VERSION "6.2.2"

NS_ :

BS_:

BU_:

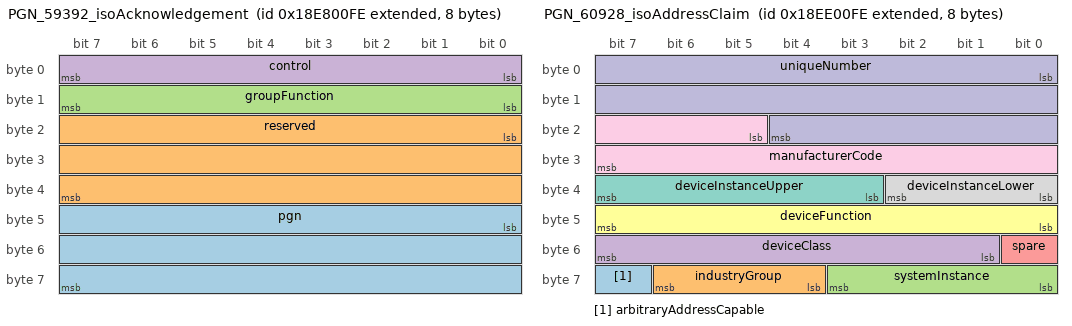
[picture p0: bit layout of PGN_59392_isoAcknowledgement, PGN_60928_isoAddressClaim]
BO_ 2565341438 PGN_59392_isoAcknowledgement: 8 Vector__XXX
 SG_ pgn : 40|24@1+ (1,0) [0|0] "" Vector__XXX
 SG_ reserved : 16|24@1+ (1,0) [0|0] "" Vector__XXX
 SG_ groupFunction : 8|8@1+ (1,0) [0|0] "" Vector__XXX
 SG_ control : 0|8@1+ (1,0) [0|0] "" Vector__XXX

BO_ 2565472510 PGN_59904_isoRequest: 8 Vector__XXX
 SG_ pgn : 0|24@1+ (1,0) [0|0] "" Vector__XXX

BO_ 2565538046 PGN_60160_isoTransportProtocolDa: 8 Vector__XXX
 SG_ data : 8|56@1+ (1,0) [0|0] "" Vector__XXX
 SG_ sid : 0|8@1+ (1,0) [0|0] "" Vector__XXX

BO_ 2565734654 PGN_60928_isoAddressClaim: 8 Vector__XXX
 SG_ arbitraryAddressCapable : 63|1@1+ (1,0) [0|0] "" Vector__XXX
 SG_ industryGroup : 60|3@1+ (1,0) [0|0] "" Vector__XXX
 SG_ systemInstance : 56|4@1+ (1,0) [0|0] "" Vector__XXX
 SG_ deviceClass : 49|7@1+ (1,0) [0|0] "" Vector__XXX
 SG_ spare : 48|1@1+ (1,0) [0|0] "" Vector__XXX
 SG_ deviceFunction : 40|8@1+ (1,0) [0|0] "" Vector__XXX
 SG_ deviceInstanceUpper : 35|5@1+ (1,0) [0|0] "" Vector__XXX
 SG_ deviceInstanceLower : 32|3@1+ (1,0) [0|0] "" Vector__XXX
 SG_ manufacturerCode : 21|11@1+ (1,0) [0|0] "" Vector__XXX
 SG_ uniqueNumber : 0|21@1+ (1,0) [0|0] "" Vector__XXX

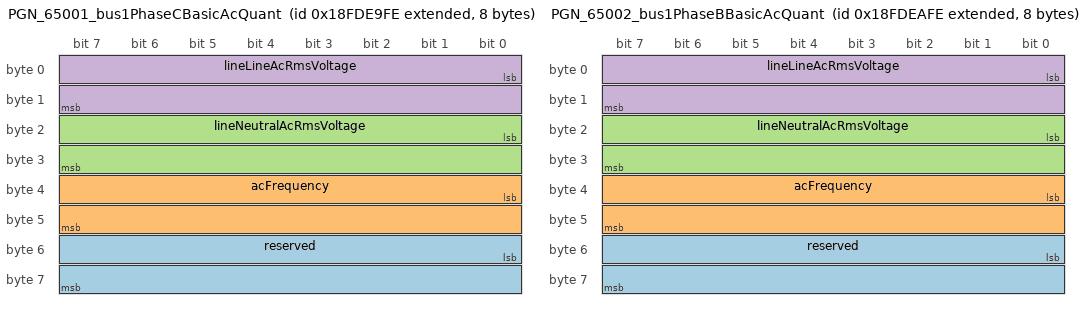
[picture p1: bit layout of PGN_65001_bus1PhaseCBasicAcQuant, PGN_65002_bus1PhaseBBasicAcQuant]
BO_ 2566777342 PGN_65001_bus1PhaseCBasicAcQuant: 8 Vector__XXX
 SG_ reserved : 48|16@1+ (1,0) [0|0] "" Vector__XXX
 SG_ acFrequency : 32|16@1+ (0.0078125,0) [0|0] "Hz" Vector__XXX
 SG_ lineNeutralAcRmsVoltage : 16|16@1+ (1,0) [0|0] "V" Vector__XXX
 SG_ lineLineAcRmsVoltage : 0|16@1+ (1,0) [0|0] "V" Vector__XXX

BO_ 2566777598 PGN_65002_bus1PhaseBBasicAcQuant: 8 Vector__XXX
 SG_ reserved : 48|16@1+ (1,0) [0|0] "" Vector__XXX
 SG_ acFrequency : 32|16@1+ (0.0078125,0) [0|0] "Hz" Vector__XXX
 SG_ lineNeutralAcRmsVoltage : 16|16@1+ (1,0) [0|0] "V" Vector__XXX
 SG_ lineLineAcRmsVoltage : 0|16@1+ (1,0) [0|0] "V" Vector__XXX

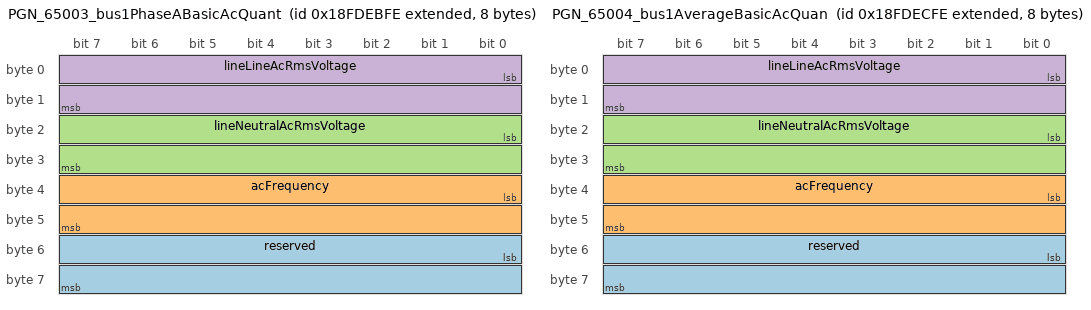
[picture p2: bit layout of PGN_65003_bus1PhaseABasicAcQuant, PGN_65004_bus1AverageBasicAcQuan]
BO_ 2566777854 PGN_65003_bus1PhaseABasicAcQuant: 8 Vector__XXX
 SG_ reserved : 48|16@1+ (1,0) [0|0] "" Vector__XXX
 SG_ acFrequency : 32|16@1+ (0.0078125,0) [0|0] "Hz" Vector__XXX
 SG_ lineNeutralAcRmsVoltage : 16|16@1+ (1,0) [0|0] "V" Vector__XXX
 SG_ lineLineAcRmsVoltage : 0|16@1+ (1,0) [0|0] "V" Vector__XXX

BO_ 2566778110 PGN_65004_bus1AverageBasicAcQuan: 8 Vector__XXX
 SG_ reserved : 48|16@1+ (1,0) [0|0] "" Vector__XXX
 SG_ acFrequency : 32|16@1+ (0.0078125,0) [0|0] "Hz" Vector__XXX
 SG_ lineNeutralAcRmsVoltage : 16|16@1+ (1,0) [0|0] "V" Vector__XXX
 SG_ lineLineAcRmsVoltage : 0|16@1+ (1,0) [0|0] "V" Vector__XXX

BO_ 2566778366 PGN_65005_utilityTotalAcEnergy: 8 Vector__XXX
 SG_ totalEnergyImport : 32|32@1+ (1,0) [0|0] "kWh" Vector__XXX
 SG_ totalEnergyExport : 0|32@1+ (1,0) [0|0] "kWh" Vector__XXX

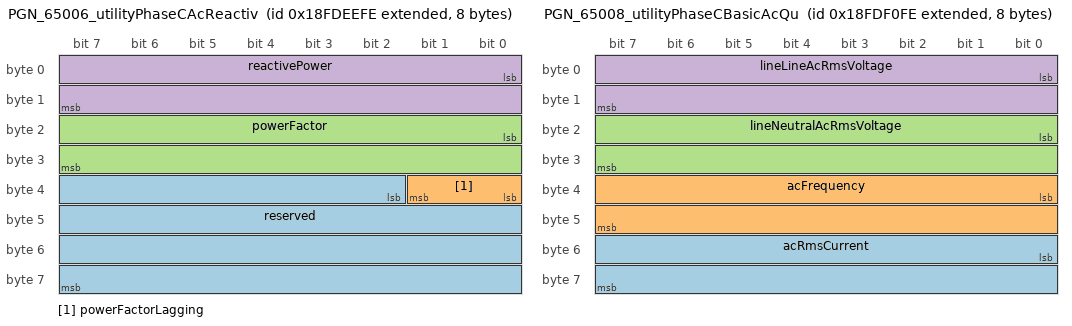
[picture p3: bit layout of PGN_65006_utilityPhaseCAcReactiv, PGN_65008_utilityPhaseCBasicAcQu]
BO_ 2566778622 PGN_65006_utilityPhaseCAcReactiv: 8 Vector__XXX
 SG_ reserved : 34|30@1+ (1,0) [0|0] "" Vector__XXX
 SG_ powerFactorLagging : 32|2@1+ (1,0) [0|0] "" Vector__XXX
 SG_ powerFactor : 16|16@1+ (6.10352e-05,0) [0|0] "Cos Phi" Vector__XXX
 SG_ reactivePower : 0|16@1+ (1,0) [0|0] "VAR" Vector__XXX

BO_ 2566778878 PGN_65007_utilityPhaseCAcPower: 8 Vector__XXX
 SG_ apparentPower : 32|32@1- (1,0) [0|0] "VA" Vector__XXX
 SG_ realPower : 0|32@1- (1,0) [0|0] "W" Vector__XXX

BO_ 2566779134 PGN_65008_utilityPhaseCBasicAcQu: 8 Vector__XXX
 SG_ acRmsCurrent : 48|16@1+ (1,0) [0|0] "A" Vector__XXX
 SG_ acFrequency : 32|16@1+ (0.0078125,0) [0|0] "Hz" Vector__XXX
 SG_ lineNeutralAcRmsVoltage : 16|16@1+ (1,0) [0|0] "V" Vector__XXX
 SG_ lineLineAcRmsVoltage : 0|16@1+ (1,0) [0|0] "V" Vector__XXX

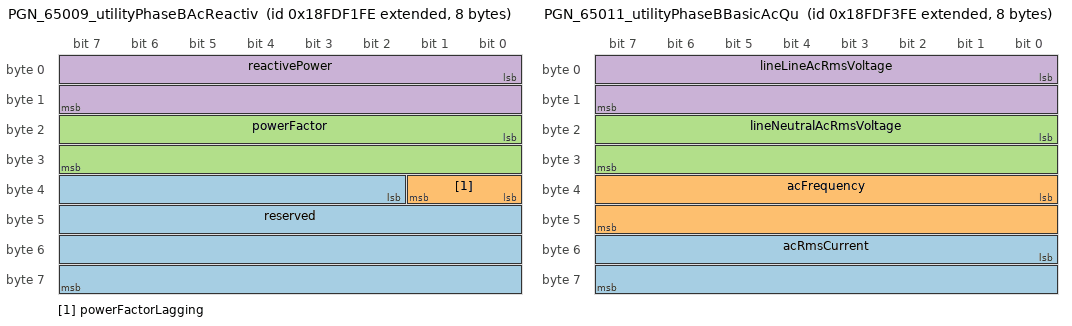
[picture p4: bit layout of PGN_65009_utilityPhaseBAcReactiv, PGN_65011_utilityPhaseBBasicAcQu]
BO_ 2566779390 PGN_65009_utilityPhaseBAcReactiv: 8 Vector__XXX
 SG_ reserved : 34|30@1+ (1,0) [0|0] "" Vector__XXX
 SG_ powerFactorLagging : 32|2@1+ (1,0) [0|0] "" Vector__XXX
 SG_ powerFactor : 16|16@1+ (6.10352e-05,0) [0|0] "Cos Phi" Vector__XXX
 SG_ reactivePower : 0|16@1+ (1,0) [0|0] "VAR" Vector__XXX

BO_ 2566779646 PGN_65010_utilityPhaseBAcPower: 8 Vector__XXX
 SG_ apparentPower : 32|32@1- (1,0) [0|0] "VA" Vector__XXX
 SG_ realPower : 0|32@1- (1,0) [0|0] "W" Vector__XXX

BO_ 2566779902 PGN_65011_utilityPhaseBBasicAcQu: 8 Vector__XXX
 SG_ acRmsCurrent : 48|16@1+ (1,0) [0|0] "A" Vector__XXX
 SG_ acFrequency : 32|16@1+ (0.0078125,0) [0|0] "Hz" Vector__XXX
 SG_ lineNeutralAcRmsVoltage : 16|16@1+ (1,0) [0|0] "V" Vector__XXX
 SG_ lineLineAcRmsVoltage : 0|16@1+ (1,0) [0|0] "V" Vector__XXX

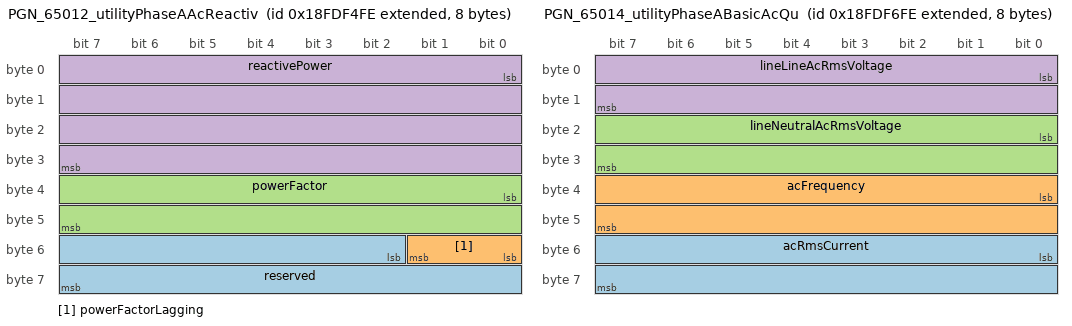
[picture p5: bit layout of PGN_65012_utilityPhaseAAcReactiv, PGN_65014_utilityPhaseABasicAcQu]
BO_ 2566780158 PGN_65012_utilityPhaseAAcReactiv: 8 Vector__XXX
 SG_ reserved : 50|14@1+ (1,0) [0|0] "" Vector__XXX
 SG_ powerFactorLagging : 48|2@1+ (1,0) [0|0] "" Vector__XXX
 SG_ powerFactor : 32|16@1+ (6.10352e-05,0) [0|0] "Cos Phi" Vector__XXX
 SG_ reactivePower : 0|32@1- (1,0) [0|0] "VAR" Vector__XXX

BO_ 2566780414 PGN_65013_utilityPhaseAAcPower: 8 Vector__XXX
 SG_ apparentPower : 32|32@1- (1,0) [0|0] "VA" Vector__XXX
 SG_ realPower : 0|32@1- (1,0) [0|0] "W" Vector__XXX

BO_ 2566780670 PGN_65014_utilityPhaseABasicAcQu: 8 Vector__XXX
 SG_ acRmsCurrent : 48|16@1+ (1,0) [0|0] "A" Vector__XXX
 SG_ acFrequency : 32|16@1+ (0.0078125,0) [0|0] "Hz" Vector__XXX
 SG_ lineNeutralAcRmsVoltage : 16|16@1+ (1,0) [0|0] "V" Vector__XXX
 SG_ lineLineAcRmsVoltage : 0|16@1+ (1,0) [0|0] "V" Vector__XXX

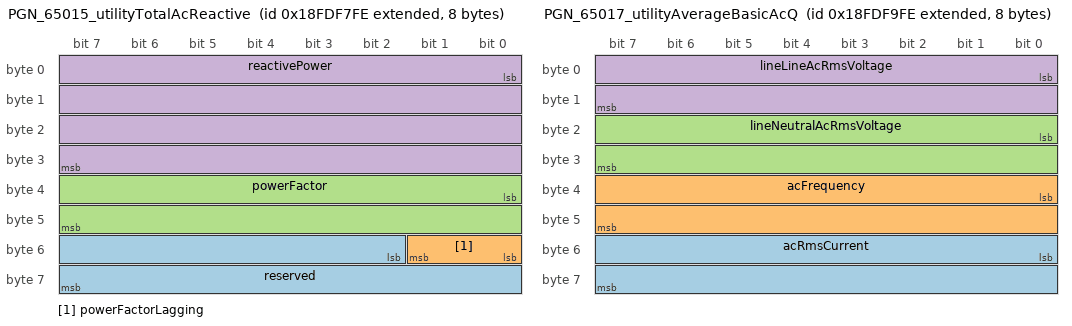
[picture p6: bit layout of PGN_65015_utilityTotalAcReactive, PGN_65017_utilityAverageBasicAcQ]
BO_ 2566780926 PGN_65015_utilityTotalAcReactive: 8 Vector__XXX
 SG_ reserved : 50|14@1+ (1,0) [0|0] "" Vector__XXX
 SG_ powerFactorLagging : 48|2@1+ (1,0) [0|0] "" Vector__XXX
 SG_ powerFactor : 32|16@1+ (6.10352e-05,0) [0|0] "Cos Phi" Vector__XXX
 SG_ reactivePower : 0|32@1- (1,0) [0|0] "VAR" Vector__XXX

BO_ 2566781182 PGN_65016_utilityTotalAcPower: 8 Vector__XXX
 SG_ apparentPower : 32|32@1- (1,0) [0|0] "VA" Vector__XXX
 SG_ realPower : 0|32@1- (1,0) [0|0] "W" Vector__XXX

BO_ 2566781438 PGN_65017_utilityAverageBasicAcQ: 8 Vector__XXX
 SG_ acRmsCurrent : 48|16@1+ (1,0) [0|0] "A" Vector__XXX
 SG_ acFrequency : 32|16@1+ (0.0078125,0) [0|0] "Hz" Vector__XXX
 SG_ lineNeutralAcRmsVoltage : 16|16@1+ (1,0) [0|0] "V" Vector__XXX
 SG_ lineLineAcRmsVoltage : 0|16@1+ (1,0) [0|0] "V" Vector__XXX

BO_ 2566781694 PGN_65018_generatorTotalAcEnergy: 8 Vector__XXX
 SG_ totalEnergyImport : 32|32@1+ (1,0) [0|0] "kWh" Vector__XXX
 SG_ totalEnergyExport : 0|32@1+ (1,0) [0|0] "kWh" Vector__XXX

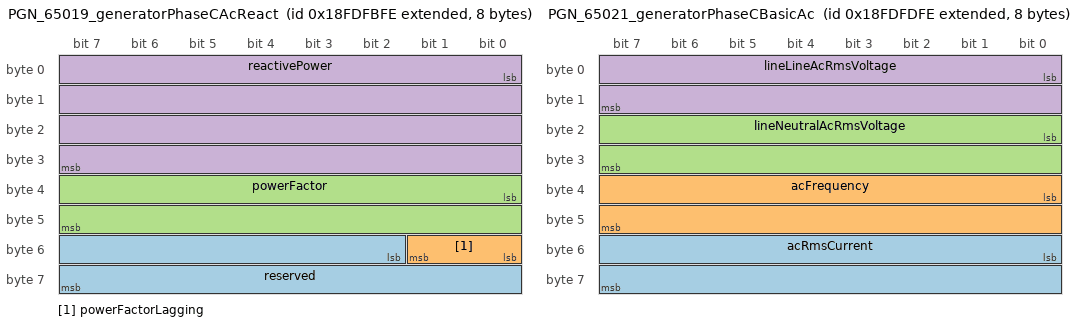
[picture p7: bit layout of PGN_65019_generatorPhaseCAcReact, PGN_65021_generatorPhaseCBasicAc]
BO_ 2566781950 PGN_65019_generatorPhaseCAcReact: 8 Vector__XXX
 SG_ reserved : 50|14@1+ (1,0) [0|0] "" Vector__XXX
 SG_ powerFactorLagging : 48|2@1+ (1,0) [0|0] "" Vector__XXX
 SG_ powerFactor : 32|16@1+ (6.10352e-05,0) [0|0] "Cos Phi" Vector__XXX
 SG_ reactivePower : 0|32@1- (1,0) [0|0] "VAR" Vector__XXX

BO_ 2566782206 PGN_65020_generatorPhaseCAcPower: 8 Vector__XXX
 SG_ apparentPower : 32|32@1- (1,0) [0|0] "VAR" Vector__XXX
 SG_ realPower : 0|32@1- (1,0) [0|0] "W" Vector__XXX

BO_ 2566782462 PGN_65021_generatorPhaseCBasicAc: 8 Vector__XXX
 SG_ acRmsCurrent : 48|16@1+ (1,0) [0|0] "A" Vector__XXX
 SG_ acFrequency : 32|16@1+ (0.0078125,0) [0|0] "Hz" Vector__XXX
 SG_ lineNeutralAcRmsVoltage : 16|16@1+ (1,0) [0|0] "V" Vector__XXX
 SG_ lineLineAcRmsVoltage : 0|16@1+ (1,0) [0|0] "V" Vector__XXX

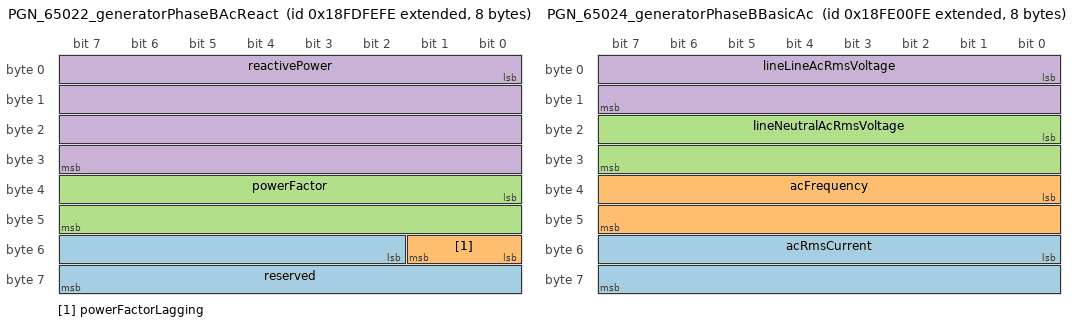
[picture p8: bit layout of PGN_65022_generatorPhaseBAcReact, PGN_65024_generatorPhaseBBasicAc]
BO_ 2566782718 PGN_65022_generatorPhaseBAcReact: 8 Vector__XXX
 SG_ reserved : 50|14@1+ (1,0) [0|0] "" Vector__XXX
 SG_ powerFactorLagging : 48|2@1+ (1,0) [0|0] "" Vector__XXX
 SG_ powerFactor : 32|16@1+ (6.10352e-05,0) [0|0] "Cos Phi" Vector__XXX
 SG_ reactivePower : 0|32@1- (1,0) [0|0] "VAR" Vector__XXX

BO_ 2566782974 PGN_65023_generatorPhaseBAcPower: 8 Vector__XXX
 SG_ apparentPower : 32|32@1- (1,0) [0|0] "VA" Vector__XXX
 SG_ realPower : 0|32@1- (1,0) [0|0] "W" Vector__XXX

BO_ 2566783230 PGN_65024_generatorPhaseBBasicAc: 8 Vector__XXX
 SG_ acRmsCurrent : 48|16@1+ (1,0) [0|0] "A" Vector__XXX
 SG_ acFrequency : 32|16@1+ (0.0078125,0) [0|0] "Hz" Vector__XXX
 SG_ lineNeutralAcRmsVoltage : 16|16@1+ (1,0) [0|0] "V" Vector__XXX
 SG_ lineLineAcRmsVoltage : 0|16@1+ (1,0) [0|0] "V" Vector__XXX

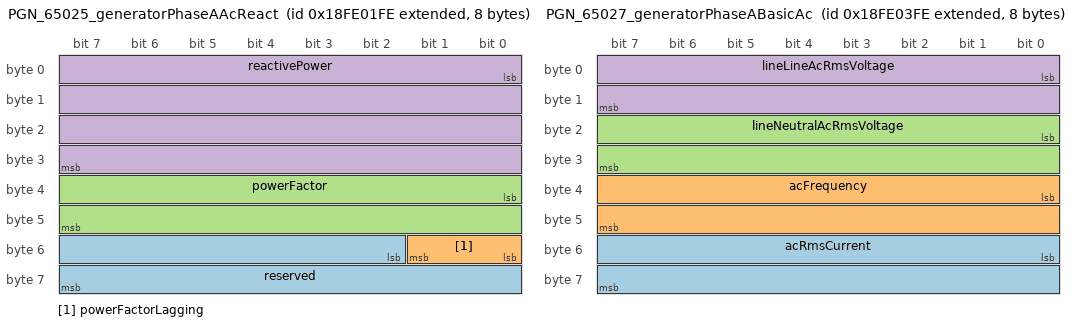
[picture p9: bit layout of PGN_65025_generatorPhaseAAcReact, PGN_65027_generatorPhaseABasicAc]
BO_ 2566783486 PGN_65025_generatorPhaseAAcReact: 8 Vector__XXX
 SG_ reserved : 50|14@1+ (1,0) [0|0] "" Vector__XXX
 SG_ powerFactorLagging : 48|2@1+ (1,0) [0|0] "" Vector__XXX
 SG_ powerFactor : 32|16@1+ (6.10352e-05,0) [0|0] "Cos Phi" Vector__XXX
 SG_ reactivePower : 0|32@1- (1,0) [0|0] "VAR" Vector__XXX

BO_ 2566783742 PGN_65026_generatorPhaseAAcPower: 8 Vector__XXX
 SG_ apparentPower : 32|32@1- (1,0) [0|0] "VA" Vector__XXX
 SG_ realPower : 0|32@1- (1,0) [0|0] "W" Vector__XXX

BO_ 2566783998 PGN_65027_generatorPhaseABasicAc: 8 Vector__XXX
 SG_ acRmsCurrent : 48|16@1+ (1,0) [0|0] "A" Vector__XXX
 SG_ acFrequency : 32|16@1+ (0.0078125,0) [0|0] "Hz" Vector__XXX
 SG_ lineNeutralAcRmsVoltage : 16|16@1+ (1,0) [0|0] "V" Vector__XXX
 SG_ lineLineAcRmsVoltage : 0|16@1+ (1,0) [0|0] "V" Vector__XXX

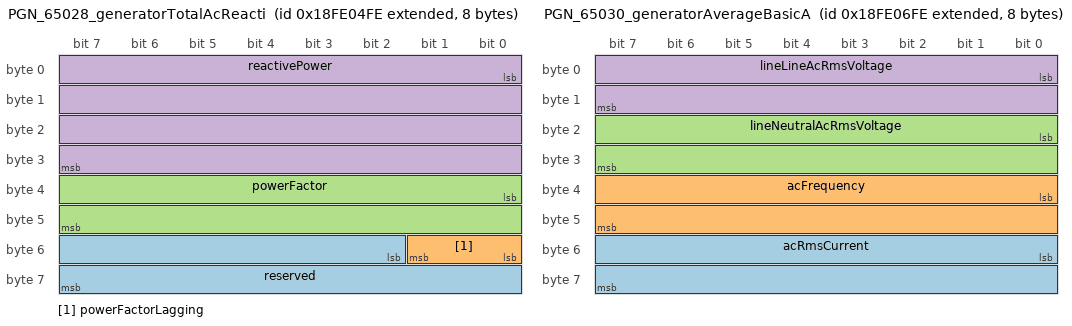
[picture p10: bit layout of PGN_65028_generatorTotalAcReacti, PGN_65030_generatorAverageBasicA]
BO_ 2566784254 PGN_65028_generatorTotalAcReacti: 8 Vector__XXX
 SG_ reserved : 50|14@1+ (1,0) [0|0] "" Vector__XXX
 SG_ powerFactorLagging : 48|2@1+ (1,0) [0|0] "" Vector__XXX
 SG_ powerFactor : 32|16@1+ (6.10352e-05,0) [0|0] "Cos Phi" Vector__XXX
 SG_ reactivePower : 0|32@1- (1,0) [0|0] "VAR" Vector__XXX

BO_ 2566784510 PGN_65029_generatorTotalAcPower: 8 Vector__XXX
 SG_ apparentPower : 32|32@1- (1,0) [0|0] "VA" Vector__XXX
 SG_ realPower : 0|32@1- (1,0) [0|0] "W" Vector__XXX

BO_ 2566784766 PGN_65030_generatorAverageBasicA: 8 Vector__XXX
 SG_ acRmsCurrent : 48|16@1+ (1,0) [0|0] "A" Vector__XXX
 SG_ acFrequency : 32|16@1+ (0.0078125,0) [0|0] "Hz" Vector__XXX
 SG_ lineNeutralAcRmsVoltage : 16|16@1+ (1,0) [0|0] "V" Vector__XXX
 SG_ lineLineAcRmsVoltage : 0|16@1+ (1,0) [0|0] "V" Vector__XXX

BO_ 2566849534 PGN_65283_bepMarineCzoneChannelS: 8 Vector__XXX
 SG_ reserved18 : 61|3@1+ (1,0) [0|0] "" Vector__XXX
 SG_ flag : 60|1@1+ (1,0) [0|0] "" Vector__XXX
 SG_ channel5Value : 56|4@1+ (1,0) [0|0] "" Vector__XXX
 SG_ channel4Value : 52|4@1+ (1,0) [0|0] "" Vector__XXX
 SG_ channel3Value : 48|4@1+ (1,0) [0|0] "" Vector__XXX
 SG_ channel2Value : 44|4@1+ (1,0) [0|0] "" Vector__XXX
 SG_ channel1Value : 40|4@1+ (1,0) [0|0] "" Vector__XXX
 SG_ channel0Value : 36|4@1+ (1,0) [0|0] "" Vector__XXX
 SG_ channel5Mode : 34|2@1+ (1,0) [0|0] "" Vector__XXX
 SG_ channel4Mode : 32|2@1+ (1,0) [0|0] "" Vector__XXX
 SG_ channel3Mode : 30|2@1+ (1,0) [0|0] "" Vector__XXX
 SG_ channel2Mode : 28|2@1+ (1,0) [0|0] "" Vector__XXX
 SG_ channel1Mode : 26|2@1+ (1,0) [0|0] "" Vector__XXX
 SG_ channel0Mode : 24|2@1+ (1,0) [0|0] "" Vector__XXX
 SG_ dipswitch : 16|8@1+ (1,0) [0|0] "" Vector__XXX
 SG_ industryCode : 13|3@1+ (1,0) [0|0] "" Vector__XXX
 SG_ reserved : 11|2@1+ (1,0) [0|0] "" Vector__XXX
 SG_ manufacturerCode : 0|11@1+ (1,0) [0|0] "" Vector__XXX

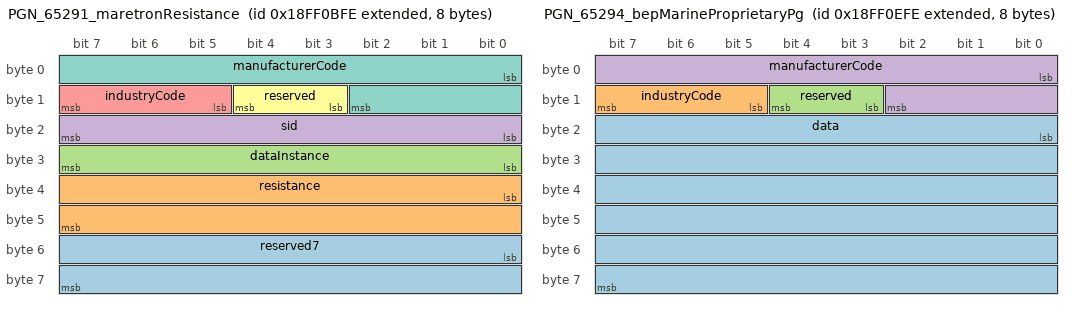
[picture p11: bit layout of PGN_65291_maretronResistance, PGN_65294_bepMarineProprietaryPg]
BO_ 2566851582 PGN_65291_maretronResistance: 8 Vector__XXX
 SG_ reserved7 : 48|16@1+ (1,0) [0|0] "" Vector__XXX
 SG_ resistance : 32|16@1+ (0.01,0) [0|0] "" Vector__XXX
 SG_ dataInstance : 24|8@1+ (1,0) [0|0] "" Vector__XXX
 SG_ sid : 16|8@1+ (1,0) [0|0] "" Vector__XXX
 SG_ industryCode : 13|3@1+ (1,0) [0|0] "" Vector__XXX
 SG_ reserved : 11|2@1+ (1,0) [0|0] "" Vector__XXX
 SG_ manufacturerCode : 0|11@1+ (1,0) [0|0] "" Vector__XXX

BO_ 2566852350 PGN_65294_bepMarineProprietaryPg: 8 Vector__XXX
 SG_ data : 16|48@1+ (1,0) [0|0] "" Vector__XXX
 SG_ industryCode : 13|3@1+ (1,0) [0|0] "" Vector__XXX
 SG_ reserved : 11|2@1+ (1,0) [0|0] "" Vector__XXX
 SG_ manufacturerCode : 0|11@1+ (1,0) [0|0] "" Vector__XXX

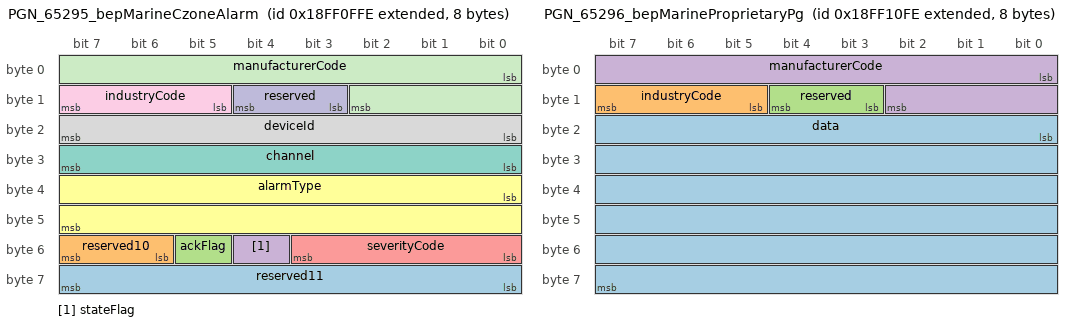
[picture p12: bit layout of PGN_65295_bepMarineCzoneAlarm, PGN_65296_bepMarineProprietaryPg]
BO_ 2566852606 PGN_65295_bepMarineCzoneAlarm: 8 Vector__XXX
 SG_ reserved11 : 56|8@1+ (1,0) [0|0] "" Vector__XXX
 SG_ reserved10 : 54|2@1+ (1,0) [0|0] "" Vector__XXX
 SG_ ackFlag : 53|1@1+ (1,0) [0|0] "" Vector__XXX
 SG_ stateFlag : 52|1@1+ (1,0) [0|0] "" Vector__XXX
 SG_ severityCode : 48|4@1+ (1,0) [0|0] "" Vector__XXX
 SG_ alarmType : 32|16@1+ (1,0) [0|0] "" Vector__XXX
 SG_ channel : 24|8@1+ (1,0) [0|0] "" Vector__XXX
 SG_ deviceId : 16|8@1+ (1,0) [0|0] "" Vector__XXX
 SG_ industryCode : 13|3@1+ (1,0) [0|0] "" Vector__XXX
 SG_ reserved : 11|2@1+ (1,0) [0|0] "" Vector__XXX
 SG_ manufacturerCode : 0|11@1+ (1,0) [0|0] "" Vector__XXX

BO_ 2566852862 PGN_65296_bepMarineProprietaryPg: 8 Vector__XXX
 SG_ data : 16|48@1+ (1,0) [0|0] "" Vector__XXX
 SG_ industryCode : 13|3@1+ (1,0) [0|0] "" Vector__XXX
 SG_ reserved : 11|2@1+ (1,0) [0|0] "" Vector__XXX
 SG_ manufacturerCode : 0|11@1+ (1,0) [0|0] "" Vector__XXX

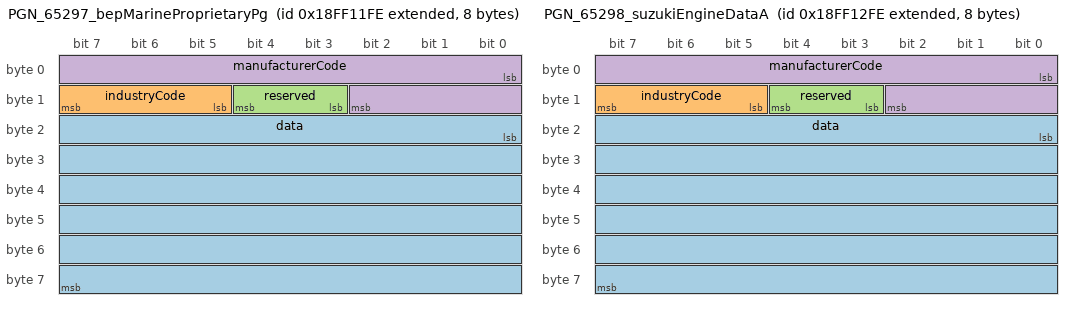
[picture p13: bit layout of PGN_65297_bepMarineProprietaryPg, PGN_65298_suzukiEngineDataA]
BO_ 2566853118 PGN_65297_bepMarineProprietaryPg: 8 Vector__XXX
 SG_ data : 16|48@1+ (1,0) [0|0] "" Vector__XXX
 SG_ industryCode : 13|3@1+ (1,0) [0|0] "" Vector__XXX
 SG_ reserved : 11|2@1+ (1,0) [0|0] "" Vector__XXX
 SG_ manufacturerCode : 0|11@1+ (1,0) [0|0] "" Vector__XXX

BO_ 2566853374 PGN_65298_suzukiEngineDataA: 8 Vector__XXX
 SG_ data : 16|48@1+ (1,0) [0|0] "" Vector__XXX
 SG_ industryCode : 13|3@1+ (1,0) [0|0] "" Vector__XXX
 SG_ reserved : 11|2@1+ (1,0) [0|0] "" Vector__XXX
 SG_ manufacturerCode : 0|11@1+ (1,0) [0|0] "" Vector__XXX

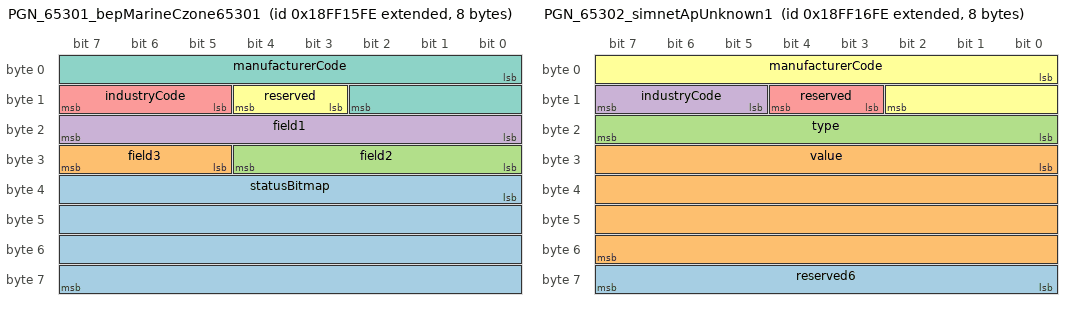
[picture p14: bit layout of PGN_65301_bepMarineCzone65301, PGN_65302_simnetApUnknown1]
BO_ 2566854142 PGN_65301_bepMarineCzone65301: 8 Vector__XXX
 SG_ statusBitmap : 32|32@1+ (1,0) [0|0] "" Vector__XXX
 SG_ field3 : 29|3@1+ (1,0) [0|0] "" Vector__XXX
 SG_ field2 : 24|5@1+ (1,0) [0|0] "" Vector__XXX
 SG_ field1 : 16|8@1+ (1,0) [0|0] "" Vector__XXX
 SG_ industryCode : 13|3@1+ (1,0) [0|0] "" Vector__XXX
 SG_ reserved : 11|2@1+ (1,0) [0|0] "" Vector__XXX
 SG_ manufacturerCode : 0|11@1+ (1,0) [0|0] "" Vector__XXX

BO_ 2566854398 PGN_65302_simnetApUnknown1: 8 Vector__XXX
 SG_ reserved6 : 56|8@1+ (1,0) [0|0] "" Vector__XXX
 SG_ value : 24|32@1+ (1,0) [0|0] "" Vector__XXX
 SG_ type : 16|8@1+ (1,0) [0|0] "" Vector__XXX
 SG_ industryCode : 13|3@1+ (1,0) [0|0] "" Vector__XXX
 SG_ reserved : 11|2@1+ (1,0) [0|0] "" Vector__XXX
 SG_ manufacturerCode : 0|11@1+ (1,0) [0|0] "" Vector__XXX

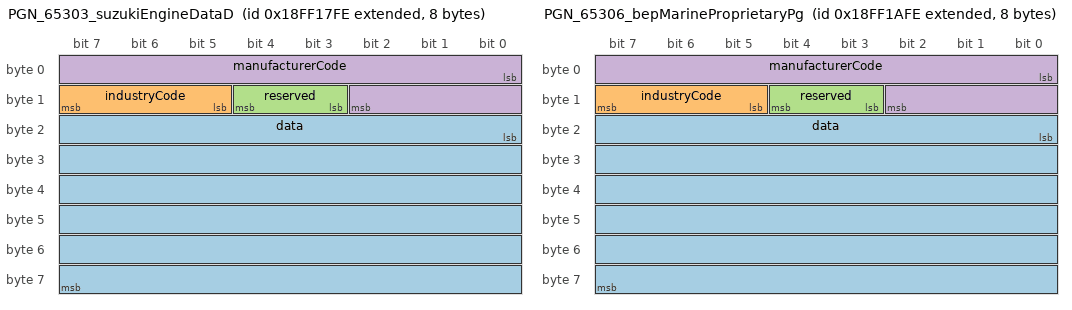
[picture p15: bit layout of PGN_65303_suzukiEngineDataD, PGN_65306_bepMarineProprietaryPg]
BO_ 2566854654 PGN_65303_suzukiEngineDataD: 8 Vector__XXX
 SG_ data : 16|48@1+ (1,0) [0|0] "" Vector__XXX
 SG_ industryCode : 13|3@1+ (1,0) [0|0] "" Vector__XXX
 SG_ reserved : 11|2@1+ (1,0) [0|0] "" Vector__XXX
 SG_ manufacturerCode : 0|11@1+ (1,0) [0|0] "" Vector__XXX

BO_ 2566855422 PGN_65306_bepMarineProprietaryPg: 8 Vector__XXX
 SG_ data : 16|48@1+ (1,0) [0|0] "" Vector__XXX
 SG_ industryCode : 13|3@1+ (1,0) [0|0] "" Vector__XXX
 SG_ reserved : 11|2@1+ (1,0) [0|0] "" Vector__XXX
 SG_ manufacturerCode : 0|11@1+ (1,0) [0|0] "" Vector__XXX

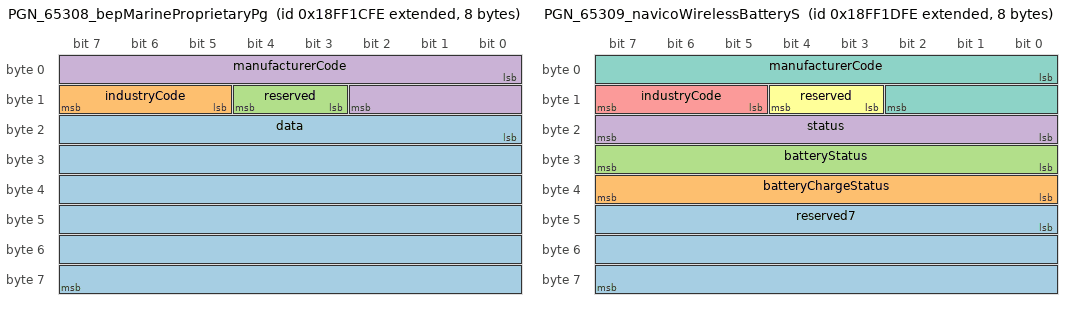
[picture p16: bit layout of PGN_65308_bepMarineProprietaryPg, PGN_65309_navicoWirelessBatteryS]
BO_ 2566855934 PGN_65308_bepMarineProprietaryPg: 8 Vector__XXX
 SG_ data : 16|48@1+ (1,0) [0|0] "" Vector__XXX
 SG_ industryCode : 13|3@1+ (1,0) [0|0] "" Vector__XXX
 SG_ reserved : 11|2@1+ (1,0) [0|0] "" Vector__XXX
 SG_ manufacturerCode : 0|11@1+ (1,0) [0|0] "" Vector__XXX

BO_ 2566856190 PGN_65309_navicoWirelessBatteryS: 8 Vector__XXX
 SG_ reserved7 : 40|24@1+ (1,0) [0|0] "" Vector__XXX
 SG_ batteryChargeStatus : 32|8@1+ (1,0) [0|0] "%" Vector__XXX
 SG_ batteryStatus : 24|8@1+ (1,0) [0|0] "%" Vector__XXX
 SG_ status : 16|8@1+ (1,0) [0|0] "" Vector__XXX
 SG_ industryCode : 13|3@1+ (1,0) [0|0] "" Vector__XXX
 SG_ reserved : 11|2@1+ (1,0) [0|0] "" Vector__XXX
 SG_ manufacturerCode : 0|11@1+ (1,0) [0|0] "" Vector__XXX

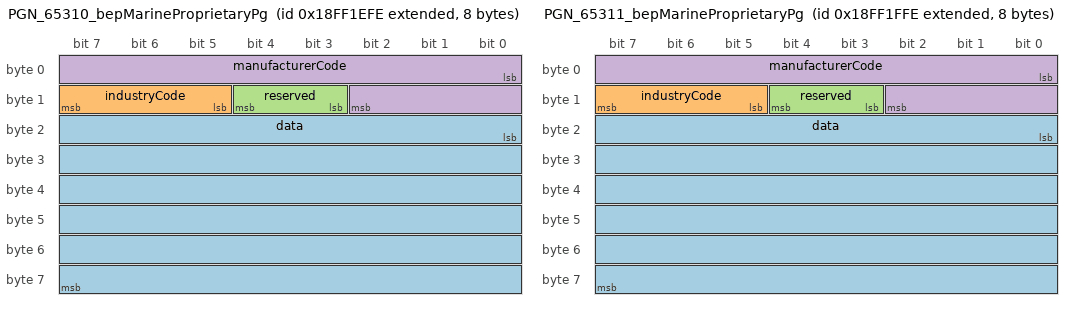
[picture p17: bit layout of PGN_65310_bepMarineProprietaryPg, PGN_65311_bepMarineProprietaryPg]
BO_ 2566856446 PGN_65310_bepMarineProprietaryPg: 8 Vector__XXX
 SG_ data : 16|48@1+ (1,0) [0|0] "" Vector__XXX
 SG_ industryCode : 13|3@1+ (1,0) [0|0] "" Vector__XXX
 SG_ reserved : 11|2@1+ (1,0) [0|0] "" Vector__XXX
 SG_ manufacturerCode : 0|11@1+ (1,0) [0|0] "" Vector__XXX

BO_ 2566856702 PGN_65311_bepMarineProprietaryPg: 8 Vector__XXX
 SG_ data : 16|48@1+ (1,0) [0|0] "" Vector__XXX
 SG_ industryCode : 13|3@1+ (1,0) [0|0] "" Vector__XXX
 SG_ reserved : 11|2@1+ (1,0) [0|0] "" Vector__XXX
 SG_ manufacturerCode : 0|11@1+ (1,0) [0|0] "" Vector__XXX

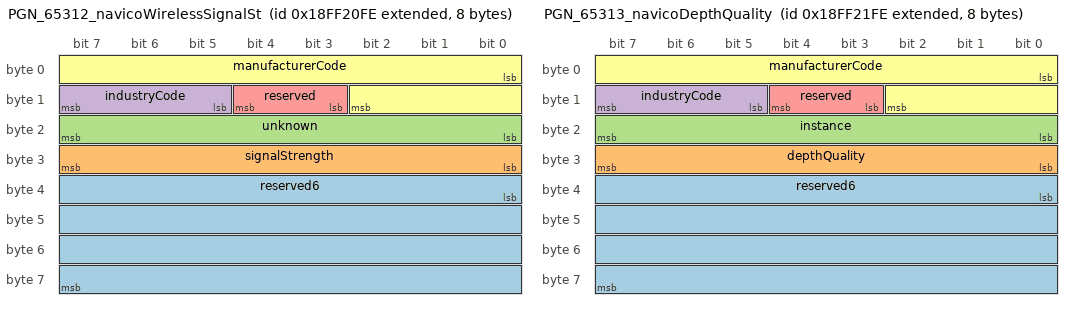
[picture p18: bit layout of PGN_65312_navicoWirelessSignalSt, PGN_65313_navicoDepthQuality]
BO_ 2566856958 PGN_65312_navicoWirelessSignalSt: 8 Vector__XXX
 SG_ reserved6 : 32|32@1+ (1,0) [0|0] "" Vector__XXX
 SG_ signalStrength : 24|8@1+ (1,0) [0|0] "%" Vector__XXX
 SG_ unknown : 16|8@1+ (1,0) [0|0] "" Vector__XXX
 SG_ industryCode : 13|3@1+ (1,0) [0|0] "" Vector__XXX
 SG_ reserved : 11|2@1+ (1,0) [0|0] "" Vector__XXX
 SG_ manufacturerCode : 0|11@1+ (1,0) [0|0] "" Vector__XXX

BO_ 2566857214 PGN_65313_navicoDepthQuality: 8 Vector__XXX
 SG_ reserved6 : 32|32@1+ (1,0) [0|0] "" Vector__XXX
 SG_ depthQuality : 24|8@1- (0.01,0) [0|0] "" Vector__XXX
 SG_ instance : 16|8@1+ (1,0) [0|0] "" Vector__XXX
 SG_ industryCode : 13|3@1+ (1,0) [0|0] "" Vector__XXX
 SG_ reserved : 11|2@1+ (1,0) [0|0] "" Vector__XXX
 SG_ manufacturerCode : 0|11@1+ (1,0) [0|0] "" Vector__XXX

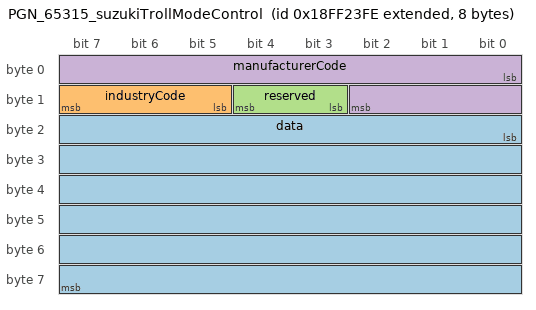
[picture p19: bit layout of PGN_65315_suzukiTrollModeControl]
BO_ 2566857726 PGN_65315_suzukiTrollModeControl: 8 Vector__XXX
 SG_ data : 16|48@1+ (1,0) [0|0] "" Vector__XXX
 SG_ industryCode : 13|3@1+ (1,0) [0|0] "" Vector__XXX
 SG_ reserved : 11|2@1+ (1,0) [0|0] "" Vector__XXX
 SG_ manufacturerCode : 0|11@1+ (1,0) [0|0] "" Vector__XXX

CM_ BO_ 2565341438 "ISO Acknowledgement";
CM_ SG_ 2565341438 pgn "Parameter Group Number of requested information";
CM_ BO_ 2565472510 "ISO Request";
CM_ BO_ 2565538046 "ISO Transport Protocol, Data Transfer";
CM_ SG_ 2565538046 data "Multi-packet packetized data - 56 bits organized as seven 8-bit bytes, each of the bytes is transmitted in the same order as it would in a standard (i.e., single frame) message. Unused bytes shall be filled with 0xFF.";
CM_ SG_ 2565538046 sid "Sequence number of multi-packet frame";
CM_ BO_ 2565734654 "ISO Address Claim";
CM_ SG_ 2565734654 arbitraryAddressCapable "Field indicates whether the device is capable to claim arbitrary source address. Value is 1 for NMEA200 devices. Could be 0 for J1939 device claims";
CM_ SG_ 2565734654 systemInstance "ISO Device Class Instance";
CM_ SG_ 2565734654 deviceFunction "ISO Function";
CM_ SG_ 2565734654 deviceInstanceUpper "ISO Function Instance";
CM_ SG_ 2565734654 deviceInstanceLower "ISO ECU Instance";
CM_ SG_ 2565734654 uniqueNumber "ISO Identity Number";
CM_ BO_ 2566777342 "Bus #1 Phase C Basic AC Quantities";
CM_ BO_ 2566777598 "Bus #1 Phase B Basic AC Quantities";
CM_ BO_ 2566777854 "Bus #1 Phase A Basic AC Quantities";
CM_ BO_ 2566778110 "Bus #1 Average Basic AC Quantities";
CM_ BO_ 2566778366 "Utility Total AC Energy";
CM_ BO_ 2566778622 "Utility Phase C AC Reactive Power";
CM_ BO_ 2566778878 "Utility Phase C AC Power";
CM_ BO_ 2566779134 "Utility Phase C Basic AC Quantities";
CM_ BO_ 2566779390 "Utility Phase B AC Reactive Power";
CM_ BO_ 2566779646 "Utility Phase B AC Power";
CM_ BO_ 2566779902 "Utility Phase B Basic AC Quantities";
CM_ BO_ 2566780158 "Utility Phase A AC Reactive Power";
CM_ BO_ 2566780414 "Utility Phase A AC Power";
CM_ BO_ 2566780670 "Utility Phase A Basic AC Quantities";
CM_ BO_ 2566780926 "Utility Total AC Reactive Power";
CM_ BO_ 2566781182 "Utility Total AC Power";
CM_ BO_ 2566781438 "Utility Average Basic AC Quantities";
CM_ BO_ 2566781694 "Generator Total AC Energy";
CM_ BO_ 2566781950 "Generator Phase C AC Reactive Power";
CM_ BO_ 2566782206 "Generator Phase C AC Power";
CM_ BO_ 2566782462 "Generator Phase C Basic AC Quantities";
CM_ BO_ 2566782718 "Generator Phase B AC Reactive Power";
CM_ BO_ 2566782974 "Generator Phase B AC Power";
CM_ BO_ 2566783230 "Generator Phase B Basic AC Quantities";
CM_ BO_ 2566783486 "Generator Phase A AC Reactive Power";
CM_ BO_ 2566783742 "Generator Phase A AC Power";
CM_ BO_ 2566783998 "Generator Phase A Basic AC Quantities";
CM_ BO_ 2566784254 "Generator Total AC Reactive Power";
CM_ BO_ 2566784510 "Generator Total AC Power";
CM_ BO_ 2566784766 "Generator Average Basic AC Quantities";
CM_ BO_ 2566849534 "BEP Marine: CZone Channel State";
CM_ SG_ 2566849534 flag "Single boolean flag; purpose unverified";
CM_ SG_ 2566849534 channel5Value "4-bit per-channel value; likely dim level (0..15) or state code";
CM_ SG_ 2566849534 channel4Value "4-bit per-channel value; likely dim level (0..15) or state code";
CM_ SG_ 2566849534 channel3Value "4-bit per-channel value; likely dim level (0..15) or state code";
CM_ SG_ 2566849534 channel2Value "4-bit per-channel value; likely dim level (0..15) or state code";
CM_ SG_ 2566849534 channel1Value "4-bit per-channel value; likely dim level (0..15) or state code";
CM_ SG_ 2566849534 channel0Value "4-bit per-channel value; likely dim level (0..15) or state code";
CM_ SG_ 2566849534 channel5Mode "Likely circuit type / fault state; per-bit semantics unverified";
CM_ SG_ 2566849534 channel4Mode "Likely circuit type / fault state; per-bit semantics unverified";
CM_ SG_ 2566849534 channel3Mode "Likely circuit type / fault state; per-bit semantics unverified";
CM_ SG_ 2566849534 channel2Mode "Likely circuit type / fault state; per-bit semantics unverified";
CM_ SG_ 2566849534 channel1Mode "Likely circuit type / fault state; per-bit semantics unverified";
CM_ SG_ 2566849534 channel0Mode "Likely circuit type / fault state; per-bit semantics unverified";
CM_ SG_ 2566849534 industryCode "Marine Industry";
CM_ SG_ 2566849534 manufacturerCode "BEP Marine 2";
CM_ BO_ 2566851582 "Maretron: Resistance";
CM_ SG_ 2566851582 industryCode "Marine Industry";
CM_ SG_ 2566851582 manufacturerCode "Maretron";
CM_ BO_ 2566852350 "BEP Marine: Proprietary PGN 65294";
CM_ SG_ 2566852350 industryCode "Marine Industry";
CM_ SG_ 2566852350 manufacturerCode "BEP Marine 2";
CM_ BO_ 2566852606 "BEP Marine: CZone Alarm";
CM_ SG_ 2566852606 ackFlag "Packed and transmitted by CZone, but receive-side action is not confirmed";
CM_ SG_ 2566852606 stateFlag "State bit used by CZone to distinguish active vs cleared/acknowledged state";
CM_ SG_ 2566852606 severityCode "Raw CZone severity code; values 1..5 map to internal severities 4..0";
CM_ SG_ 2566852606 channel "Channel / alarm id low byte";
CM_ SG_ 2566852606 deviceId "Device / source module id";
CM_ SG_ 2566852606 industryCode "Marine Industry";
CM_ SG_ 2566852606 manufacturerCode "BEP Marine 2";
CM_ BO_ 2566852862 "BEP Marine: Proprietary PGN 65296";
CM_ SG_ 2566852862 industryCode "Marine Industry";
CM_ SG_ 2566852862 manufacturerCode "BEP Marine 2";
CM_ BO_ 2566853118 "BEP Marine: Proprietary PGN 65297";
CM_ SG_ 2566853118 industryCode "Marine Industry";
CM_ SG_ 2566853118 manufacturerCode "BEP Marine 2";
CM_ BO_ 2566853374 "Suzuki: Engine Data A";
CM_ SG_ 2566853374 industryCode "Marine Industry";
CM_ SG_ 2566853374 manufacturerCode "Suzuki Motor Corporation";
CM_ BO_ 2566854142 "BEP Marine: CZone 65301";
CM_ SG_ 2566854142 statusBitmap "32-bit bitmap, LSB-first; bit n set => item n active. Per-bit meaning unverified.";
CM_ SG_ 2566854142 field3 "3-bit field; purpose unverified";
CM_ SG_ 2566854142 field2 "5-bit field; purpose unverified";
CM_ SG_ 2566854142 field1 "Pass-through byte; purpose unverified";
CM_ SG_ 2566854142 industryCode "Marine Industry";
CM_ SG_ 2566854142 manufacturerCode "BEP Marine 2";
CM_ BO_ 2566854398 "Simnet: AP Unknown 1";
CM_ SG_ 2566854398 type "Always 0x0A";
CM_ SG_ 2566854398 industryCode "Marine Industry";
CM_ SG_ 2566854398 manufacturerCode "Simrad";
CM_ BO_ 2566854654 "Suzuki: Engine Data D";
CM_ SG_ 2566854654 industryCode "Marine Industry";
CM_ SG_ 2566854654 manufacturerCode "Suzuki Motor Corporation";
CM_ BO_ 2566855422 "BEP Marine: Proprietary PGN 65306";
CM_ SG_ 2566855422 industryCode "Marine Industry";
CM_ SG_ 2566855422 manufacturerCode "BEP Marine 2";
CM_ BO_ 2566855934 "BEP Marine: Proprietary PGN 65308";
CM_ SG_ 2566855934 industryCode "Marine Industry";
CM_ SG_ 2566855934 manufacturerCode "BEP Marine 2";
CM_ BO_ 2566856190 "Navico: Wireless Battery Status";
CM_ SG_ 2566856190 industryCode "Marine Industry";
CM_ SG_ 2566856190 manufacturerCode "Navico";
CM_ BO_ 2566856446 "BEP Marine: Proprietary PGN 65310";
CM_ SG_ 2566856446 industryCode "Marine Industry";
CM_ SG_ 2566856446 manufacturerCode "BEP Marine 2";
CM_ BO_ 2566856702 "BEP Marine: Proprietary PGN 65311";
CM_ SG_ 2566856702 industryCode "Marine Industry";
CM_ SG_ 2566856702 manufacturerCode "BEP Marine 2";
CM_ BO_ 2566856958 "Navico: Wireless Signal Status";
CM_ SG_ 2566856958 industryCode "Marine Industry";
CM_ SG_ 2566856958 manufacturerCode "Navico";
CM_ BO_ 2566857214 "Navico: Depth Quality";
CM_ SG_ 2566857214 depthQuality "Depth signal quality ratio (0 = no bottom lock .. ~1.0 = good)";
CM_ SG_ 2566857214 industryCode "Marine Industry";
CM_ SG_ 2566857214 manufacturerCode "Navico";
CM_ BO_ 2566857726 "Suzuki: Troll Mode Control";
CM_ SG_ 2566857726 industryCode "Marine Industry";
CM_ SG_ 2566857726 manufacturerCode "Suzuki Motor Corporation";
BA_DEF_ BO_  "SystemMessageLongSymbol" STRING ;
BA_DEF_ SG_  "SystemSignalLongSymbol" STRING ;
BA_DEF_DEF_  "SystemMessageLongSymbol" "";
BA_DEF_DEF_  "SystemSignalLongSymbol" "";
BA_ "SystemMessageLongSymbol" BO_ 2565538046 "PGN_60160_isoTransportProtocolDataTransfer";
BA_ "SystemMessageLongSymbol" BO_ 2566777342 "PGN_65001_bus1PhaseCBasicAcQuantities";
BA_ "SystemMessageLongSymbol" BO_ 2566777598 "PGN_65002_bus1PhaseBBasicAcQuantities";
BA_ "SystemMessageLongSymbol" BO_ 2566777854 "PGN_65003_bus1PhaseABasicAcQuantities";
BA_ "SystemMessageLongSymbol" BO_ 2566778110 "PGN_65004_bus1AverageBasicAcQuantities";
BA_ "SystemMessageLongSymbol" BO_ 2566778622 "PGN_65006_utilityPhaseCAcReactivePower";
BA_ "SystemMessageLongSymbol" BO_ 2566779134 "PGN_65008_utilityPhaseCBasicAcQuantities";
BA_ "SystemMessageLongSymbol" BO_ 2566779390 "PGN_65009_utilityPhaseBAcReactivePower";
BA_ "SystemMessageLongSymbol" BO_ 2566779902 "PGN_65011_utilityPhaseBBasicAcQuantities";
BA_ "SystemMessageLongSymbol" BO_ 2566780158 "PGN_65012_utilityPhaseAAcReactivePower";
BA_ "SystemMessageLongSymbol" BO_ 2566780670 "PGN_65014_utilityPhaseABasicAcQuantities";
BA_ "SystemMessageLongSymbol" BO_ 2566780926 "PGN_65015_utilityTotalAcReactivePower";
BA_ "SystemMessageLongSymbol" BO_ 2566781438 "PGN_65017_utilityAverageBasicAcQuantities";
BA_ "SystemMessageLongSymbol" BO_ 2566781950 "PGN_65019_generatorPhaseCAcReactivePower";
BA_ "SystemMessageLongSymbol" BO_ 2566782462 "PGN_65021_generatorPhaseCBasicAcQuantities";
BA_ "SystemMessageLongSymbol" BO_ 2566782718 "PGN_65022_generatorPhaseBAcReactivePower";
BA_ "SystemMessageLongSymbol" BO_ 2566783230 "PGN_65024_generatorPhaseBBasicAcQuantities";
BA_ "SystemMessageLongSymbol" BO_ 2566783486 "PGN_65025_generatorPhaseAAcReactivePower";
BA_ "SystemMessageLongSymbol" BO_ 2566783998 "PGN_65027_generatorPhaseABasicAcQuantities";
BA_ "SystemMessageLongSymbol" BO_ 2566784254 "PGN_65028_generatorTotalAcReactivePower";
BA_ "SystemMessageLongSymbol" BO_ 2566784766 "PGN_65030_generatorAverageBasicAcQuantities";
BA_ "SystemMessageLongSymbol" BO_ 2566849534 "PGN_65283_bepMarineCzoneChannelState";
BA_ "SystemMessageLongSymbol" BO_ 2566852350 "PGN_65294_bepMarineProprietaryPgn65294";
BA_ "SystemMessageLongSymbol" BO_ 2566852862 "PGN_65296_bepMarineProprietaryPgn65296";
BA_ "SystemMessageLongSymbol" BO_ 2566853118 "PGN_65297_bepMarineProprietaryPgn65297";
BA_ "SystemMessageLongSymbol" BO_ 2566855422 "PGN_65306_bepMarineProprietaryPgn65306";
BA_ "SystemMessageLongSymbol" BO_ 2566855934 "PGN_65308_bepMarineProprietaryPgn65308";
BA_ "SystemMessageLongSymbol" BO_ 2566856190 "PGN_65309_navicoWirelessBatteryStatus";
BA_ "SystemMessageLongSymbol" BO_ 2566856446 "PGN_65310_bepMarineProprietaryPgn65310";
BA_ "SystemMessageLongSymbol" BO_ 2566856702 "PGN_65311_bepMarineProprietaryPgn65311";
BA_ "SystemMessageLongSymbol" BO_ 2566856958 "PGN_65312_navicoWirelessSignalStatus";
VAL_ 2565341438 control 0 "ACK" 1 "NAK" 2 "Access Denied" 3 "Address Busy" ;
VAL_ 2565734654 arbitraryAddressCapable 0 "No" 1 "Yes" ;
VAL_ 2565734654 industryGroup 0 "Global" 1 "Highway" 2 "Agriculture" 3 "Construction" 4 "Marine Industry" 5 "Industrial" ;
VAL_ 2565734654 deviceClass 0 "Reserved for 2000 Use" 10 "System tools" 20 "Safety systems" 25 "Internetwork device" 30 "Electrical Distribution" 35 "Electrical Generation" 40 "Steering and Control surfaces" 50 "Propulsion" 60 "Navigation" 70 "Communication" 75 "Sensor Communication Interface" 80 "Instrumentation/general systems" 85 "External Environment" 90 "Internal Environment" 100 "Deck + cargo + fishing equipment systems" 110 "Human Interface" 120 "Display" 125 "Entertainment" ;
VAL_ 2565734654 manufacturerCode 69 "ARKS Enterprises, Inc." 78 "FW Murphy/Enovation Controls" 80 "Twin Disc" 85 "Kohler Power Systems" 88 "Hemisphere GPS Inc" 116 "BEP Marine" 135 "Airmar" 137 "Maretron" 140 "Lowrance" 144 "Mercury Marine" 147 "Nautibus Electronic GmbH" 148 "Blue Water Data" 154 "Westerbeke" 157 "ISSPRO Inc" 161 "Offshore Systems (UK) Ltd." 163 "Evinrude/BRP" 165 "CPAC Systems AB" 168 "Xantrex Technology Inc." 169 "Marlin Technologies, Inc." 172 "Yanmar Marine" 174 "Volvo Penta" 175 "Honda Marine" 176 "Carling Technologies Inc. (Moritz Aerospace)" 185 "Beede Instruments" 192 "Floscan Instrument Co. Inc." 193 "Nobletec" 198 "Mystic Valley Communications" 199 "Actia" 200 "Honda Marine 2" 201 "Disenos Y Technologia" 211 "Digital Switching Systems" 215 "Xintex/Atena" 224 "EMMI NETWORK S.L." 225 "Honda Marine 3" 228 "ZF" 229 "Garmin" 233 "Yacht Monitoring Solutions" 235 "Sailormade Marine Telemetry/Tetra Technology LTD" 243 "Eride" 250 "Honda Marine 4" 257 "Honda Motor Company LTD" 272 "Groco" 273 "Actisense" 274 "Amphenol LTW Technology" 275 "Navico" 283 "Hamilton Jet" 285 "Sea Recovery" 286 "Coelmo SRL Italy" 295 "BEP Marine 2" 304 "Empir Bus" 305 "NovAtel" 306 "Sleipner Motor AS" 307 "MBW Technologies" 311 "Fischer Panda" 315 "ICOM" 328 "Qwerty" 329 "Dief" 341 "Boening Automationstechnologie GmbH & Co. KG" 345 "Korean Maritime University" 351 "Thrane and Thrane" 355 "Mastervolt" 356 "Fischer Panda Generators" 358 "Victron Energy" 370 "Rolls Royce Marine" 373 "Electronic Design" 374 "Northern Lights" 378 "Glendinning" 381 "B & G" 384 "Rose Point Navigation Systems" 385 "Johnson Outdoors Marine Electronics Inc Geonav" 394 "Capi 2" 396 "Beyond Measure" 400 "Livorsi Marine" 404 "ComNav" 409 "Chetco" 419 "Fusion Electronics" 421 "Standard Horizon" 422 "True Heading AB" 426 "Egersund Marine Electronics AS" 427 "em-trak Marine Electronics" 431 "Tohatsu Co, JP" 437 "Digital Yacht" 438 "Comar Systems Limited" 440 "Cummins" 443 "VDO (aka Continental-Corporation)" 451 "Parker Hannifin aka Village Marine Tech" 459 "Alltek Marine Electronics Corp" 460 "SAN GIORGIO S.E.I.N" 466 "Veethree Electronics & Marine" 467 "Humminbird Marine Electronics" 470 "SI-TEX Marine Electronics" 471 "Sea Cross Marine AB" 475 "GME aka Standard Communications Pty LTD" 476 "Humminbird Marine Electronics 2" 478 "Ocean Sat BV" 481 "Chetco Digitial Instruments" 493 "Watcheye" 499 "Lcj Capteurs" 502 "Attwood Marine" 503 "Naviop S.R.L." 504 "Vesper Marine Ltd" 510 "Marinesoft Co. LTD" 513 "Simarine" 517 "NoLand Engineering" 518 "Transas USA" 529 "National Instruments Korea" 530 "National Marine Electronics Association" 532 "Onwa Marine" 540 "Webasto" 571 "Marinecraft (South Korea)" 573 "McMurdo Group aka Orolia LTD" 578 "Advansea" 579 "KVH" 580 "San Jose Technology" 583 "Yacht Control" 586 "Suzuki Motor Corporation" 591 "US Coast Guard" 595 "Ship Module aka Customware" 600 "Aquatic AV" 605 "Aventics GmbH" 606 "Intellian" 612 "SamwonIT" 614 "Arlt Tecnologies" 637 "Bavaria Yacts" 641 "Diverse Yacht Services" 644 "Wema U.S.A dba KUS" 645 "Garmin 2" 658 "Shenzhen Jiuzhou Himunication" 688 "Rockford Corp" 699 "Harman International" 704 "JL Audio" 708 "Lars Thrane" 715 "Autonnic" 717 "Yacht Devices" 734 "REAP Systems" 735 "Au Electronics Group" 739 "LxNav" 741 "Littelfuse, Inc (formerly Carling Technologies)" 743 "DaeMyung" 744 "Woosung" 748 "ISOTTA IFRA srl" 773 "Clarion US" 776 "HMI Systems" 777 "Ocean Signal" 778 "Seekeeper" 781 "Poly Planar" 785 "Fischer Panda DE" 795 "Broyda Industries" 796 "Canadian Automotive" 797 "Tides Marine" 798 "Lumishore" 799 "Still Water Designs and Audio" 802 "BJ Technologies (Beneteau)" 803 "Gill Sensors" 811 "Blue Water Desalination" 815 "FLIR" 824 "Undheim Systems" 826 "Lewmar Inc" 838 "TeamSurv" 844 "Fell Marine" 847 "Oceanvolt" 862 "Prospec" 868 "Data Panel Corp" 890 "L3 Technologies" 894 "Rhodan Marine Systems" 896 "Nexfour Solutions" 905 "ASA Electronics" 909 "Marines Co (South Korea)" 911 "Nautic-on" 917 "Sentinel" 929 "JL Marine ystems" 930 "Ecotronix" 944 "Zontisa Marine" 951 "EXOR International" 962 "Timbolier Industries" 963 "TJC Micro" 968 "Cox Powertrain" 969 "Blue Seas" 981 "Kobelt Manufacturing Co. Ltd" 992 "Blue Ocean IOT" 997 "Xenta Systems" 999 "Signal K" 1004 "Ultraflex SpA" 1008 "Lintest SmartBoat" 1011 "Soundmax" 1020 "Team Italia Marine (Onyx Marine Automation s.r.l)" 1021 "Entratech" 1022 "ITC Inc." 1029 "The Marine Guardian LLC" 1047 "Sonic Corporation" 1051 "ProNav" 1053 "Vetus Maxwell INC." 1056 "Lithium Pros" 1059 "Boatrax" 1062 "Marol Co ltd" 1065 "CALYPSO Instruments" 1066 "Spot Zero Water" 1069 "Lithionics Battery LLC" 1070 "Quick-teck Electronics Ltd" 1075 "Uniden America" 1083 "Nauticoncept" 1084 "Shadow-Caster LED lighting LLC" 1085 "Wet Sounds, LLC" 1088 "E-T-A Circuit Breakers" 1092 "Scheiber" 1100 "Smart Yachts International Limited" 1109 "Dockmate" 1114 "Bobs Machine" 1118 "L3Harris ASV" 1119 "Balmar LLC" 1120 "Elettromedia spa" 1127 "Electromaax" 1140 "Across Oceans Systems Ltd." 1145 "Kiwi Yachting" 1150 "BSB Artificial Intelligence GmbH" 1151 "Orca Technologoes AS" 1154 "TBS Electronics BV" 1158 "Technoton Electroics" 1160 "MG Energy Systems B.V." 1169 "Sea Macine Robotics Inc." 1171 "Vista Manufacturing" 1183 "Zipwake" 1186 "Sailmon BV" 1192 "Airmoniq Pro Kft" 1194 "Sierra Marine" 1200 "Xinuo Information Technology (Xiamen)" 1218 "Septentrio" 1233 "NKE Marine Elecronics" 1238 "SuperTrack Aps" 1239 "Honda Electronics Co., LTD" 1245 "Raritan Engineering Company, Inc" 1249 "Integrated Power Solutions AG" 1260 "Interactive Technologies, Inc." 1283 "LTG-Tech" 1299 "Energy Solutions (UK) LTD." 1300 "WATT Fuel Cell Corp" 1302 "Pro Mainer" 1305 "Dragonfly Energy" 1306 "Koden Electronics Co., Ltd" 1311 "Humphree AB" 1316 "Hinkley Yachts" 1317 "Global Marine Management GmbH (GMM)" 1320 "Triskel Marine Ltd" 1330 "Warwick Control Technologies" 1331 "Dolphin Charger" 1337 "Barnacle Systems Inc" 1348 "Radian IoT, Inc." 1353 "Ocean LED Marine Ltd" 1359 "BluNav" 1361 "OVA (Nantong Saiyang Electronics Co., Ltd)" 1368 "RAD Propulsion" 1369 "Electric Yacht" 1372 "Elco Motor Yachts" 1384 "Tecnoseal Foundry S.r.l" 1385 "Pro Charging Systems, LLC" 1389 "EVEX Co., LTD" 1398 "Gobius Sensor Technology AB" 1403 "Arco Marine" 1408 "Lenco Marine Inc." 1413 "Naocontrol S.L." 1417 "Revatek" 1438 "Aeolionics" 1439 "PredictWind Ltd" 1440 "Egis Mobile Electric" 1445 "Starboard Yacht Group" 1446 "Roswell Marine" 1451 "ePropulsion (Guangdong ePropulsion Technology Ltd.)" 1452 "Micro-Air LLC" 1453 "Vital Battery" 1458 "Ride Controller LLC" 1460 "Tocaro Blue" 1461 "Vanquish Yachts" 1471 "FT Technologies" 1478 "Alps Alpine Co., Ltd." 1481 "E-Force Marine" 1482 "CMC Marine" 1483 "Nanjing Sandemarine Information Technology Co., Ltd." 1850 "Teleflex Marine (SeaStar Solutions)" 1851 "Raymarine" 1852 "Navionics" 1853 "Japan Radio Co" 1854 "Northstar Technologies" 1855 "Furuno" 1856 "Trimble" 1857 "Simrad" 1858 "Litton" 1859 "Kvasar AB" 1860 "MMP" 1861 "Vector Cantech" 1862 "Yamaha Marine" 1863 "Faria Instruments" ;
VAL_ 2566778622 powerFactorLagging 0 "Leading" 1 "Lagging" 2 "Error" ;
VAL_ 2566779390 powerFactorLagging 0 "Leading" 1 "Lagging" 2 "Error" ;
VAL_ 2566780158 powerFactorLagging 0 "Leading" 1 "Lagging" 2 "Error" ;
VAL_ 2566780926 powerFactorLagging 0 "Leading" 1 "Lagging" 2 "Error" ;
VAL_ 2566781950 powerFactorLagging 0 "Leading" 1 "Lagging" 2 "Error" ;
VAL_ 2566782718 powerFactorLagging 0 "Leading" 1 "Lagging" 2 "Error" ;
VAL_ 2566783486 powerFactorLagging 0 "Leading" 1 "Lagging" 2 "Error" ;
VAL_ 2566784254 powerFactorLagging 0 "Leading" 1 "Lagging" 2 "Error" ;
VAL_ 2566849534 industryCode 0 "Global" 1 "Highway" 2 "Agriculture" 3 "Construction" 4 "Marine Industry" 5 "Industrial" ;
VAL_ 2566849534 manufacturerCode 69 "ARKS Enterprises, Inc." 78 "FW Murphy/Enovation Controls" 80 "Twin Disc" 85 "Kohler Power Systems" 88 "Hemisphere GPS Inc" 116 "BEP Marine" 135 "Airmar" 137 "Maretron" 140 "Lowrance" 144 "Mercury Marine" 147 "Nautibus Electronic GmbH" 148 "Blue Water Data" 154 "Westerbeke" 157 "ISSPRO Inc" 161 "Offshore Systems (UK) Ltd." 163 "Evinrude/BRP" 165 "CPAC Systems AB" 168 "Xantrex Technology Inc." 169 "Marlin Technologies, Inc." 172 "Yanmar Marine" 174 "Volvo Penta" 175 "Honda Marine" 176 "Carling Technologies Inc. (Moritz Aerospace)" 185 "Beede Instruments" 192 "Floscan Instrument Co. Inc." 193 "Nobletec" 198 "Mystic Valley Communications" 199 "Actia" 200 "Honda Marine 2" 201 "Disenos Y Technologia" 211 "Digital Switching Systems" 215 "Xintex/Atena" 224 "EMMI NETWORK S.L." 225 "Honda Marine 3" 228 "ZF" 229 "Garmin" 233 "Yacht Monitoring Solutions" 235 "Sailormade Marine Telemetry/Tetra Technology LTD" 243 "Eride" 250 "Honda Marine 4" 257 "Honda Motor Company LTD" 272 "Groco" 273 "Actisense" 274 "Amphenol LTW Technology" 275 "Navico" 283 "Hamilton Jet" 285 "Sea Recovery" 286 "Coelmo SRL Italy" 295 "BEP Marine 2" 304 "Empir Bus" 305 "NovAtel" 306 "Sleipner Motor AS" 307 "MBW Technologies" 311 "Fischer Panda" 315 "ICOM" 328 "Qwerty" 329 "Dief" 341 "Boening Automationstechnologie GmbH & Co. KG" 345 "Korean Maritime University" 351 "Thrane and Thrane" 355 "Mastervolt" 356 "Fischer Panda Generators" 358 "Victron Energy" 370 "Rolls Royce Marine" 373 "Electronic Design" 374 "Northern Lights" 378 "Glendinning" 381 "B & G" 384 "Rose Point Navigation Systems" 385 "Johnson Outdoors Marine Electronics Inc Geonav" 394 "Capi 2" 396 "Beyond Measure" 400 "Livorsi Marine" 404 "ComNav" 409 "Chetco" 419 "Fusion Electronics" 421 "Standard Horizon" 422 "True Heading AB" 426 "Egersund Marine Electronics AS" 427 "em-trak Marine Electronics" 431 "Tohatsu Co, JP" 437 "Digital Yacht" 438 "Comar Systems Limited" 440 "Cummins" 443 "VDO (aka Continental-Corporation)" 451 "Parker Hannifin aka Village Marine Tech" 459 "Alltek Marine Electronics Corp" 460 "SAN GIORGIO S.E.I.N" 466 "Veethree Electronics & Marine" 467 "Humminbird Marine Electronics" 470 "SI-TEX Marine Electronics" 471 "Sea Cross Marine AB" 475 "GME aka Standard Communications Pty LTD" 476 "Humminbird Marine Electronics 2" 478 "Ocean Sat BV" 481 "Chetco Digitial Instruments" 493 "Watcheye" 499 "Lcj Capteurs" 502 "Attwood Marine" 503 "Naviop S.R.L." 504 "Vesper Marine Ltd" 510 "Marinesoft Co. LTD" 513 "Simarine" 517 "NoLand Engineering" 518 "Transas USA" 529 "National Instruments Korea" 530 "National Marine Electronics Association" 532 "Onwa Marine" 540 "Webasto" 571 "Marinecraft (South Korea)" 573 "McMurdo Group aka Orolia LTD" 578 "Advansea" 579 "KVH" 580 "San Jose Technology" 583 "Yacht Control" 586 "Suzuki Motor Corporation" 591 "US Coast Guard" 595 "Ship Module aka Customware" 600 "Aquatic AV" 605 "Aventics GmbH" 606 "Intellian" 612 "SamwonIT" 614 "Arlt Tecnologies" 637 "Bavaria Yacts" 641 "Diverse Yacht Services" 644 "Wema U.S.A dba KUS" 645 "Garmin 2" 658 "Shenzhen Jiuzhou Himunication" 688 "Rockford Corp" 699 "Harman International" 704 "JL Audio" 708 "Lars Thrane" 715 "Autonnic" 717 "Yacht Devices" 734 "REAP Systems" 735 "Au Electronics Group" 739 "LxNav" 741 "Littelfuse, Inc (formerly Carling Technologies)" 743 "DaeMyung" 744 "Woosung" 748 "ISOTTA IFRA srl" 773 "Clarion US" 776 "HMI Systems" 777 "Ocean Signal" 778 "Seekeeper" 781 "Poly Planar" 785 "Fischer Panda DE" 795 "Broyda Industries" 796 "Canadian Automotive" 797 "Tides Marine" 798 "Lumishore" 799 "Still Water Designs and Audio" 802 "BJ Technologies (Beneteau)" 803 "Gill Sensors" 811 "Blue Water Desalination" 815 "FLIR" 824 "Undheim Systems" 826 "Lewmar Inc" 838 "TeamSurv" 844 "Fell Marine" 847 "Oceanvolt" 862 "Prospec" 868 "Data Panel Corp" 890 "L3 Technologies" 894 "Rhodan Marine Systems" 896 "Nexfour Solutions" 905 "ASA Electronics" 909 "Marines Co (South Korea)" 911 "Nautic-on" 917 "Sentinel" 929 "JL Marine ystems" 930 "Ecotronix" 944 "Zontisa Marine" 951 "EXOR International" 962 "Timbolier Industries" 963 "TJC Micro" 968 "Cox Powertrain" 969 "Blue Seas" 981 "Kobelt Manufacturing Co. Ltd" 992 "Blue Ocean IOT" 997 "Xenta Systems" 999 "Signal K" 1004 "Ultraflex SpA" 1008 "Lintest SmartBoat" 1011 "Soundmax" 1020 "Team Italia Marine (Onyx Marine Automation s.r.l)" 1021 "Entratech" 1022 "ITC Inc." 1029 "The Marine Guardian LLC" 1047 "Sonic Corporation" 1051 "ProNav" 1053 "Vetus Maxwell INC." 1056 "Lithium Pros" 1059 "Boatrax" 1062 "Marol Co ltd" 1065 "CALYPSO Instruments" 1066 "Spot Zero Water" 1069 "Lithionics Battery LLC" 1070 "Quick-teck Electronics Ltd" 1075 "Uniden America" 1083 "Nauticoncept" 1084 "Shadow-Caster LED lighting LLC" 1085 "Wet Sounds, LLC" 1088 "E-T-A Circuit Breakers" 1092 "Scheiber" 1100 "Smart Yachts International Limited" 1109 "Dockmate" 1114 "Bobs Machine" 1118 "L3Harris ASV" 1119 "Balmar LLC" 1120 "Elettromedia spa" 1127 "Electromaax" 1140 "Across Oceans Systems Ltd." 1145 "Kiwi Yachting" 1150 "BSB Artificial Intelligence GmbH" 1151 "Orca Technologoes AS" 1154 "TBS Electronics BV" 1158 "Technoton Electroics" 1160 "MG Energy Systems B.V." 1169 "Sea Macine Robotics Inc." 1171 "Vista Manufacturing" 1183 "Zipwake" 1186 "Sailmon BV" 1192 "Airmoniq Pro Kft" 1194 "Sierra Marine" 1200 "Xinuo Information Technology (Xiamen)" 1218 "Septentrio" 1233 "NKE Marine Elecronics" 1238 "SuperTrack Aps" 1239 "Honda Electronics Co., LTD" 1245 "Raritan Engineering Company, Inc" 1249 "Integrated Power Solutions AG" 1260 "Interactive Technologies, Inc." 1283 "LTG-Tech" 1299 "Energy Solutions (UK) LTD." 1300 "WATT Fuel Cell Corp" 1302 "Pro Mainer" 1305 "Dragonfly Energy" 1306 "Koden Electronics Co., Ltd" 1311 "Humphree AB" 1316 "Hinkley Yachts" 1317 "Global Marine Management GmbH (GMM)" 1320 "Triskel Marine Ltd" 1330 "Warwick Control Technologies" 1331 "Dolphin Charger" 1337 "Barnacle Systems Inc" 1348 "Radian IoT, Inc." 1353 "Ocean LED Marine Ltd" 1359 "BluNav" 1361 "OVA (Nantong Saiyang Electronics Co., Ltd)" 1368 "RAD Propulsion" 1369 "Electric Yacht" 1372 "Elco Motor Yachts" 1384 "Tecnoseal Foundry S.r.l" 1385 "Pro Charging Systems, LLC" 1389 "EVEX Co., LTD" 1398 "Gobius Sensor Technology AB" 1403 "Arco Marine" 1408 "Lenco Marine Inc." 1413 "Naocontrol S.L." 1417 "Revatek" 1438 "Aeolionics" 1439 "PredictWind Ltd" 1440 "Egis Mobile Electric" 1445 "Starboard Yacht Group" 1446 "Roswell Marine" 1451 "ePropulsion (Guangdong ePropulsion Technology Ltd.)" 1452 "Micro-Air LLC" 1453 "Vital Battery" 1458 "Ride Controller LLC" 1460 "Tocaro Blue" 1461 "Vanquish Yachts" 1471 "FT Technologies" 1478 "Alps Alpine Co., Ltd." 1481 "E-Force Marine" 1482 "CMC Marine" 1483 "Nanjing Sandemarine Information Technology Co., Ltd." 1850 "Teleflex Marine (SeaStar Solutions)" 1851 "Raymarine" 1852 "Navionics" 1853 "Japan Radio Co" 1854 "Northstar Technologies" 1855 "Furuno" 1856 "Trimble" 1857 "Simrad" 1858 "Litton" 1859 "Kvasar AB" 1860 "MMP" 1861 "Vector Cantech" 1862 "Yamaha Marine" 1863 "Faria Instruments" ;
VAL_ 2566851582 industryCode 0 "Global" 1 "Highway" 2 "Agriculture" 3 "Construction" 4 "Marine Industry" 5 "Industrial" ;
VAL_ 2566851582 manufacturerCode 69 "ARKS Enterprises, Inc." 78 "FW Murphy/Enovation Controls" 80 "Twin Disc" 85 "Kohler Power Systems" 88 "Hemisphere GPS Inc" 116 "BEP Marine" 135 "Airmar" 137 "Maretron" 140 "Lowrance" 144 "Mercury Marine" 147 "Nautibus Electronic GmbH" 148 "Blue Water Data" 154 "Westerbeke" 157 "ISSPRO Inc" 161 "Offshore Systems (UK) Ltd." 163 "Evinrude/BRP" 165 "CPAC Systems AB" 168 "Xantrex Technology Inc." 169 "Marlin Technologies, Inc." 172 "Yanmar Marine" 174 "Volvo Penta" 175 "Honda Marine" 176 "Carling Technologies Inc. (Moritz Aerospace)" 185 "Beede Instruments" 192 "Floscan Instrument Co. Inc." 193 "Nobletec" 198 "Mystic Valley Communications" 199 "Actia" 200 "Honda Marine 2" 201 "Disenos Y Technologia" 211 "Digital Switching Systems" 215 "Xintex/Atena" 224 "EMMI NETWORK S.L." 225 "Honda Marine 3" 228 "ZF" 229 "Garmin" 233 "Yacht Monitoring Solutions" 235 "Sailormade Marine Telemetry/Tetra Technology LTD" 243 "Eride" 250 "Honda Marine 4" 257 "Honda Motor Company LTD" 272 "Groco" 273 "Actisense" 274 "Amphenol LTW Technology" 275 "Navico" 283 "Hamilton Jet" 285 "Sea Recovery" 286 "Coelmo SRL Italy" 295 "BEP Marine 2" 304 "Empir Bus" 305 "NovAtel" 306 "Sleipner Motor AS" 307 "MBW Technologies" 311 "Fischer Panda" 315 "ICOM" 328 "Qwerty" 329 "Dief" 341 "Boening Automationstechnologie GmbH & Co. KG" 345 "Korean Maritime University" 351 "Thrane and Thrane" 355 "Mastervolt" 356 "Fischer Panda Generators" 358 "Victron Energy" 370 "Rolls Royce Marine" 373 "Electronic Design" 374 "Northern Lights" 378 "Glendinning" 381 "B & G" 384 "Rose Point Navigation Systems" 385 "Johnson Outdoors Marine Electronics Inc Geonav" 394 "Capi 2" 396 "Beyond Measure" 400 "Livorsi Marine" 404 "ComNav" 409 "Chetco" 419 "Fusion Electronics" 421 "Standard Horizon" 422 "True Heading AB" 426 "Egersund Marine Electronics AS" 427 "em-trak Marine Electronics" 431 "Tohatsu Co, JP" 437 "Digital Yacht" 438 "Comar Systems Limited" 440 "Cummins" 443 "VDO (aka Continental-Corporation)" 451 "Parker Hannifin aka Village Marine Tech" 459 "Alltek Marine Electronics Corp" 460 "SAN GIORGIO S.E.I.N" 466 "Veethree Electronics & Marine" 467 "Humminbird Marine Electronics" 470 "SI-TEX Marine Electronics" 471 "Sea Cross Marine AB" 475 "GME aka Standard Communications Pty LTD" 476 "Humminbird Marine Electronics 2" 478 "Ocean Sat BV" 481 "Chetco Digitial Instruments" 493 "Watcheye" 499 "Lcj Capteurs" 502 "Attwood Marine" 503 "Naviop S.R.L." 504 "Vesper Marine Ltd" 510 "Marinesoft Co. LTD" 513 "Simarine" 517 "NoLand Engineering" 518 "Transas USA" 529 "National Instruments Korea" 530 "National Marine Electronics Association" 532 "Onwa Marine" 540 "Webasto" 571 "Marinecraft (South Korea)" 573 "McMurdo Group aka Orolia LTD" 578 "Advansea" 579 "KVH" 580 "San Jose Technology" 583 "Yacht Control" 586 "Suzuki Motor Corporation" 591 "US Coast Guard" 595 "Ship Module aka Customware" 600 "Aquatic AV" 605 "Aventics GmbH" 606 "Intellian" 612 "SamwonIT" 614 "Arlt Tecnologies" 637 "Bavaria Yacts" 641 "Diverse Yacht Services" 644 "Wema U.S.A dba KUS" 645 "Garmin 2" 658 "Shenzhen Jiuzhou Himunication" 688 "Rockford Corp" 699 "Harman International" 704 "JL Audio" 708 "Lars Thrane" 715 "Autonnic" 717 "Yacht Devices" 734 "REAP Systems" 735 "Au Electronics Group" 739 "LxNav" 741 "Littelfuse, Inc (formerly Carling Technologies)" 743 "DaeMyung" 744 "Woosung" 748 "ISOTTA IFRA srl" 773 "Clarion US" 776 "HMI Systems" 777 "Ocean Signal" 778 "Seekeeper" 781 "Poly Planar" 785 "Fischer Panda DE" 795 "Broyda Industries" 796 "Canadian Automotive" 797 "Tides Marine" 798 "Lumishore" 799 "Still Water Designs and Audio" 802 "BJ Technologies (Beneteau)" 803 "Gill Sensors" 811 "Blue Water Desalination" 815 "FLIR" 824 "Undheim Systems" 826 "Lewmar Inc" 838 "TeamSurv" 844 "Fell Marine" 847 "Oceanvolt" 862 "Prospec" 868 "Data Panel Corp" 890 "L3 Technologies" 894 "Rhodan Marine Systems" 896 "Nexfour Solutions" 905 "ASA Electronics" 909 "Marines Co (South Korea)" 911 "Nautic-on" 917 "Sentinel" 929 "JL Marine ystems" 930 "Ecotronix" 944 "Zontisa Marine" 951 "EXOR International" 962 "Timbolier Industries" 963 "TJC Micro" 968 "Cox Powertrain" 969 "Blue Seas" 981 "Kobelt Manufacturing Co. Ltd" 992 "Blue Ocean IOT" 997 "Xenta Systems" 999 "Signal K" 1004 "Ultraflex SpA" 1008 "Lintest SmartBoat" 1011 "Soundmax" 1020 "Team Italia Marine (Onyx Marine Automation s.r.l)" 1021 "Entratech" 1022 "ITC Inc." 1029 "The Marine Guardian LLC" 1047 "Sonic Corporation" 1051 "ProNav" 1053 "Vetus Maxwell INC." 1056 "Lithium Pros" 1059 "Boatrax" 1062 "Marol Co ltd" 1065 "CALYPSO Instruments" 1066 "Spot Zero Water" 1069 "Lithionics Battery LLC" 1070 "Quick-teck Electronics Ltd" 1075 "Uniden America" 1083 "Nauticoncept" 1084 "Shadow-Caster LED lighting LLC" 1085 "Wet Sounds, LLC" 1088 "E-T-A Circuit Breakers" 1092 "Scheiber" 1100 "Smart Yachts International Limited" 1109 "Dockmate" 1114 "Bobs Machine" 1118 "L3Harris ASV" 1119 "Balmar LLC" 1120 "Elettromedia spa" 1127 "Electromaax" 1140 "Across Oceans Systems Ltd." 1145 "Kiwi Yachting" 1150 "BSB Artificial Intelligence GmbH" 1151 "Orca Technologoes AS" 1154 "TBS Electronics BV" 1158 "Technoton Electroics" 1160 "MG Energy Systems B.V." 1169 "Sea Macine Robotics Inc." 1171 "Vista Manufacturing" 1183 "Zipwake" 1186 "Sailmon BV" 1192 "Airmoniq Pro Kft" 1194 "Sierra Marine" 1200 "Xinuo Information Technology (Xiamen)" 1218 "Septentrio" 1233 "NKE Marine Elecronics" 1238 "SuperTrack Aps" 1239 "Honda Electronics Co., LTD" 1245 "Raritan Engineering Company, Inc" 1249 "Integrated Power Solutions AG" 1260 "Interactive Technologies, Inc." 1283 "LTG-Tech" 1299 "Energy Solutions (UK) LTD." 1300 "WATT Fuel Cell Corp" 1302 "Pro Mainer" 1305 "Dragonfly Energy" 1306 "Koden Electronics Co., Ltd" 1311 "Humphree AB" 1316 "Hinkley Yachts" 1317 "Global Marine Management GmbH (GMM)" 1320 "Triskel Marine Ltd" 1330 "Warwick Control Technologies" 1331 "Dolphin Charger" 1337 "Barnacle Systems Inc" 1348 "Radian IoT, Inc." 1353 "Ocean LED Marine Ltd" 1359 "BluNav" 1361 "OVA (Nantong Saiyang Electronics Co., Ltd)" 1368 "RAD Propulsion" 1369 "Electric Yacht" 1372 "Elco Motor Yachts" 1384 "Tecnoseal Foundry S.r.l" 1385 "Pro Charging Systems, LLC" 1389 "EVEX Co., LTD" 1398 "Gobius Sensor Technology AB" 1403 "Arco Marine" 1408 "Lenco Marine Inc." 1413 "Naocontrol S.L." 1417 "Revatek" 1438 "Aeolionics" 1439 "PredictWind Ltd" 1440 "Egis Mobile Electric" 1445 "Starboard Yacht Group" 1446 "Roswell Marine" 1451 "ePropulsion (Guangdong ePropulsion Technology Ltd.)" 1452 "Micro-Air LLC" 1453 "Vital Battery" 1458 "Ride Controller LLC" 1460 "Tocaro Blue" 1461 "Vanquish Yachts" 1471 "FT Technologies" 1478 "Alps Alpine Co., Ltd." 1481 "E-Force Marine" 1482 "CMC Marine" 1483 "Nanjing Sandemarine Information Technology Co., Ltd." 1850 "Teleflex Marine (SeaStar Solutions)" 1851 "Raymarine" 1852 "Navionics" 1853 "Japan Radio Co" 1854 "Northstar Technologies" 1855 "Furuno" 1856 "Trimble" 1857 "Simrad" 1858 "Litton" 1859 "Kvasar AB" 1860 "MMP" 1861 "Vector Cantech" 1862 "Yamaha Marine" 1863 "Faria Instruments" ;
VAL_ 2566852350 industryCode 0 "Global" 1 "Highway" 2 "Agriculture" 3 "Construction" 4 "Marine Industry" 5 "Industrial" ;
VAL_ 2566852350 manufacturerCode 69 "ARKS Enterprises, Inc." 78 "FW Murphy/Enovation Controls" 80 "Twin Disc" 85 "Kohler Power Systems" 88 "Hemisphere GPS Inc" 116 "BEP Marine" 135 "Airmar" 137 "Maretron" 140 "Lowrance" 144 "Mercury Marine" 147 "Nautibus Electronic GmbH" 148 "Blue Water Data" 154 "Westerbeke" 157 "ISSPRO Inc" 161 "Offshore Systems (UK) Ltd." 163 "Evinrude/BRP" 165 "CPAC Systems AB" 168 "Xantrex Technology Inc." 169 "Marlin Technologies, Inc." 172 "Yanmar Marine" 174 "Volvo Penta" 175 "Honda Marine" 176 "Carling Technologies Inc. (Moritz Aerospace)" 185 "Beede Instruments" 192 "Floscan Instrument Co. Inc." 193 "Nobletec" 198 "Mystic Valley Communications" 199 "Actia" 200 "Honda Marine 2" 201 "Disenos Y Technologia" 211 "Digital Switching Systems" 215 "Xintex/Atena" 224 "EMMI NETWORK S.L." 225 "Honda Marine 3" 228 "ZF" 229 "Garmin" 233 "Yacht Monitoring Solutions" 235 "Sailormade Marine Telemetry/Tetra Technology LTD" 243 "Eride" 250 "Honda Marine 4" 257 "Honda Motor Company LTD" 272 "Groco" 273 "Actisense" 274 "Amphenol LTW Technology" 275 "Navico" 283 "Hamilton Jet" 285 "Sea Recovery" 286 "Coelmo SRL Italy" 295 "BEP Marine 2" 304 "Empir Bus" 305 "NovAtel" 306 "Sleipner Motor AS" 307 "MBW Technologies" 311 "Fischer Panda" 315 "ICOM" 328 "Qwerty" 329 "Dief" 341 "Boening Automationstechnologie GmbH & Co. KG" 345 "Korean Maritime University" 351 "Thrane and Thrane" 355 "Mastervolt" 356 "Fischer Panda Generators" 358 "Victron Energy" 370 "Rolls Royce Marine" 373 "Electronic Design" 374 "Northern Lights" 378 "Glendinning" 381 "B & G" 384 "Rose Point Navigation Systems" 385 "Johnson Outdoors Marine Electronics Inc Geonav" 394 "Capi 2" 396 "Beyond Measure" 400 "Livorsi Marine" 404 "ComNav" 409 "Chetco" 419 "Fusion Electronics" 421 "Standard Horizon" 422 "True Heading AB" 426 "Egersund Marine Electronics AS" 427 "em-trak Marine Electronics" 431 "Tohatsu Co, JP" 437 "Digital Yacht" 438 "Comar Systems Limited" 440 "Cummins" 443 "VDO (aka Continental-Corporation)" 451 "Parker Hannifin aka Village Marine Tech" 459 "Alltek Marine Electronics Corp" 460 "SAN GIORGIO S.E.I.N" 466 "Veethree Electronics & Marine" 467 "Humminbird Marine Electronics" 470 "SI-TEX Marine Electronics" 471 "Sea Cross Marine AB" 475 "GME aka Standard Communications Pty LTD" 476 "Humminbird Marine Electronics 2" 478 "Ocean Sat BV" 481 "Chetco Digitial Instruments" 493 "Watcheye" 499 "Lcj Capteurs" 502 "Attwood Marine" 503 "Naviop S.R.L." 504 "Vesper Marine Ltd" 510 "Marinesoft Co. LTD" 513 "Simarine" 517 "NoLand Engineering" 518 "Transas USA" 529 "National Instruments Korea" 530 "National Marine Electronics Association" 532 "Onwa Marine" 540 "Webasto" 571 "Marinecraft (South Korea)" 573 "McMurdo Group aka Orolia LTD" 578 "Advansea" 579 "KVH" 580 "San Jose Technology" 583 "Yacht Control" 586 "Suzuki Motor Corporation" 591 "US Coast Guard" 595 "Ship Module aka Customware" 600 "Aquatic AV" 605 "Aventics GmbH" 606 "Intellian" 612 "SamwonIT" 614 "Arlt Tecnologies" 637 "Bavaria Yacts" 641 "Diverse Yacht Services" 644 "Wema U.S.A dba KUS" 645 "Garmin 2" 658 "Shenzhen Jiuzhou Himunication" 688 "Rockford Corp" 699 "Harman International" 704 "JL Audio" 708 "Lars Thrane" 715 "Autonnic" 717 "Yacht Devices" 734 "REAP Systems" 735 "Au Electronics Group" 739 "LxNav" 741 "Littelfuse, Inc (formerly Carling Technologies)" 743 "DaeMyung" 744 "Woosung" 748 "ISOTTA IFRA srl" 773 "Clarion US" 776 "HMI Systems" 777 "Ocean Signal" 778 "Seekeeper" 781 "Poly Planar" 785 "Fischer Panda DE" 795 "Broyda Industries" 796 "Canadian Automotive" 797 "Tides Marine" 798 "Lumishore" 799 "Still Water Designs and Audio" 802 "BJ Technologies (Beneteau)" 803 "Gill Sensors" 811 "Blue Water Desalination" 815 "FLIR" 824 "Undheim Systems" 826 "Lewmar Inc" 838 "TeamSurv" 844 "Fell Marine" 847 "Oceanvolt" 862 "Prospec" 868 "Data Panel Corp" 890 "L3 Technologies" 894 "Rhodan Marine Systems" 896 "Nexfour Solutions" 905 "ASA Electronics" 909 "Marines Co (South Korea)" 911 "Nautic-on" 917 "Sentinel" 929 "JL Marine ystems" 930 "Ecotronix" 944 "Zontisa Marine" 951 "EXOR International" 962 "Timbolier Industries" 963 "TJC Micro" 968 "Cox Powertrain" 969 "Blue Seas" 981 "Kobelt Manufacturing Co. Ltd" 992 "Blue Ocean IOT" 997 "Xenta Systems" 999 "Signal K" 1004 "Ultraflex SpA" 1008 "Lintest SmartBoat" 1011 "Soundmax" 1020 "Team Italia Marine (Onyx Marine Automation s.r.l)" 1021 "Entratech" 1022 "ITC Inc." 1029 "The Marine Guardian LLC" 1047 "Sonic Corporation" 1051 "ProNav" 1053 "Vetus Maxwell INC." 1056 "Lithium Pros" 1059 "Boatrax" 1062 "Marol Co ltd" 1065 "CALYPSO Instruments" 1066 "Spot Zero Water" 1069 "Lithionics Battery LLC" 1070 "Quick-teck Electronics Ltd" 1075 "Uniden America" 1083 "Nauticoncept" 1084 "Shadow-Caster LED lighting LLC" 1085 "Wet Sounds, LLC" 1088 "E-T-A Circuit Breakers" 1092 "Scheiber" 1100 "Smart Yachts International Limited" 1109 "Dockmate" 1114 "Bobs Machine" 1118 "L3Harris ASV" 1119 "Balmar LLC" 1120 "Elettromedia spa" 1127 "Electromaax" 1140 "Across Oceans Systems Ltd." 1145 "Kiwi Yachting" 1150 "BSB Artificial Intelligence GmbH" 1151 "Orca Technologoes AS" 1154 "TBS Electronics BV" 1158 "Technoton Electroics" 1160 "MG Energy Systems B.V." 1169 "Sea Macine Robotics Inc." 1171 "Vista Manufacturing" 1183 "Zipwake" 1186 "Sailmon BV" 1192 "Airmoniq Pro Kft" 1194 "Sierra Marine" 1200 "Xinuo Information Technology (Xiamen)" 1218 "Septentrio" 1233 "NKE Marine Elecronics" 1238 "SuperTrack Aps" 1239 "Honda Electronics Co., LTD" 1245 "Raritan Engineering Company, Inc" 1249 "Integrated Power Solutions AG" 1260 "Interactive Technologies, Inc." 1283 "LTG-Tech" 1299 "Energy Solutions (UK) LTD." 1300 "WATT Fuel Cell Corp" 1302 "Pro Mainer" 1305 "Dragonfly Energy" 1306 "Koden Electronics Co., Ltd" 1311 "Humphree AB" 1316 "Hinkley Yachts" 1317 "Global Marine Management GmbH (GMM)" 1320 "Triskel Marine Ltd" 1330 "Warwick Control Technologies" 1331 "Dolphin Charger" 1337 "Barnacle Systems Inc" 1348 "Radian IoT, Inc." 1353 "Ocean LED Marine Ltd" 1359 "BluNav" 1361 "OVA (Nantong Saiyang Electronics Co., Ltd)" 1368 "RAD Propulsion" 1369 "Electric Yacht" 1372 "Elco Motor Yachts" 1384 "Tecnoseal Foundry S.r.l" 1385 "Pro Charging Systems, LLC" 1389 "EVEX Co., LTD" 1398 "Gobius Sensor Technology AB" 1403 "Arco Marine" 1408 "Lenco Marine Inc." 1413 "Naocontrol S.L." 1417 "Revatek" 1438 "Aeolionics" 1439 "PredictWind Ltd" 1440 "Egis Mobile Electric" 1445 "Starboard Yacht Group" 1446 "Roswell Marine" 1451 "ePropulsion (Guangdong ePropulsion Technology Ltd.)" 1452 "Micro-Air LLC" 1453 "Vital Battery" 1458 "Ride Controller LLC" 1460 "Tocaro Blue" 1461 "Vanquish Yachts" 1471 "FT Technologies" 1478 "Alps Alpine Co., Ltd." 1481 "E-Force Marine" 1482 "CMC Marine" 1483 "Nanjing Sandemarine Information Technology Co., Ltd." 1850 "Teleflex Marine (SeaStar Solutions)" 1851 "Raymarine" 1852 "Navionics" 1853 "Japan Radio Co" 1854 "Northstar Technologies" 1855 "Furuno" 1856 "Trimble" 1857 "Simrad" 1858 "Litton" 1859 "Kvasar AB" 1860 "MMP" 1861 "Vector Cantech" 1862 "Yamaha Marine" 1863 "Faria Instruments" ;
VAL_ 2566852606 alarmType 1 "AC Voltage Error" 2 "AC Frequency Error" 3 "AC High Power" 4 "DC Low Voltage" 5 "DC Very Low Voltage" 6 "DC High Voltage" 7 "DC Low Battery Capacity" 10 "Out of Range" 11 "Low Run Current" 12 "Over Current" 13 "Short Circuit" 14 "Missing Commander" 15 "Reverse Current" 16 "Calibration Error" 17 "Missing Output" 18 "Systems On" 19 "AC Very High Power" 20 "AC Low Power" 21 "DC Very Low Battery Capacity" 22 "Battery Full" 23 "DC Load Shed Low" 24 "DC Load Shed Very Low" 25 "AC Load Shed Low" 26 "AC Load Shed Very Low" 27 "Reverse Polarity" 28 "Manual Override" 29 "Mastervolt" 30 "Hardware Fault" 31 "No AC Supply" 34 "PGN Switching On" 35 "Low Canbus Voltage" 36 "Blown Fuse" 37 "Manual Bypass" 38 "Generic Alarm" 39 "Battery Temperature Alarm" 40 "Temperature Sensor Error" 41 "AC IN Out Of Range" 42 "Device In Overload" 43 "High Temperature" 44 "Inverter/Charger Installation Error" 45 "Inverter Installation Error" 46 "Charger Installation Error" 47 "Cable Voltage Drop Too High" 48 "Shunt mistmatch" 49 "Cooling Fan Error" 50 "Mastershunt Fuse Blown" 51 "High Temperature" 52 "Over Pressure" 53 "Low Pressure" 54 "Rapid Deflation" 55 "Inverter/Charger Over Temperature" 56 "Confirm On" 57 "Battery Safety" 58 "Stop Charging" 59 "Check Battery Relay" 60 "Battery Hardware Failure" 61 "Battery Over Current" 62 "Battery Temperature Low" 63 "Battery Temperature High" 64 "Battery Last 100" ;
VAL_ 2566852606 industryCode 0 "Global" 1 "Highway" 2 "Agriculture" 3 "Construction" 4 "Marine Industry" 5 "Industrial" ;
VAL_ 2566852606 manufacturerCode 69 "ARKS Enterprises, Inc." 78 "FW Murphy/Enovation Controls" 80 "Twin Disc" 85 "Kohler Power Systems" 88 "Hemisphere GPS Inc" 116 "BEP Marine" 135 "Airmar" 137 "Maretron" 140 "Lowrance" 144 "Mercury Marine" 147 "Nautibus Electronic GmbH" 148 "Blue Water Data" 154 "Westerbeke" 157 "ISSPRO Inc" 161 "Offshore Systems (UK) Ltd." 163 "Evinrude/BRP" 165 "CPAC Systems AB" 168 "Xantrex Technology Inc." 169 "Marlin Technologies, Inc." 172 "Yanmar Marine" 174 "Volvo Penta" 175 "Honda Marine" 176 "Carling Technologies Inc. (Moritz Aerospace)" 185 "Beede Instruments" 192 "Floscan Instrument Co. Inc." 193 "Nobletec" 198 "Mystic Valley Communications" 199 "Actia" 200 "Honda Marine 2" 201 "Disenos Y Technologia" 211 "Digital Switching Systems" 215 "Xintex/Atena" 224 "EMMI NETWORK S.L." 225 "Honda Marine 3" 228 "ZF" 229 "Garmin" 233 "Yacht Monitoring Solutions" 235 "Sailormade Marine Telemetry/Tetra Technology LTD" 243 "Eride" 250 "Honda Marine 4" 257 "Honda Motor Company LTD" 272 "Groco" 273 "Actisense" 274 "Amphenol LTW Technology" 275 "Navico" 283 "Hamilton Jet" 285 "Sea Recovery" 286 "Coelmo SRL Italy" 295 "BEP Marine 2" 304 "Empir Bus" 305 "NovAtel" 306 "Sleipner Motor AS" 307 "MBW Technologies" 311 "Fischer Panda" 315 "ICOM" 328 "Qwerty" 329 "Dief" 341 "Boening Automationstechnologie GmbH & Co. KG" 345 "Korean Maritime University" 351 "Thrane and Thrane" 355 "Mastervolt" 356 "Fischer Panda Generators" 358 "Victron Energy" 370 "Rolls Royce Marine" 373 "Electronic Design" 374 "Northern Lights" 378 "Glendinning" 381 "B & G" 384 "Rose Point Navigation Systems" 385 "Johnson Outdoors Marine Electronics Inc Geonav" 394 "Capi 2" 396 "Beyond Measure" 400 "Livorsi Marine" 404 "ComNav" 409 "Chetco" 419 "Fusion Electronics" 421 "Standard Horizon" 422 "True Heading AB" 426 "Egersund Marine Electronics AS" 427 "em-trak Marine Electronics" 431 "Tohatsu Co, JP" 437 "Digital Yacht" 438 "Comar Systems Limited" 440 "Cummins" 443 "VDO (aka Continental-Corporation)" 451 "Parker Hannifin aka Village Marine Tech" 459 "Alltek Marine Electronics Corp" 460 "SAN GIORGIO S.E.I.N" 466 "Veethree Electronics & Marine" 467 "Humminbird Marine Electronics" 470 "SI-TEX Marine Electronics" 471 "Sea Cross Marine AB" 475 "GME aka Standard Communications Pty LTD" 476 "Humminbird Marine Electronics 2" 478 "Ocean Sat BV" 481 "Chetco Digitial Instruments" 493 "Watcheye" 499 "Lcj Capteurs" 502 "Attwood Marine" 503 "Naviop S.R.L." 504 "Vesper Marine Ltd" 510 "Marinesoft Co. LTD" 513 "Simarine" 517 "NoLand Engineering" 518 "Transas USA" 529 "National Instruments Korea" 530 "National Marine Electronics Association" 532 "Onwa Marine" 540 "Webasto" 571 "Marinecraft (South Korea)" 573 "McMurdo Group aka Orolia LTD" 578 "Advansea" 579 "KVH" 580 "San Jose Technology" 583 "Yacht Control" 586 "Suzuki Motor Corporation" 591 "US Coast Guard" 595 "Ship Module aka Customware" 600 "Aquatic AV" 605 "Aventics GmbH" 606 "Intellian" 612 "SamwonIT" 614 "Arlt Tecnologies" 637 "Bavaria Yacts" 641 "Diverse Yacht Services" 644 "Wema U.S.A dba KUS" 645 "Garmin 2" 658 "Shenzhen Jiuzhou Himunication" 688 "Rockford Corp" 699 "Harman International" 704 "JL Audio" 708 "Lars Thrane" 715 "Autonnic" 717 "Yacht Devices" 734 "REAP Systems" 735 "Au Electronics Group" 739 "LxNav" 741 "Littelfuse, Inc (formerly Carling Technologies)" 743 "DaeMyung" 744 "Woosung" 748 "ISOTTA IFRA srl" 773 "Clarion US" 776 "HMI Systems" 777 "Ocean Signal" 778 "Seekeeper" 781 "Poly Planar" 785 "Fischer Panda DE" 795 "Broyda Industries" 796 "Canadian Automotive" 797 "Tides Marine" 798 "Lumishore" 799 "Still Water Designs and Audio" 802 "BJ Technologies (Beneteau)" 803 "Gill Sensors" 811 "Blue Water Desalination" 815 "FLIR" 824 "Undheim Systems" 826 "Lewmar Inc" 838 "TeamSurv" 844 "Fell Marine" 847 "Oceanvolt" 862 "Prospec" 868 "Data Panel Corp" 890 "L3 Technologies" 894 "Rhodan Marine Systems" 896 "Nexfour Solutions" 905 "ASA Electronics" 909 "Marines Co (South Korea)" 911 "Nautic-on" 917 "Sentinel" 929 "JL Marine ystems" 930 "Ecotronix" 944 "Zontisa Marine" 951 "EXOR International" 962 "Timbolier Industries" 963 "TJC Micro" 968 "Cox Powertrain" 969 "Blue Seas" 981 "Kobelt Manufacturing Co. Ltd" 992 "Blue Ocean IOT" 997 "Xenta Systems" 999 "Signal K" 1004 "Ultraflex SpA" 1008 "Lintest SmartBoat" 1011 "Soundmax" 1020 "Team Italia Marine (Onyx Marine Automation s.r.l)" 1021 "Entratech" 1022 "ITC Inc." 1029 "The Marine Guardian LLC" 1047 "Sonic Corporation" 1051 "ProNav" 1053 "Vetus Maxwell INC." 1056 "Lithium Pros" 1059 "Boatrax" 1062 "Marol Co ltd" 1065 "CALYPSO Instruments" 1066 "Spot Zero Water" 1069 "Lithionics Battery LLC" 1070 "Quick-teck Electronics Ltd" 1075 "Uniden America" 1083 "Nauticoncept" 1084 "Shadow-Caster LED lighting LLC" 1085 "Wet Sounds, LLC" 1088 "E-T-A Circuit Breakers" 1092 "Scheiber" 1100 "Smart Yachts International Limited" 1109 "Dockmate" 1114 "Bobs Machine" 1118 "L3Harris ASV" 1119 "Balmar LLC" 1120 "Elettromedia spa" 1127 "Electromaax" 1140 "Across Oceans Systems Ltd." 1145 "Kiwi Yachting" 1150 "BSB Artificial Intelligence GmbH" 1151 "Orca Technologoes AS" 1154 "TBS Electronics BV" 1158 "Technoton Electroics" 1160 "MG Energy Systems B.V." 1169 "Sea Macine Robotics Inc." 1171 "Vista Manufacturing" 1183 "Zipwake" 1186 "Sailmon BV" 1192 "Airmoniq Pro Kft" 1194 "Sierra Marine" 1200 "Xinuo Information Technology (Xiamen)" 1218 "Septentrio" 1233 "NKE Marine Elecronics" 1238 "SuperTrack Aps" 1239 "Honda Electronics Co., LTD" 1245 "Raritan Engineering Company, Inc" 1249 "Integrated Power Solutions AG" 1260 "Interactive Technologies, Inc." 1283 "LTG-Tech" 1299 "Energy Solutions (UK) LTD." 1300 "WATT Fuel Cell Corp" 1302 "Pro Mainer" 1305 "Dragonfly Energy" 1306 "Koden Electronics Co., Ltd" 1311 "Humphree AB" 1316 "Hinkley Yachts" 1317 "Global Marine Management GmbH (GMM)" 1320 "Triskel Marine Ltd" 1330 "Warwick Control Technologies" 1331 "Dolphin Charger" 1337 "Barnacle Systems Inc" 1348 "Radian IoT, Inc." 1353 "Ocean LED Marine Ltd" 1359 "BluNav" 1361 "OVA (Nantong Saiyang Electronics Co., Ltd)" 1368 "RAD Propulsion" 1369 "Electric Yacht" 1372 "Elco Motor Yachts" 1384 "Tecnoseal Foundry S.r.l" 1385 "Pro Charging Systems, LLC" 1389 "EVEX Co., LTD" 1398 "Gobius Sensor Technology AB" 1403 "Arco Marine" 1408 "Lenco Marine Inc." 1413 "Naocontrol S.L." 1417 "Revatek" 1438 "Aeolionics" 1439 "PredictWind Ltd" 1440 "Egis Mobile Electric" 1445 "Starboard Yacht Group" 1446 "Roswell Marine" 1451 "ePropulsion (Guangdong ePropulsion Technology Ltd.)" 1452 "Micro-Air LLC" 1453 "Vital Battery" 1458 "Ride Controller LLC" 1460 "Tocaro Blue" 1461 "Vanquish Yachts" 1471 "FT Technologies" 1478 "Alps Alpine Co., Ltd." 1481 "E-Force Marine" 1482 "CMC Marine" 1483 "Nanjing Sandemarine Information Technology Co., Ltd." 1850 "Teleflex Marine (SeaStar Solutions)" 1851 "Raymarine" 1852 "Navionics" 1853 "Japan Radio Co" 1854 "Northstar Technologies" 1855 "Furuno" 1856 "Trimble" 1857 "Simrad" 1858 "Litton" 1859 "Kvasar AB" 1860 "MMP" 1861 "Vector Cantech" 1862 "Yamaha Marine" 1863 "Faria Instruments" ;
VAL_ 2566852862 industryCode 0 "Global" 1 "Highway" 2 "Agriculture" 3 "Construction" 4 "Marine Industry" 5 "Industrial" ;
VAL_ 2566852862 manufacturerCode 69 "ARKS Enterprises, Inc." 78 "FW Murphy/Enovation Controls" 80 "Twin Disc" 85 "Kohler Power Systems" 88 "Hemisphere GPS Inc" 116 "BEP Marine" 135 "Airmar" 137 "Maretron" 140 "Lowrance" 144 "Mercury Marine" 147 "Nautibus Electronic GmbH" 148 "Blue Water Data" 154 "Westerbeke" 157 "ISSPRO Inc" 161 "Offshore Systems (UK) Ltd." 163 "Evinrude/BRP" 165 "CPAC Systems AB" 168 "Xantrex Technology Inc." 169 "Marlin Technologies, Inc." 172 "Yanmar Marine" 174 "Volvo Penta" 175 "Honda Marine" 176 "Carling Technologies Inc. (Moritz Aerospace)" 185 "Beede Instruments" 192 "Floscan Instrument Co. Inc." 193 "Nobletec" 198 "Mystic Valley Communications" 199 "Actia" 200 "Honda Marine 2" 201 "Disenos Y Technologia" 211 "Digital Switching Systems" 215 "Xintex/Atena" 224 "EMMI NETWORK S.L." 225 "Honda Marine 3" 228 "ZF" 229 "Garmin" 233 "Yacht Monitoring Solutions" 235 "Sailormade Marine Telemetry/Tetra Technology LTD" 243 "Eride" 250 "Honda Marine 4" 257 "Honda Motor Company LTD" 272 "Groco" 273 "Actisense" 274 "Amphenol LTW Technology" 275 "Navico" 283 "Hamilton Jet" 285 "Sea Recovery" 286 "Coelmo SRL Italy" 295 "BEP Marine 2" 304 "Empir Bus" 305 "NovAtel" 306 "Sleipner Motor AS" 307 "MBW Technologies" 311 "Fischer Panda" 315 "ICOM" 328 "Qwerty" 329 "Dief" 341 "Boening Automationstechnologie GmbH & Co. KG" 345 "Korean Maritime University" 351 "Thrane and Thrane" 355 "Mastervolt" 356 "Fischer Panda Generators" 358 "Victron Energy" 370 "Rolls Royce Marine" 373 "Electronic Design" 374 "Northern Lights" 378 "Glendinning" 381 "B & G" 384 "Rose Point Navigation Systems" 385 "Johnson Outdoors Marine Electronics Inc Geonav" 394 "Capi 2" 396 "Beyond Measure" 400 "Livorsi Marine" 404 "ComNav" 409 "Chetco" 419 "Fusion Electronics" 421 "Standard Horizon" 422 "True Heading AB" 426 "Egersund Marine Electronics AS" 427 "em-trak Marine Electronics" 431 "Tohatsu Co, JP" 437 "Digital Yacht" 438 "Comar Systems Limited" 440 "Cummins" 443 "VDO (aka Continental-Corporation)" 451 "Parker Hannifin aka Village Marine Tech" 459 "Alltek Marine Electronics Corp" 460 "SAN GIORGIO S.E.I.N" 466 "Veethree Electronics & Marine" 467 "Humminbird Marine Electronics" 470 "SI-TEX Marine Electronics" 471 "Sea Cross Marine AB" 475 "GME aka Standard Communications Pty LTD" 476 "Humminbird Marine Electronics 2" 478 "Ocean Sat BV" 481 "Chetco Digitial Instruments" 493 "Watcheye" 499 "Lcj Capteurs" 502 "Attwood Marine" 503 "Naviop S.R.L." 504 "Vesper Marine Ltd" 510 "Marinesoft Co. LTD" 513 "Simarine" 517 "NoLand Engineering" 518 "Transas USA" 529 "National Instruments Korea" 530 "National Marine Electronics Association" 532 "Onwa Marine" 540 "Webasto" 571 "Marinecraft (South Korea)" 573 "McMurdo Group aka Orolia LTD" 578 "Advansea" 579 "KVH" 580 "San Jose Technology" 583 "Yacht Control" 586 "Suzuki Motor Corporation" 591 "US Coast Guard" 595 "Ship Module aka Customware" 600 "Aquatic AV" 605 "Aventics GmbH" 606 "Intellian" 612 "SamwonIT" 614 "Arlt Tecnologies" 637 "Bavaria Yacts" 641 "Diverse Yacht Services" 644 "Wema U.S.A dba KUS" 645 "Garmin 2" 658 "Shenzhen Jiuzhou Himunication" 688 "Rockford Corp" 699 "Harman International" 704 "JL Audio" 708 "Lars Thrane" 715 "Autonnic" 717 "Yacht Devices" 734 "REAP Systems" 735 "Au Electronics Group" 739 "LxNav" 741 "Littelfuse, Inc (formerly Carling Technologies)" 743 "DaeMyung" 744 "Woosung" 748 "ISOTTA IFRA srl" 773 "Clarion US" 776 "HMI Systems" 777 "Ocean Signal" 778 "Seekeeper" 781 "Poly Planar" 785 "Fischer Panda DE" 795 "Broyda Industries" 796 "Canadian Automotive" 797 "Tides Marine" 798 "Lumishore" 799 "Still Water Designs and Audio" 802 "BJ Technologies (Beneteau)" 803 "Gill Sensors" 811 "Blue Water Desalination" 815 "FLIR" 824 "Undheim Systems" 826 "Lewmar Inc" 838 "TeamSurv" 844 "Fell Marine" 847 "Oceanvolt" 862 "Prospec" 868 "Data Panel Corp" 890 "L3 Technologies" 894 "Rhodan Marine Systems" 896 "Nexfour Solutions" 905 "ASA Electronics" 909 "Marines Co (South Korea)" 911 "Nautic-on" 917 "Sentinel" 929 "JL Marine ystems" 930 "Ecotronix" 944 "Zontisa Marine" 951 "EXOR International" 962 "Timbolier Industries" 963 "TJC Micro" 968 "Cox Powertrain" 969 "Blue Seas" 981 "Kobelt Manufacturing Co. Ltd" 992 "Blue Ocean IOT" 997 "Xenta Systems" 999 "Signal K" 1004 "Ultraflex SpA" 1008 "Lintest SmartBoat" 1011 "Soundmax" 1020 "Team Italia Marine (Onyx Marine Automation s.r.l)" 1021 "Entratech" 1022 "ITC Inc." 1029 "The Marine Guardian LLC" 1047 "Sonic Corporation" 1051 "ProNav" 1053 "Vetus Maxwell INC." 1056 "Lithium Pros" 1059 "Boatrax" 1062 "Marol Co ltd" 1065 "CALYPSO Instruments" 1066 "Spot Zero Water" 1069 "Lithionics Battery LLC" 1070 "Quick-teck Electronics Ltd" 1075 "Uniden America" 1083 "Nauticoncept" 1084 "Shadow-Caster LED lighting LLC" 1085 "Wet Sounds, LLC" 1088 "E-T-A Circuit Breakers" 1092 "Scheiber" 1100 "Smart Yachts International Limited" 1109 "Dockmate" 1114 "Bobs Machine" 1118 "L3Harris ASV" 1119 "Balmar LLC" 1120 "Elettromedia spa" 1127 "Electromaax" 1140 "Across Oceans Systems Ltd." 1145 "Kiwi Yachting" 1150 "BSB Artificial Intelligence GmbH" 1151 "Orca Technologoes AS" 1154 "TBS Electronics BV" 1158 "Technoton Electroics" 1160 "MG Energy Systems B.V." 1169 "Sea Macine Robotics Inc." 1171 "Vista Manufacturing" 1183 "Zipwake" 1186 "Sailmon BV" 1192 "Airmoniq Pro Kft" 1194 "Sierra Marine" 1200 "Xinuo Information Technology (Xiamen)" 1218 "Septentrio" 1233 "NKE Marine Elecronics" 1238 "SuperTrack Aps" 1239 "Honda Electronics Co., LTD" 1245 "Raritan Engineering Company, Inc" 1249 "Integrated Power Solutions AG" 1260 "Interactive Technologies, Inc." 1283 "LTG-Tech" 1299 "Energy Solutions (UK) LTD." 1300 "WATT Fuel Cell Corp" 1302 "Pro Mainer" 1305 "Dragonfly Energy" 1306 "Koden Electronics Co., Ltd" 1311 "Humphree AB" 1316 "Hinkley Yachts" 1317 "Global Marine Management GmbH (GMM)" 1320 "Triskel Marine Ltd" 1330 "Warwick Control Technologies" 1331 "Dolphin Charger" 1337 "Barnacle Systems Inc" 1348 "Radian IoT, Inc." 1353 "Ocean LED Marine Ltd" 1359 "BluNav" 1361 "OVA (Nantong Saiyang Electronics Co., Ltd)" 1368 "RAD Propulsion" 1369 "Electric Yacht" 1372 "Elco Motor Yachts" 1384 "Tecnoseal Foundry S.r.l" 1385 "Pro Charging Systems, LLC" 1389 "EVEX Co., LTD" 1398 "Gobius Sensor Technology AB" 1403 "Arco Marine" 1408 "Lenco Marine Inc." 1413 "Naocontrol S.L." 1417 "Revatek" 1438 "Aeolionics" 1439 "PredictWind Ltd" 1440 "Egis Mobile Electric" 1445 "Starboard Yacht Group" 1446 "Roswell Marine" 1451 "ePropulsion (Guangdong ePropulsion Technology Ltd.)" 1452 "Micro-Air LLC" 1453 "Vital Battery" 1458 "Ride Controller LLC" 1460 "Tocaro Blue" 1461 "Vanquish Yachts" 1471 "FT Technologies" 1478 "Alps Alpine Co., Ltd." 1481 "E-Force Marine" 1482 "CMC Marine" 1483 "Nanjing Sandemarine Information Technology Co., Ltd." 1850 "Teleflex Marine (SeaStar Solutions)" 1851 "Raymarine" 1852 "Navionics" 1853 "Japan Radio Co" 1854 "Northstar Technologies" 1855 "Furuno" 1856 "Trimble" 1857 "Simrad" 1858 "Litton" 1859 "Kvasar AB" 1860 "MMP" 1861 "Vector Cantech" 1862 "Yamaha Marine" 1863 "Faria Instruments" ;
VAL_ 2566853118 industryCode 0 "Global" 1 "Highway" 2 "Agriculture" 3 "Construction" 4 "Marine Industry" 5 "Industrial" ;
VAL_ 2566853118 manufacturerCode 69 "ARKS Enterprises, Inc." 78 "FW Murphy/Enovation Controls" 80 "Twin Disc" 85 "Kohler Power Systems" 88 "Hemisphere GPS Inc" 116 "BEP Marine" 135 "Airmar" 137 "Maretron" 140 "Lowrance" 144 "Mercury Marine" 147 "Nautibus Electronic GmbH" 148 "Blue Water Data" 154 "Westerbeke" 157 "ISSPRO Inc" 161 "Offshore Systems (UK) Ltd." 163 "Evinrude/BRP" 165 "CPAC Systems AB" 168 "Xantrex Technology Inc." 169 "Marlin Technologies, Inc." 172 "Yanmar Marine" 174 "Volvo Penta" 175 "Honda Marine" 176 "Carling Technologies Inc. (Moritz Aerospace)" 185 "Beede Instruments" 192 "Floscan Instrument Co. Inc." 193 "Nobletec" 198 "Mystic Valley Communications" 199 "Actia" 200 "Honda Marine 2" 201 "Disenos Y Technologia" 211 "Digital Switching Systems" 215 "Xintex/Atena" 224 "EMMI NETWORK S.L." 225 "Honda Marine 3" 228 "ZF" 229 "Garmin" 233 "Yacht Monitoring Solutions" 235 "Sailormade Marine Telemetry/Tetra Technology LTD" 243 "Eride" 250 "Honda Marine 4" 257 "Honda Motor Company LTD" 272 "Groco" 273 "Actisense" 274 "Amphenol LTW Technology" 275 "Navico" 283 "Hamilton Jet" 285 "Sea Recovery" 286 "Coelmo SRL Italy" 295 "BEP Marine 2" 304 "Empir Bus" 305 "NovAtel" 306 "Sleipner Motor AS" 307 "MBW Technologies" 311 "Fischer Panda" 315 "ICOM" 328 "Qwerty" 329 "Dief" 341 "Boening Automationstechnologie GmbH & Co. KG" 345 "Korean Maritime University" 351 "Thrane and Thrane" 355 "Mastervolt" 356 "Fischer Panda Generators" 358 "Victron Energy" 370 "Rolls Royce Marine" 373 "Electronic Design" 374 "Northern Lights" 378 "Glendinning" 381 "B & G" 384 "Rose Point Navigation Systems" 385 "Johnson Outdoors Marine Electronics Inc Geonav" 394 "Capi 2" 396 "Beyond Measure" 400 "Livorsi Marine" 404 "ComNav" 409 "Chetco" 419 "Fusion Electronics" 421 "Standard Horizon" 422 "True Heading AB" 426 "Egersund Marine Electronics AS" 427 "em-trak Marine Electronics" 431 "Tohatsu Co, JP" 437 "Digital Yacht" 438 "Comar Systems Limited" 440 "Cummins" 443 "VDO (aka Continental-Corporation)" 451 "Parker Hannifin aka Village Marine Tech" 459 "Alltek Marine Electronics Corp" 460 "SAN GIORGIO S.E.I.N" 466 "Veethree Electronics & Marine" 467 "Humminbird Marine Electronics" 470 "SI-TEX Marine Electronics" 471 "Sea Cross Marine AB" 475 "GME aka Standard Communications Pty LTD" 476 "Humminbird Marine Electronics 2" 478 "Ocean Sat BV" 481 "Chetco Digitial Instruments" 493 "Watcheye" 499 "Lcj Capteurs" 502 "Attwood Marine" 503 "Naviop S.R.L." 504 "Vesper Marine Ltd" 510 "Marinesoft Co. LTD" 513 "Simarine" 517 "NoLand Engineering" 518 "Transas USA" 529 "National Instruments Korea" 530 "National Marine Electronics Association" 532 "Onwa Marine" 540 "Webasto" 571 "Marinecraft (South Korea)" 573 "McMurdo Group aka Orolia LTD" 578 "Advansea" 579 "KVH" 580 "San Jose Technology" 583 "Yacht Control" 586 "Suzuki Motor Corporation" 591 "US Coast Guard" 595 "Ship Module aka Customware" 600 "Aquatic AV" 605 "Aventics GmbH" 606 "Intellian" 612 "SamwonIT" 614 "Arlt Tecnologies" 637 "Bavaria Yacts" 641 "Diverse Yacht Services" 644 "Wema U.S.A dba KUS" 645 "Garmin 2" 658 "Shenzhen Jiuzhou Himunication" 688 "Rockford Corp" 699 "Harman International" 704 "JL Audio" 708 "Lars Thrane" 715 "Autonnic" 717 "Yacht Devices" 734 "REAP Systems" 735 "Au Electronics Group" 739 "LxNav" 741 "Littelfuse, Inc (formerly Carling Technologies)" 743 "DaeMyung" 744 "Woosung" 748 "ISOTTA IFRA srl" 773 "Clarion US" 776 "HMI Systems" 777 "Ocean Signal" 778 "Seekeeper" 781 "Poly Planar" 785 "Fischer Panda DE" 795 "Broyda Industries" 796 "Canadian Automotive" 797 "Tides Marine" 798 "Lumishore" 799 "Still Water Designs and Audio" 802 "BJ Technologies (Beneteau)" 803 "Gill Sensors" 811 "Blue Water Desalination" 815 "FLIR" 824 "Undheim Systems" 826 "Lewmar Inc" 838 "TeamSurv" 844 "Fell Marine" 847 "Oceanvolt" 862 "Prospec" 868 "Data Panel Corp" 890 "L3 Technologies" 894 "Rhodan Marine Systems" 896 "Nexfour Solutions" 905 "ASA Electronics" 909 "Marines Co (South Korea)" 911 "Nautic-on" 917 "Sentinel" 929 "JL Marine ystems" 930 "Ecotronix" 944 "Zontisa Marine" 951 "EXOR International" 962 "Timbolier Industries" 963 "TJC Micro" 968 "Cox Powertrain" 969 "Blue Seas" 981 "Kobelt Manufacturing Co. Ltd" 992 "Blue Ocean IOT" 997 "Xenta Systems" 999 "Signal K" 1004 "Ultraflex SpA" 1008 "Lintest SmartBoat" 1011 "Soundmax" 1020 "Team Italia Marine (Onyx Marine Automation s.r.l)" 1021 "Entratech" 1022 "ITC Inc." 1029 "The Marine Guardian LLC" 1047 "Sonic Corporation" 1051 "ProNav" 1053 "Vetus Maxwell INC." 1056 "Lithium Pros" 1059 "Boatrax" 1062 "Marol Co ltd" 1065 "CALYPSO Instruments" 1066 "Spot Zero Water" 1069 "Lithionics Battery LLC" 1070 "Quick-teck Electronics Ltd" 1075 "Uniden America" 1083 "Nauticoncept" 1084 "Shadow-Caster LED lighting LLC" 1085 "Wet Sounds, LLC" 1088 "E-T-A Circuit Breakers" 1092 "Scheiber" 1100 "Smart Yachts International Limited" 1109 "Dockmate" 1114 "Bobs Machine" 1118 "L3Harris ASV" 1119 "Balmar LLC" 1120 "Elettromedia spa" 1127 "Electromaax" 1140 "Across Oceans Systems Ltd." 1145 "Kiwi Yachting" 1150 "BSB Artificial Intelligence GmbH" 1151 "Orca Technologoes AS" 1154 "TBS Electronics BV" 1158 "Technoton Electroics" 1160 "MG Energy Systems B.V." 1169 "Sea Macine Robotics Inc." 1171 "Vista Manufacturing" 1183 "Zipwake" 1186 "Sailmon BV" 1192 "Airmoniq Pro Kft" 1194 "Sierra Marine" 1200 "Xinuo Information Technology (Xiamen)" 1218 "Septentrio" 1233 "NKE Marine Elecronics" 1238 "SuperTrack Aps" 1239 "Honda Electronics Co., LTD" 1245 "Raritan Engineering Company, Inc" 1249 "Integrated Power Solutions AG" 1260 "Interactive Technologies, Inc." 1283 "LTG-Tech" 1299 "Energy Solutions (UK) LTD." 1300 "WATT Fuel Cell Corp" 1302 "Pro Mainer" 1305 "Dragonfly Energy" 1306 "Koden Electronics Co., Ltd" 1311 "Humphree AB" 1316 "Hinkley Yachts" 1317 "Global Marine Management GmbH (GMM)" 1320 "Triskel Marine Ltd" 1330 "Warwick Control Technologies" 1331 "Dolphin Charger" 1337 "Barnacle Systems Inc" 1348 "Radian IoT, Inc." 1353 "Ocean LED Marine Ltd" 1359 "BluNav" 1361 "OVA (Nantong Saiyang Electronics Co., Ltd)" 1368 "RAD Propulsion" 1369 "Electric Yacht" 1372 "Elco Motor Yachts" 1384 "Tecnoseal Foundry S.r.l" 1385 "Pro Charging Systems, LLC" 1389 "EVEX Co., LTD" 1398 "Gobius Sensor Technology AB" 1403 "Arco Marine" 1408 "Lenco Marine Inc." 1413 "Naocontrol S.L." 1417 "Revatek" 1438 "Aeolionics" 1439 "PredictWind Ltd" 1440 "Egis Mobile Electric" 1445 "Starboard Yacht Group" 1446 "Roswell Marine" 1451 "ePropulsion (Guangdong ePropulsion Technology Ltd.)" 1452 "Micro-Air LLC" 1453 "Vital Battery" 1458 "Ride Controller LLC" 1460 "Tocaro Blue" 1461 "Vanquish Yachts" 1471 "FT Technologies" 1478 "Alps Alpine Co., Ltd." 1481 "E-Force Marine" 1482 "CMC Marine" 1483 "Nanjing Sandemarine Information Technology Co., Ltd." 1850 "Teleflex Marine (SeaStar Solutions)" 1851 "Raymarine" 1852 "Navionics" 1853 "Japan Radio Co" 1854 "Northstar Technologies" 1855 "Furuno" 1856 "Trimble" 1857 "Simrad" 1858 "Litton" 1859 "Kvasar AB" 1860 "MMP" 1861 "Vector Cantech" 1862 "Yamaha Marine" 1863 "Faria Instruments" ;
VAL_ 2566853374 industryCode 0 "Global" 1 "Highway" 2 "Agriculture" 3 "Construction" 4 "Marine Industry" 5 "Industrial" ;
VAL_ 2566853374 manufacturerCode 69 "ARKS Enterprises, Inc." 78 "FW Murphy/Enovation Controls" 80 "Twin Disc" 85 "Kohler Power Systems" 88 "Hemisphere GPS Inc" 116 "BEP Marine" 135 "Airmar" 137 "Maretron" 140 "Lowrance" 144 "Mercury Marine" 147 "Nautibus Electronic GmbH" 148 "Blue Water Data" 154 "Westerbeke" 157 "ISSPRO Inc" 161 "Offshore Systems (UK) Ltd." 163 "Evinrude/BRP" 165 "CPAC Systems AB" 168 "Xantrex Technology Inc." 169 "Marlin Technologies, Inc." 172 "Yanmar Marine" 174 "Volvo Penta" 175 "Honda Marine" 176 "Carling Technologies Inc. (Moritz Aerospace)" 185 "Beede Instruments" 192 "Floscan Instrument Co. Inc." 193 "Nobletec" 198 "Mystic Valley Communications" 199 "Actia" 200 "Honda Marine 2" 201 "Disenos Y Technologia" 211 "Digital Switching Systems" 215 "Xintex/Atena" 224 "EMMI NETWORK S.L." 225 "Honda Marine 3" 228 "ZF" 229 "Garmin" 233 "Yacht Monitoring Solutions" 235 "Sailormade Marine Telemetry/Tetra Technology LTD" 243 "Eride" 250 "Honda Marine 4" 257 "Honda Motor Company LTD" 272 "Groco" 273 "Actisense" 274 "Amphenol LTW Technology" 275 "Navico" 283 "Hamilton Jet" 285 "Sea Recovery" 286 "Coelmo SRL Italy" 295 "BEP Marine 2" 304 "Empir Bus" 305 "NovAtel" 306 "Sleipner Motor AS" 307 "MBW Technologies" 311 "Fischer Panda" 315 "ICOM" 328 "Qwerty" 329 "Dief" 341 "Boening Automationstechnologie GmbH & Co. KG" 345 "Korean Maritime University" 351 "Thrane and Thrane" 355 "Mastervolt" 356 "Fischer Panda Generators" 358 "Victron Energy" 370 "Rolls Royce Marine" 373 "Electronic Design" 374 "Northern Lights" 378 "Glendinning" 381 "B & G" 384 "Rose Point Navigation Systems" 385 "Johnson Outdoors Marine Electronics Inc Geonav" 394 "Capi 2" 396 "Beyond Measure" 400 "Livorsi Marine" 404 "ComNav" 409 "Chetco" 419 "Fusion Electronics" 421 "Standard Horizon" 422 "True Heading AB" 426 "Egersund Marine Electronics AS" 427 "em-trak Marine Electronics" 431 "Tohatsu Co, JP" 437 "Digital Yacht" 438 "Comar Systems Limited" 440 "Cummins" 443 "VDO (aka Continental-Corporation)" 451 "Parker Hannifin aka Village Marine Tech" 459 "Alltek Marine Electronics Corp" 460 "SAN GIORGIO S.E.I.N" 466 "Veethree Electronics & Marine" 467 "Humminbird Marine Electronics" 470 "SI-TEX Marine Electronics" 471 "Sea Cross Marine AB" 475 "GME aka Standard Communications Pty LTD" 476 "Humminbird Marine Electronics 2" 478 "Ocean Sat BV" 481 "Chetco Digitial Instruments" 493 "Watcheye" 499 "Lcj Capteurs" 502 "Attwood Marine" 503 "Naviop S.R.L." 504 "Vesper Marine Ltd" 510 "Marinesoft Co. LTD" 513 "Simarine" 517 "NoLand Engineering" 518 "Transas USA" 529 "National Instruments Korea" 530 "National Marine Electronics Association" 532 "Onwa Marine" 540 "Webasto" 571 "Marinecraft (South Korea)" 573 "McMurdo Group aka Orolia LTD" 578 "Advansea" 579 "KVH" 580 "San Jose Technology" 583 "Yacht Control" 586 "Suzuki Motor Corporation" 591 "US Coast Guard" 595 "Ship Module aka Customware" 600 "Aquatic AV" 605 "Aventics GmbH" 606 "Intellian" 612 "SamwonIT" 614 "Arlt Tecnologies" 637 "Bavaria Yacts" 641 "Diverse Yacht Services" 644 "Wema U.S.A dba KUS" 645 "Garmin 2" 658 "Shenzhen Jiuzhou Himunication" 688 "Rockford Corp" 699 "Harman International" 704 "JL Audio" 708 "Lars Thrane" 715 "Autonnic" 717 "Yacht Devices" 734 "REAP Systems" 735 "Au Electronics Group" 739 "LxNav" 741 "Littelfuse, Inc (formerly Carling Technologies)" 743 "DaeMyung" 744 "Woosung" 748 "ISOTTA IFRA srl" 773 "Clarion US" 776 "HMI Systems" 777 "Ocean Signal" 778 "Seekeeper" 781 "Poly Planar" 785 "Fischer Panda DE" 795 "Broyda Industries" 796 "Canadian Automotive" 797 "Tides Marine" 798 "Lumishore" 799 "Still Water Designs and Audio" 802 "BJ Technologies (Beneteau)" 803 "Gill Sensors" 811 "Blue Water Desalination" 815 "FLIR" 824 "Undheim Systems" 826 "Lewmar Inc" 838 "TeamSurv" 844 "Fell Marine" 847 "Oceanvolt" 862 "Prospec" 868 "Data Panel Corp" 890 "L3 Technologies" 894 "Rhodan Marine Systems" 896 "Nexfour Solutions" 905 "ASA Electronics" 909 "Marines Co (South Korea)" 911 "Nautic-on" 917 "Sentinel" 929 "JL Marine ystems" 930 "Ecotronix" 944 "Zontisa Marine" 951 "EXOR International" 962 "Timbolier Industries" 963 "TJC Micro" 968 "Cox Powertrain" 969 "Blue Seas" 981 "Kobelt Manufacturing Co. Ltd" 992 "Blue Ocean IOT" 997 "Xenta Systems" 999 "Signal K" 1004 "Ultraflex SpA" 1008 "Lintest SmartBoat" 1011 "Soundmax" 1020 "Team Italia Marine (Onyx Marine Automation s.r.l)" 1021 "Entratech" 1022 "ITC Inc." 1029 "The Marine Guardian LLC" 1047 "Sonic Corporation" 1051 "ProNav" 1053 "Vetus Maxwell INC." 1056 "Lithium Pros" 1059 "Boatrax" 1062 "Marol Co ltd" 1065 "CALYPSO Instruments" 1066 "Spot Zero Water" 1069 "Lithionics Battery LLC" 1070 "Quick-teck Electronics Ltd" 1075 "Uniden America" 1083 "Nauticoncept" 1084 "Shadow-Caster LED lighting LLC" 1085 "Wet Sounds, LLC" 1088 "E-T-A Circuit Breakers" 1092 "Scheiber" 1100 "Smart Yachts International Limited" 1109 "Dockmate" 1114 "Bobs Machine" 1118 "L3Harris ASV" 1119 "Balmar LLC" 1120 "Elettromedia spa" 1127 "Electromaax" 1140 "Across Oceans Systems Ltd." 1145 "Kiwi Yachting" 1150 "BSB Artificial Intelligence GmbH" 1151 "Orca Technologoes AS" 1154 "TBS Electronics BV" 1158 "Technoton Electroics" 1160 "MG Energy Systems B.V." 1169 "Sea Macine Robotics Inc." 1171 "Vista Manufacturing" 1183 "Zipwake" 1186 "Sailmon BV" 1192 "Airmoniq Pro Kft" 1194 "Sierra Marine" 1200 "Xinuo Information Technology (Xiamen)" 1218 "Septentrio" 1233 "NKE Marine Elecronics" 1238 "SuperTrack Aps" 1239 "Honda Electronics Co., LTD" 1245 "Raritan Engineering Company, Inc" 1249 "Integrated Power Solutions AG" 1260 "Interactive Technologies, Inc." 1283 "LTG-Tech" 1299 "Energy Solutions (UK) LTD." 1300 "WATT Fuel Cell Corp" 1302 "Pro Mainer" 1305 "Dragonfly Energy" 1306 "Koden Electronics Co., Ltd" 1311 "Humphree AB" 1316 "Hinkley Yachts" 1317 "Global Marine Management GmbH (GMM)" 1320 "Triskel Marine Ltd" 1330 "Warwick Control Technologies" 1331 "Dolphin Charger" 1337 "Barnacle Systems Inc" 1348 "Radian IoT, Inc." 1353 "Ocean LED Marine Ltd" 1359 "BluNav" 1361 "OVA (Nantong Saiyang Electronics Co., Ltd)" 1368 "RAD Propulsion" 1369 "Electric Yacht" 1372 "Elco Motor Yachts" 1384 "Tecnoseal Foundry S.r.l" 1385 "Pro Charging Systems, LLC" 1389 "EVEX Co., LTD" 1398 "Gobius Sensor Technology AB" 1403 "Arco Marine" 1408 "Lenco Marine Inc." 1413 "Naocontrol S.L." 1417 "Revatek" 1438 "Aeolionics" 1439 "PredictWind Ltd" 1440 "Egis Mobile Electric" 1445 "Starboard Yacht Group" 1446 "Roswell Marine" 1451 "ePropulsion (Guangdong ePropulsion Technology Ltd.)" 1452 "Micro-Air LLC" 1453 "Vital Battery" 1458 "Ride Controller LLC" 1460 "Tocaro Blue" 1461 "Vanquish Yachts" 1471 "FT Technologies" 1478 "Alps Alpine Co., Ltd." 1481 "E-Force Marine" 1482 "CMC Marine" 1483 "Nanjing Sandemarine Information Technology Co., Ltd." 1850 "Teleflex Marine (SeaStar Solutions)" 1851 "Raymarine" 1852 "Navionics" 1853 "Japan Radio Co" 1854 "Northstar Technologies" 1855 "Furuno" 1856 "Trimble" 1857 "Simrad" 1858 "Litton" 1859 "Kvasar AB" 1860 "MMP" 1861 "Vector Cantech" 1862 "Yamaha Marine" 1863 "Faria Instruments" ;
VAL_ 2566854142 industryCode 0 "Global" 1 "Highway" 2 "Agriculture" 3 "Construction" 4 "Marine Industry" 5 "Industrial" ;
VAL_ 2566854142 manufacturerCode 69 "ARKS Enterprises, Inc." 78 "FW Murphy/Enovation Controls" 80 "Twin Disc" 85 "Kohler Power Systems" 88 "Hemisphere GPS Inc" 116 "BEP Marine" 135 "Airmar" 137 "Maretron" 140 "Lowrance" 144 "Mercury Marine" 147 "Nautibus Electronic GmbH" 148 "Blue Water Data" 154 "Westerbeke" 157 "ISSPRO Inc" 161 "Offshore Systems (UK) Ltd." 163 "Evinrude/BRP" 165 "CPAC Systems AB" 168 "Xantrex Technology Inc." 169 "Marlin Technologies, Inc." 172 "Yanmar Marine" 174 "Volvo Penta" 175 "Honda Marine" 176 "Carling Technologies Inc. (Moritz Aerospace)" 185 "Beede Instruments" 192 "Floscan Instrument Co. Inc." 193 "Nobletec" 198 "Mystic Valley Communications" 199 "Actia" 200 "Honda Marine 2" 201 "Disenos Y Technologia" 211 "Digital Switching Systems" 215 "Xintex/Atena" 224 "EMMI NETWORK S.L." 225 "Honda Marine 3" 228 "ZF" 229 "Garmin" 233 "Yacht Monitoring Solutions" 235 "Sailormade Marine Telemetry/Tetra Technology LTD" 243 "Eride" 250 "Honda Marine 4" 257 "Honda Motor Company LTD" 272 "Groco" 273 "Actisense" 274 "Amphenol LTW Technology" 275 "Navico" 283 "Hamilton Jet" 285 "Sea Recovery" 286 "Coelmo SRL Italy" 295 "BEP Marine 2" 304 "Empir Bus" 305 "NovAtel" 306 "Sleipner Motor AS" 307 "MBW Technologies" 311 "Fischer Panda" 315 "ICOM" 328 "Qwerty" 329 "Dief" 341 "Boening Automationstechnologie GmbH & Co. KG" 345 "Korean Maritime University" 351 "Thrane and Thrane" 355 "Mastervolt" 356 "Fischer Panda Generators" 358 "Victron Energy" 370 "Rolls Royce Marine" 373 "Electronic Design" 374 "Northern Lights" 378 "Glendinning" 381 "B & G" 384 "Rose Point Navigation Systems" 385 "Johnson Outdoors Marine Electronics Inc Geonav" 394 "Capi 2" 396 "Beyond Measure" 400 "Livorsi Marine" 404 "ComNav" 409 "Chetco" 419 "Fusion Electronics" 421 "Standard Horizon" 422 "True Heading AB" 426 "Egersund Marine Electronics AS" 427 "em-trak Marine Electronics" 431 "Tohatsu Co, JP" 437 "Digital Yacht" 438 "Comar Systems Limited" 440 "Cummins" 443 "VDO (aka Continental-Corporation)" 451 "Parker Hannifin aka Village Marine Tech" 459 "Alltek Marine Electronics Corp" 460 "SAN GIORGIO S.E.I.N" 466 "Veethree Electronics & Marine" 467 "Humminbird Marine Electronics" 470 "SI-TEX Marine Electronics" 471 "Sea Cross Marine AB" 475 "GME aka Standard Communications Pty LTD" 476 "Humminbird Marine Electronics 2" 478 "Ocean Sat BV" 481 "Chetco Digitial Instruments" 493 "Watcheye" 499 "Lcj Capteurs" 502 "Attwood Marine" 503 "Naviop S.R.L." 504 "Vesper Marine Ltd" 510 "Marinesoft Co. LTD" 513 "Simarine" 517 "NoLand Engineering" 518 "Transas USA" 529 "National Instruments Korea" 530 "National Marine Electronics Association" 532 "Onwa Marine" 540 "Webasto" 571 "Marinecraft (South Korea)" 573 "McMurdo Group aka Orolia LTD" 578 "Advansea" 579 "KVH" 580 "San Jose Technology" 583 "Yacht Control" 586 "Suzuki Motor Corporation" 591 "US Coast Guard" 595 "Ship Module aka Customware" 600 "Aquatic AV" 605 "Aventics GmbH" 606 "Intellian" 612 "SamwonIT" 614 "Arlt Tecnologies" 637 "Bavaria Yacts" 641 "Diverse Yacht Services" 644 "Wema U.S.A dba KUS" 645 "Garmin 2" 658 "Shenzhen Jiuzhou Himunication" 688 "Rockford Corp" 699 "Harman International" 704 "JL Audio" 708 "Lars Thrane" 715 "Autonnic" 717 "Yacht Devices" 734 "REAP Systems" 735 "Au Electronics Group" 739 "LxNav" 741 "Littelfuse, Inc (formerly Carling Technologies)" 743 "DaeMyung" 744 "Woosung" 748 "ISOTTA IFRA srl" 773 "Clarion US" 776 "HMI Systems" 777 "Ocean Signal" 778 "Seekeeper" 781 "Poly Planar" 785 "Fischer Panda DE" 795 "Broyda Industries" 796 "Canadian Automotive" 797 "Tides Marine" 798 "Lumishore" 799 "Still Water Designs and Audio" 802 "BJ Technologies (Beneteau)" 803 "Gill Sensors" 811 "Blue Water Desalination" 815 "FLIR" 824 "Undheim Systems" 826 "Lewmar Inc" 838 "TeamSurv" 844 "Fell Marine" 847 "Oceanvolt" 862 "Prospec" 868 "Data Panel Corp" 890 "L3 Technologies" 894 "Rhodan Marine Systems" 896 "Nexfour Solutions" 905 "ASA Electronics" 909 "Marines Co (South Korea)" 911 "Nautic-on" 917 "Sentinel" 929 "JL Marine ystems" 930 "Ecotronix" 944 "Zontisa Marine" 951 "EXOR International" 962 "Timbolier Industries" 963 "TJC Micro" 968 "Cox Powertrain" 969 "Blue Seas" 981 "Kobelt Manufacturing Co. Ltd" 992 "Blue Ocean IOT" 997 "Xenta Systems" 999 "Signal K" 1004 "Ultraflex SpA" 1008 "Lintest SmartBoat" 1011 "Soundmax" 1020 "Team Italia Marine (Onyx Marine Automation s.r.l)" 1021 "Entratech" 1022 "ITC Inc." 1029 "The Marine Guardian LLC" 1047 "Sonic Corporation" 1051 "ProNav" 1053 "Vetus Maxwell INC." 1056 "Lithium Pros" 1059 "Boatrax" 1062 "Marol Co ltd" 1065 "CALYPSO Instruments" 1066 "Spot Zero Water" 1069 "Lithionics Battery LLC" 1070 "Quick-teck Electronics Ltd" 1075 "Uniden America" 1083 "Nauticoncept" 1084 "Shadow-Caster LED lighting LLC" 1085 "Wet Sounds, LLC" 1088 "E-T-A Circuit Breakers" 1092 "Scheiber" 1100 "Smart Yachts International Limited" 1109 "Dockmate" 1114 "Bobs Machine" 1118 "L3Harris ASV" 1119 "Balmar LLC" 1120 "Elettromedia spa" 1127 "Electromaax" 1140 "Across Oceans Systems Ltd." 1145 "Kiwi Yachting" 1150 "BSB Artificial Intelligence GmbH" 1151 "Orca Technologoes AS" 1154 "TBS Electronics BV" 1158 "Technoton Electroics" 1160 "MG Energy Systems B.V." 1169 "Sea Macine Robotics Inc." 1171 "Vista Manufacturing" 1183 "Zipwake" 1186 "Sailmon BV" 1192 "Airmoniq Pro Kft" 1194 "Sierra Marine" 1200 "Xinuo Information Technology (Xiamen)" 1218 "Septentrio" 1233 "NKE Marine Elecronics" 1238 "SuperTrack Aps" 1239 "Honda Electronics Co., LTD" 1245 "Raritan Engineering Company, Inc" 1249 "Integrated Power Solutions AG" 1260 "Interactive Technologies, Inc." 1283 "LTG-Tech" 1299 "Energy Solutions (UK) LTD." 1300 "WATT Fuel Cell Corp" 1302 "Pro Mainer" 1305 "Dragonfly Energy" 1306 "Koden Electronics Co., Ltd" 1311 "Humphree AB" 1316 "Hinkley Yachts" 1317 "Global Marine Management GmbH (GMM)" 1320 "Triskel Marine Ltd" 1330 "Warwick Control Technologies" 1331 "Dolphin Charger" 1337 "Barnacle Systems Inc" 1348 "Radian IoT, Inc." 1353 "Ocean LED Marine Ltd" 1359 "BluNav" 1361 "OVA (Nantong Saiyang Electronics Co., Ltd)" 1368 "RAD Propulsion" 1369 "Electric Yacht" 1372 "Elco Motor Yachts" 1384 "Tecnoseal Foundry S.r.l" 1385 "Pro Charging Systems, LLC" 1389 "EVEX Co., LTD" 1398 "Gobius Sensor Technology AB" 1403 "Arco Marine" 1408 "Lenco Marine Inc." 1413 "Naocontrol S.L." 1417 "Revatek" 1438 "Aeolionics" 1439 "PredictWind Ltd" 1440 "Egis Mobile Electric" 1445 "Starboard Yacht Group" 1446 "Roswell Marine" 1451 "ePropulsion (Guangdong ePropulsion Technology Ltd.)" 1452 "Micro-Air LLC" 1453 "Vital Battery" 1458 "Ride Controller LLC" 1460 "Tocaro Blue" 1461 "Vanquish Yachts" 1471 "FT Technologies" 1478 "Alps Alpine Co., Ltd." 1481 "E-Force Marine" 1482 "CMC Marine" 1483 "Nanjing Sandemarine Information Technology Co., Ltd." 1850 "Teleflex Marine (SeaStar Solutions)" 1851 "Raymarine" 1852 "Navionics" 1853 "Japan Radio Co" 1854 "Northstar Technologies" 1855 "Furuno" 1856 "Trimble" 1857 "Simrad" 1858 "Litton" 1859 "Kvasar AB" 1860 "MMP" 1861 "Vector Cantech" 1862 "Yamaha Marine" 1863 "Faria Instruments" ;
VAL_ 2566854398 industryCode 0 "Global" 1 "Highway" 2 "Agriculture" 3 "Construction" 4 "Marine Industry" 5 "Industrial" ;
VAL_ 2566854398 manufacturerCode 69 "ARKS Enterprises, Inc." 78 "FW Murphy/Enovation Controls" 80 "Twin Disc" 85 "Kohler Power Systems" 88 "Hemisphere GPS Inc" 116 "BEP Marine" 135 "Airmar" 137 "Maretron" 140 "Lowrance" 144 "Mercury Marine" 147 "Nautibus Electronic GmbH" 148 "Blue Water Data" 154 "Westerbeke" 157 "ISSPRO Inc" 161 "Offshore Systems (UK) Ltd." 163 "Evinrude/BRP" 165 "CPAC Systems AB" 168 "Xantrex Technology Inc." 169 "Marlin Technologies, Inc." 172 "Yanmar Marine" 174 "Volvo Penta" 175 "Honda Marine" 176 "Carling Technologies Inc. (Moritz Aerospace)" 185 "Beede Instruments" 192 "Floscan Instrument Co. Inc." 193 "Nobletec" 198 "Mystic Valley Communications" 199 "Actia" 200 "Honda Marine 2" 201 "Disenos Y Technologia" 211 "Digital Switching Systems" 215 "Xintex/Atena" 224 "EMMI NETWORK S.L." 225 "Honda Marine 3" 228 "ZF" 229 "Garmin" 233 "Yacht Monitoring Solutions" 235 "Sailormade Marine Telemetry/Tetra Technology LTD" 243 "Eride" 250 "Honda Marine 4" 257 "Honda Motor Company LTD" 272 "Groco" 273 "Actisense" 274 "Amphenol LTW Technology" 275 "Navico" 283 "Hamilton Jet" 285 "Sea Recovery" 286 "Coelmo SRL Italy" 295 "BEP Marine 2" 304 "Empir Bus" 305 "NovAtel" 306 "Sleipner Motor AS" 307 "MBW Technologies" 311 "Fischer Panda" 315 "ICOM" 328 "Qwerty" 329 "Dief" 341 "Boening Automationstechnologie GmbH & Co. KG" 345 "Korean Maritime University" 351 "Thrane and Thrane" 355 "Mastervolt" 356 "Fischer Panda Generators" 358 "Victron Energy" 370 "Rolls Royce Marine" 373 "Electronic Design" 374 "Northern Lights" 378 "Glendinning" 381 "B & G" 384 "Rose Point Navigation Systems" 385 "Johnson Outdoors Marine Electronics Inc Geonav" 394 "Capi 2" 396 "Beyond Measure" 400 "Livorsi Marine" 404 "ComNav" 409 "Chetco" 419 "Fusion Electronics" 421 "Standard Horizon" 422 "True Heading AB" 426 "Egersund Marine Electronics AS" 427 "em-trak Marine Electronics" 431 "Tohatsu Co, JP" 437 "Digital Yacht" 438 "Comar Systems Limited" 440 "Cummins" 443 "VDO (aka Continental-Corporation)" 451 "Parker Hannifin aka Village Marine Tech" 459 "Alltek Marine Electronics Corp" 460 "SAN GIORGIO S.E.I.N" 466 "Veethree Electronics & Marine" 467 "Humminbird Marine Electronics" 470 "SI-TEX Marine Electronics" 471 "Sea Cross Marine AB" 475 "GME aka Standard Communications Pty LTD" 476 "Humminbird Marine Electronics 2" 478 "Ocean Sat BV" 481 "Chetco Digitial Instruments" 493 "Watcheye" 499 "Lcj Capteurs" 502 "Attwood Marine" 503 "Naviop S.R.L." 504 "Vesper Marine Ltd" 510 "Marinesoft Co. LTD" 513 "Simarine" 517 "NoLand Engineering" 518 "Transas USA" 529 "National Instruments Korea" 530 "National Marine Electronics Association" 532 "Onwa Marine" 540 "Webasto" 571 "Marinecraft (South Korea)" 573 "McMurdo Group aka Orolia LTD" 578 "Advansea" 579 "KVH" 580 "San Jose Technology" 583 "Yacht Control" 586 "Suzuki Motor Corporation" 591 "US Coast Guard" 595 "Ship Module aka Customware" 600 "Aquatic AV" 605 "Aventics GmbH" 606 "Intellian" 612 "SamwonIT" 614 "Arlt Tecnologies" 637 "Bavaria Yacts" 641 "Diverse Yacht Services" 644 "Wema U.S.A dba KUS" 645 "Garmin 2" 658 "Shenzhen Jiuzhou Himunication" 688 "Rockford Corp" 699 "Harman International" 704 "JL Audio" 708 "Lars Thrane" 715 "Autonnic" 717 "Yacht Devices" 734 "REAP Systems" 735 "Au Electronics Group" 739 "LxNav" 741 "Littelfuse, Inc (formerly Carling Technologies)" 743 "DaeMyung" 744 "Woosung" 748 "ISOTTA IFRA srl" 773 "Clarion US" 776 "HMI Systems" 777 "Ocean Signal" 778 "Seekeeper" 781 "Poly Planar" 785 "Fischer Panda DE" 795 "Broyda Industries" 796 "Canadian Automotive" 797 "Tides Marine" 798 "Lumishore" 799 "Still Water Designs and Audio" 802 "BJ Technologies (Beneteau)" 803 "Gill Sensors" 811 "Blue Water Desalination" 815 "FLIR" 824 "Undheim Systems" 826 "Lewmar Inc" 838 "TeamSurv" 844 "Fell Marine" 847 "Oceanvolt" 862 "Prospec" 868 "Data Panel Corp" 890 "L3 Technologies" 894 "Rhodan Marine Systems" 896 "Nexfour Solutions" 905 "ASA Electronics" 909 "Marines Co (South Korea)" 911 "Nautic-on" 917 "Sentinel" 929 "JL Marine ystems" 930 "Ecotronix" 944 "Zontisa Marine" 951 "EXOR International" 962 "Timbolier Industries" 963 "TJC Micro" 968 "Cox Powertrain" 969 "Blue Seas" 981 "Kobelt Manufacturing Co. Ltd" 992 "Blue Ocean IOT" 997 "Xenta Systems" 999 "Signal K" 1004 "Ultraflex SpA" 1008 "Lintest SmartBoat" 1011 "Soundmax" 1020 "Team Italia Marine (Onyx Marine Automation s.r.l)" 1021 "Entratech" 1022 "ITC Inc." 1029 "The Marine Guardian LLC" 1047 "Sonic Corporation" 1051 "ProNav" 1053 "Vetus Maxwell INC." 1056 "Lithium Pros" 1059 "Boatrax" 1062 "Marol Co ltd" 1065 "CALYPSO Instruments" 1066 "Spot Zero Water" 1069 "Lithionics Battery LLC" 1070 "Quick-teck Electronics Ltd" 1075 "Uniden America" 1083 "Nauticoncept" 1084 "Shadow-Caster LED lighting LLC" 1085 "Wet Sounds, LLC" 1088 "E-T-A Circuit Breakers" 1092 "Scheiber" 1100 "Smart Yachts International Limited" 1109 "Dockmate" 1114 "Bobs Machine" 1118 "L3Harris ASV" 1119 "Balmar LLC" 1120 "Elettromedia spa" 1127 "Electromaax" 1140 "Across Oceans Systems Ltd." 1145 "Kiwi Yachting" 1150 "BSB Artificial Intelligence GmbH" 1151 "Orca Technologoes AS" 1154 "TBS Electronics BV" 1158 "Technoton Electroics" 1160 "MG Energy Systems B.V." 1169 "Sea Macine Robotics Inc." 1171 "Vista Manufacturing" 1183 "Zipwake" 1186 "Sailmon BV" 1192 "Airmoniq Pro Kft" 1194 "Sierra Marine" 1200 "Xinuo Information Technology (Xiamen)" 1218 "Septentrio" 1233 "NKE Marine Elecronics" 1238 "SuperTrack Aps" 1239 "Honda Electronics Co., LTD" 1245 "Raritan Engineering Company, Inc" 1249 "Integrated Power Solutions AG" 1260 "Interactive Technologies, Inc." 1283 "LTG-Tech" 1299 "Energy Solutions (UK) LTD." 1300 "WATT Fuel Cell Corp" 1302 "Pro Mainer" 1305 "Dragonfly Energy" 1306 "Koden Electronics Co., Ltd" 1311 "Humphree AB" 1316 "Hinkley Yachts" 1317 "Global Marine Management GmbH (GMM)" 1320 "Triskel Marine Ltd" 1330 "Warwick Control Technologies" 1331 "Dolphin Charger" 1337 "Barnacle Systems Inc" 1348 "Radian IoT, Inc." 1353 "Ocean LED Marine Ltd" 1359 "BluNav" 1361 "OVA (Nantong Saiyang Electronics Co., Ltd)" 1368 "RAD Propulsion" 1369 "Electric Yacht" 1372 "Elco Motor Yachts" 1384 "Tecnoseal Foundry S.r.l" 1385 "Pro Charging Systems, LLC" 1389 "EVEX Co., LTD" 1398 "Gobius Sensor Technology AB" 1403 "Arco Marine" 1408 "Lenco Marine Inc." 1413 "Naocontrol S.L." 1417 "Revatek" 1438 "Aeolionics" 1439 "PredictWind Ltd" 1440 "Egis Mobile Electric" 1445 "Starboard Yacht Group" 1446 "Roswell Marine" 1451 "ePropulsion (Guangdong ePropulsion Technology Ltd.)" 1452 "Micro-Air LLC" 1453 "Vital Battery" 1458 "Ride Controller LLC" 1460 "Tocaro Blue" 1461 "Vanquish Yachts" 1471 "FT Technologies" 1478 "Alps Alpine Co., Ltd." 1481 "E-Force Marine" 1482 "CMC Marine" 1483 "Nanjing Sandemarine Information Technology Co., Ltd." 1850 "Teleflex Marine (SeaStar Solutions)" 1851 "Raymarine" 1852 "Navionics" 1853 "Japan Radio Co" 1854 "Northstar Technologies" 1855 "Furuno" 1856 "Trimble" 1857 "Simrad" 1858 "Litton" 1859 "Kvasar AB" 1860 "MMP" 1861 "Vector Cantech" 1862 "Yamaha Marine" 1863 "Faria Instruments" ;
VAL_ 2566854654 industryCode 0 "Global" 1 "Highway" 2 "Agriculture" 3 "Construction" 4 "Marine Industry" 5 "Industrial" ;
VAL_ 2566854654 manufacturerCode 69 "ARKS Enterprises, Inc." 78 "FW Murphy/Enovation Controls" 80 "Twin Disc" 85 "Kohler Power Systems" 88 "Hemisphere GPS Inc" 116 "BEP Marine" 135 "Airmar" 137 "Maretron" 140 "Lowrance" 144 "Mercury Marine" 147 "Nautibus Electronic GmbH" 148 "Blue Water Data" 154 "Westerbeke" 157 "ISSPRO Inc" 161 "Offshore Systems (UK) Ltd." 163 "Evinrude/BRP" 165 "CPAC Systems AB" 168 "Xantrex Technology Inc." 169 "Marlin Technologies, Inc." 172 "Yanmar Marine" 174 "Volvo Penta" 175 "Honda Marine" 176 "Carling Technologies Inc. (Moritz Aerospace)" 185 "Beede Instruments" 192 "Floscan Instrument Co. Inc." 193 "Nobletec" 198 "Mystic Valley Communications" 199 "Actia" 200 "Honda Marine 2" 201 "Disenos Y Technologia" 211 "Digital Switching Systems" 215 "Xintex/Atena" 224 "EMMI NETWORK S.L." 225 "Honda Marine 3" 228 "ZF" 229 "Garmin" 233 "Yacht Monitoring Solutions" 235 "Sailormade Marine Telemetry/Tetra Technology LTD" 243 "Eride" 250 "Honda Marine 4" 257 "Honda Motor Company LTD" 272 "Groco" 273 "Actisense" 274 "Amphenol LTW Technology" 275 "Navico" 283 "Hamilton Jet" 285 "Sea Recovery" 286 "Coelmo SRL Italy" 295 "BEP Marine 2" 304 "Empir Bus" 305 "NovAtel" 306 "Sleipner Motor AS" 307 "MBW Technologies" 311 "Fischer Panda" 315 "ICOM" 328 "Qwerty" 329 "Dief" 341 "Boening Automationstechnologie GmbH & Co. KG" 345 "Korean Maritime University" 351 "Thrane and Thrane" 355 "Mastervolt" 356 "Fischer Panda Generators" 358 "Victron Energy" 370 "Rolls Royce Marine" 373 "Electronic Design" 374 "Northern Lights" 378 "Glendinning" 381 "B & G" 384 "Rose Point Navigation Systems" 385 "Johnson Outdoors Marine Electronics Inc Geonav" 394 "Capi 2" 396 "Beyond Measure" 400 "Livorsi Marine" 404 "ComNav" 409 "Chetco" 419 "Fusion Electronics" 421 "Standard Horizon" 422 "True Heading AB" 426 "Egersund Marine Electronics AS" 427 "em-trak Marine Electronics" 431 "Tohatsu Co, JP" 437 "Digital Yacht" 438 "Comar Systems Limited" 440 "Cummins" 443 "VDO (aka Continental-Corporation)" 451 "Parker Hannifin aka Village Marine Tech" 459 "Alltek Marine Electronics Corp" 460 "SAN GIORGIO S.E.I.N" 466 "Veethree Electronics & Marine" 467 "Humminbird Marine Electronics" 470 "SI-TEX Marine Electronics" 471 "Sea Cross Marine AB" 475 "GME aka Standard Communications Pty LTD" 476 "Humminbird Marine Electronics 2" 478 "Ocean Sat BV" 481 "Chetco Digitial Instruments" 493 "Watcheye" 499 "Lcj Capteurs" 502 "Attwood Marine" 503 "Naviop S.R.L." 504 "Vesper Marine Ltd" 510 "Marinesoft Co. LTD" 513 "Simarine" 517 "NoLand Engineering" 518 "Transas USA" 529 "National Instruments Korea" 530 "National Marine Electronics Association" 532 "Onwa Marine" 540 "Webasto" 571 "Marinecraft (South Korea)" 573 "McMurdo Group aka Orolia LTD" 578 "Advansea" 579 "KVH" 580 "San Jose Technology" 583 "Yacht Control" 586 "Suzuki Motor Corporation" 591 "US Coast Guard" 595 "Ship Module aka Customware" 600 "Aquatic AV" 605 "Aventics GmbH" 606 "Intellian" 612 "SamwonIT" 614 "Arlt Tecnologies" 637 "Bavaria Yacts" 641 "Diverse Yacht Services" 644 "Wema U.S.A dba KUS" 645 "Garmin 2" 658 "Shenzhen Jiuzhou Himunication" 688 "Rockford Corp" 699 "Harman International" 704 "JL Audio" 708 "Lars Thrane" 715 "Autonnic" 717 "Yacht Devices" 734 "REAP Systems" 735 "Au Electronics Group" 739 "LxNav" 741 "Littelfuse, Inc (formerly Carling Technologies)" 743 "DaeMyung" 744 "Woosung" 748 "ISOTTA IFRA srl" 773 "Clarion US" 776 "HMI Systems" 777 "Ocean Signal" 778 "Seekeeper" 781 "Poly Planar" 785 "Fischer Panda DE" 795 "Broyda Industries" 796 "Canadian Automotive" 797 "Tides Marine" 798 "Lumishore" 799 "Still Water Designs and Audio" 802 "BJ Technologies (Beneteau)" 803 "Gill Sensors" 811 "Blue Water Desalination" 815 "FLIR" 824 "Undheim Systems" 826 "Lewmar Inc" 838 "TeamSurv" 844 "Fell Marine" 847 "Oceanvolt" 862 "Prospec" 868 "Data Panel Corp" 890 "L3 Technologies" 894 "Rhodan Marine Systems" 896 "Nexfour Solutions" 905 "ASA Electronics" 909 "Marines Co (South Korea)" 911 "Nautic-on" 917 "Sentinel" 929 "JL Marine ystems" 930 "Ecotronix" 944 "Zontisa Marine" 951 "EXOR International" 962 "Timbolier Industries" 963 "TJC Micro" 968 "Cox Powertrain" 969 "Blue Seas" 981 "Kobelt Manufacturing Co. Ltd" 992 "Blue Ocean IOT" 997 "Xenta Systems" 999 "Signal K" 1004 "Ultraflex SpA" 1008 "Lintest SmartBoat" 1011 "Soundmax" 1020 "Team Italia Marine (Onyx Marine Automation s.r.l)" 1021 "Entratech" 1022 "ITC Inc." 1029 "The Marine Guardian LLC" 1047 "Sonic Corporation" 1051 "ProNav" 1053 "Vetus Maxwell INC." 1056 "Lithium Pros" 1059 "Boatrax" 1062 "Marol Co ltd" 1065 "CALYPSO Instruments" 1066 "Spot Zero Water" 1069 "Lithionics Battery LLC" 1070 "Quick-teck Electronics Ltd" 1075 "Uniden America" 1083 "Nauticoncept" 1084 "Shadow-Caster LED lighting LLC" 1085 "Wet Sounds, LLC" 1088 "E-T-A Circuit Breakers" 1092 "Scheiber" 1100 "Smart Yachts International Limited" 1109 "Dockmate" 1114 "Bobs Machine" 1118 "L3Harris ASV" 1119 "Balmar LLC" 1120 "Elettromedia spa" 1127 "Electromaax" 1140 "Across Oceans Systems Ltd." 1145 "Kiwi Yachting" 1150 "BSB Artificial Intelligence GmbH" 1151 "Orca Technologoes AS" 1154 "TBS Electronics BV" 1158 "Technoton Electroics" 1160 "MG Energy Systems B.V." 1169 "Sea Macine Robotics Inc." 1171 "Vista Manufacturing" 1183 "Zipwake" 1186 "Sailmon BV" 1192 "Airmoniq Pro Kft" 1194 "Sierra Marine" 1200 "Xinuo Information Technology (Xiamen)" 1218 "Septentrio" 1233 "NKE Marine Elecronics" 1238 "SuperTrack Aps" 1239 "Honda Electronics Co., LTD" 1245 "Raritan Engineering Company, Inc" 1249 "Integrated Power Solutions AG" 1260 "Interactive Technologies, Inc." 1283 "LTG-Tech" 1299 "Energy Solutions (UK) LTD." 1300 "WATT Fuel Cell Corp" 1302 "Pro Mainer" 1305 "Dragonfly Energy" 1306 "Koden Electronics Co., Ltd" 1311 "Humphree AB" 1316 "Hinkley Yachts" 1317 "Global Marine Management GmbH (GMM)" 1320 "Triskel Marine Ltd" 1330 "Warwick Control Technologies" 1331 "Dolphin Charger" 1337 "Barnacle Systems Inc" 1348 "Radian IoT, Inc." 1353 "Ocean LED Marine Ltd" 1359 "BluNav" 1361 "OVA (Nantong Saiyang Electronics Co., Ltd)" 1368 "RAD Propulsion" 1369 "Electric Yacht" 1372 "Elco Motor Yachts" 1384 "Tecnoseal Foundry S.r.l" 1385 "Pro Charging Systems, LLC" 1389 "EVEX Co., LTD" 1398 "Gobius Sensor Technology AB" 1403 "Arco Marine" 1408 "Lenco Marine Inc." 1413 "Naocontrol S.L." 1417 "Revatek" 1438 "Aeolionics" 1439 "PredictWind Ltd" 1440 "Egis Mobile Electric" 1445 "Starboard Yacht Group" 1446 "Roswell Marine" 1451 "ePropulsion (Guangdong ePropulsion Technology Ltd.)" 1452 "Micro-Air LLC" 1453 "Vital Battery" 1458 "Ride Controller LLC" 1460 "Tocaro Blue" 1461 "Vanquish Yachts" 1471 "FT Technologies" 1478 "Alps Alpine Co., Ltd." 1481 "E-Force Marine" 1482 "CMC Marine" 1483 "Nanjing Sandemarine Information Technology Co., Ltd." 1850 "Teleflex Marine (SeaStar Solutions)" 1851 "Raymarine" 1852 "Navionics" 1853 "Japan Radio Co" 1854 "Northstar Technologies" 1855 "Furuno" 1856 "Trimble" 1857 "Simrad" 1858 "Litton" 1859 "Kvasar AB" 1860 "MMP" 1861 "Vector Cantech" 1862 "Yamaha Marine" 1863 "Faria Instruments" ;
VAL_ 2566855422 industryCode 0 "Global" 1 "Highway" 2 "Agriculture" 3 "Construction" 4 "Marine Industry" 5 "Industrial" ;
VAL_ 2566855422 manufacturerCode 69 "ARKS Enterprises, Inc." 78 "FW Murphy/Enovation Controls" 80 "Twin Disc" 85 "Kohler Power Systems" 88 "Hemisphere GPS Inc" 116 "BEP Marine" 135 "Airmar" 137 "Maretron" 140 "Lowrance" 144 "Mercury Marine" 147 "Nautibus Electronic GmbH" 148 "Blue Water Data" 154 "Westerbeke" 157 "ISSPRO Inc" 161 "Offshore Systems (UK) Ltd." 163 "Evinrude/BRP" 165 "CPAC Systems AB" 168 "Xantrex Technology Inc." 169 "Marlin Technologies, Inc." 172 "Yanmar Marine" 174 "Volvo Penta" 175 "Honda Marine" 176 "Carling Technologies Inc. (Moritz Aerospace)" 185 "Beede Instruments" 192 "Floscan Instrument Co. Inc." 193 "Nobletec" 198 "Mystic Valley Communications" 199 "Actia" 200 "Honda Marine 2" 201 "Disenos Y Technologia" 211 "Digital Switching Systems" 215 "Xintex/Atena" 224 "EMMI NETWORK S.L." 225 "Honda Marine 3" 228 "ZF" 229 "Garmin" 233 "Yacht Monitoring Solutions" 235 "Sailormade Marine Telemetry/Tetra Technology LTD" 243 "Eride" 250 "Honda Marine 4" 257 "Honda Motor Company LTD" 272 "Groco" 273 "Actisense" 274 "Amphenol LTW Technology" 275 "Navico" 283 "Hamilton Jet" 285 "Sea Recovery" 286 "Coelmo SRL Italy" 295 "BEP Marine 2" 304 "Empir Bus" 305 "NovAtel" 306 "Sleipner Motor AS" 307 "MBW Technologies" 311 "Fischer Panda" 315 "ICOM" 328 "Qwerty" 329 "Dief" 341 "Boening Automationstechnologie GmbH & Co. KG" 345 "Korean Maritime University" 351 "Thrane and Thrane" 355 "Mastervolt" 356 "Fischer Panda Generators" 358 "Victron Energy" 370 "Rolls Royce Marine" 373 "Electronic Design" 374 "Northern Lights" 378 "Glendinning" 381 "B & G" 384 "Rose Point Navigation Systems" 385 "Johnson Outdoors Marine Electronics Inc Geonav" 394 "Capi 2" 396 "Beyond Measure" 400 "Livorsi Marine" 404 "ComNav" 409 "Chetco" 419 "Fusion Electronics" 421 "Standard Horizon" 422 "True Heading AB" 426 "Egersund Marine Electronics AS" 427 "em-trak Marine Electronics" 431 "Tohatsu Co, JP" 437 "Digital Yacht" 438 "Comar Systems Limited" 440 "Cummins" 443 "VDO (aka Continental-Corporation)" 451 "Parker Hannifin aka Village Marine Tech" 459 "Alltek Marine Electronics Corp" 460 "SAN GIORGIO S.E.I.N" 466 "Veethree Electronics & Marine" 467 "Humminbird Marine Electronics" 470 "SI-TEX Marine Electronics" 471 "Sea Cross Marine AB" 475 "GME aka Standard Communications Pty LTD" 476 "Humminbird Marine Electronics 2" 478 "Ocean Sat BV" 481 "Chetco Digitial Instruments" 493 "Watcheye" 499 "Lcj Capteurs" 502 "Attwood Marine" 503 "Naviop S.R.L." 504 "Vesper Marine Ltd" 510 "Marinesoft Co. LTD" 513 "Simarine" 517 "NoLand Engineering" 518 "Transas USA" 529 "National Instruments Korea" 530 "National Marine Electronics Association" 532 "Onwa Marine" 540 "Webasto" 571 "Marinecraft (South Korea)" 573 "McMurdo Group aka Orolia LTD" 578 "Advansea" 579 "KVH" 580 "San Jose Technology" 583 "Yacht Control" 586 "Suzuki Motor Corporation" 591 "US Coast Guard" 595 "Ship Module aka Customware" 600 "Aquatic AV" 605 "Aventics GmbH" 606 "Intellian" 612 "SamwonIT" 614 "Arlt Tecnologies" 637 "Bavaria Yacts" 641 "Diverse Yacht Services" 644 "Wema U.S.A dba KUS" 645 "Garmin 2" 658 "Shenzhen Jiuzhou Himunication" 688 "Rockford Corp" 699 "Harman International" 704 "JL Audio" 708 "Lars Thrane" 715 "Autonnic" 717 "Yacht Devices" 734 "REAP Systems" 735 "Au Electronics Group" 739 "LxNav" 741 "Littelfuse, Inc (formerly Carling Technologies)" 743 "DaeMyung" 744 "Woosung" 748 "ISOTTA IFRA srl" 773 "Clarion US" 776 "HMI Systems" 777 "Ocean Signal" 778 "Seekeeper" 781 "Poly Planar" 785 "Fischer Panda DE" 795 "Broyda Industries" 796 "Canadian Automotive" 797 "Tides Marine" 798 "Lumishore" 799 "Still Water Designs and Audio" 802 "BJ Technologies (Beneteau)" 803 "Gill Sensors" 811 "Blue Water Desalination" 815 "FLIR" 824 "Undheim Systems" 826 "Lewmar Inc" 838 "TeamSurv" 844 "Fell Marine" 847 "Oceanvolt" 862 "Prospec" 868 "Data Panel Corp" 890 "L3 Technologies" 894 "Rhodan Marine Systems" 896 "Nexfour Solutions" 905 "ASA Electronics" 909 "Marines Co (South Korea)" 911 "Nautic-on" 917 "Sentinel" 929 "JL Marine ystems" 930 "Ecotronix" 944 "Zontisa Marine" 951 "EXOR International" 962 "Timbolier Industries" 963 "TJC Micro" 968 "Cox Powertrain" 969 "Blue Seas" 981 "Kobelt Manufacturing Co. Ltd" 992 "Blue Ocean IOT" 997 "Xenta Systems" 999 "Signal K" 1004 "Ultraflex SpA" 1008 "Lintest SmartBoat" 1011 "Soundmax" 1020 "Team Italia Marine (Onyx Marine Automation s.r.l)" 1021 "Entratech" 1022 "ITC Inc." 1029 "The Marine Guardian LLC" 1047 "Sonic Corporation" 1051 "ProNav" 1053 "Vetus Maxwell INC." 1056 "Lithium Pros" 1059 "Boatrax" 1062 "Marol Co ltd" 1065 "CALYPSO Instruments" 1066 "Spot Zero Water" 1069 "Lithionics Battery LLC" 1070 "Quick-teck Electronics Ltd" 1075 "Uniden America" 1083 "Nauticoncept" 1084 "Shadow-Caster LED lighting LLC" 1085 "Wet Sounds, LLC" 1088 "E-T-A Circuit Breakers" 1092 "Scheiber" 1100 "Smart Yachts International Limited" 1109 "Dockmate" 1114 "Bobs Machine" 1118 "L3Harris ASV" 1119 "Balmar LLC" 1120 "Elettromedia spa" 1127 "Electromaax" 1140 "Across Oceans Systems Ltd." 1145 "Kiwi Yachting" 1150 "BSB Artificial Intelligence GmbH" 1151 "Orca Technologoes AS" 1154 "TBS Electronics BV" 1158 "Technoton Electroics" 1160 "MG Energy Systems B.V." 1169 "Sea Macine Robotics Inc." 1171 "Vista Manufacturing" 1183 "Zipwake" 1186 "Sailmon BV" 1192 "Airmoniq Pro Kft" 1194 "Sierra Marine" 1200 "Xinuo Information Technology (Xiamen)" 1218 "Septentrio" 1233 "NKE Marine Elecronics" 1238 "SuperTrack Aps" 1239 "Honda Electronics Co., LTD" 1245 "Raritan Engineering Company, Inc" 1249 "Integrated Power Solutions AG" 1260 "Interactive Technologies, Inc." 1283 "LTG-Tech" 1299 "Energy Solutions (UK) LTD." 1300 "WATT Fuel Cell Corp" 1302 "Pro Mainer" 1305 "Dragonfly Energy" 1306 "Koden Electronics Co., Ltd" 1311 "Humphree AB" 1316 "Hinkley Yachts" 1317 "Global Marine Management GmbH (GMM)" 1320 "Triskel Marine Ltd" 1330 "Warwick Control Technologies" 1331 "Dolphin Charger" 1337 "Barnacle Systems Inc" 1348 "Radian IoT, Inc." 1353 "Ocean LED Marine Ltd" 1359 "BluNav" 1361 "OVA (Nantong Saiyang Electronics Co., Ltd)" 1368 "RAD Propulsion" 1369 "Electric Yacht" 1372 "Elco Motor Yachts" 1384 "Tecnoseal Foundry S.r.l" 1385 "Pro Charging Systems, LLC" 1389 "EVEX Co., LTD" 1398 "Gobius Sensor Technology AB" 1403 "Arco Marine" 1408 "Lenco Marine Inc." 1413 "Naocontrol S.L." 1417 "Revatek" 1438 "Aeolionics" 1439 "PredictWind Ltd" 1440 "Egis Mobile Electric" 1445 "Starboard Yacht Group" 1446 "Roswell Marine" 1451 "ePropulsion (Guangdong ePropulsion Technology Ltd.)" 1452 "Micro-Air LLC" 1453 "Vital Battery" 1458 "Ride Controller LLC" 1460 "Tocaro Blue" 1461 "Vanquish Yachts" 1471 "FT Technologies" 1478 "Alps Alpine Co., Ltd." 1481 "E-Force Marine" 1482 "CMC Marine" 1483 "Nanjing Sandemarine Information Technology Co., Ltd." 1850 "Teleflex Marine (SeaStar Solutions)" 1851 "Raymarine" 1852 "Navionics" 1853 "Japan Radio Co" 1854 "Northstar Technologies" 1855 "Furuno" 1856 "Trimble" 1857 "Simrad" 1858 "Litton" 1859 "Kvasar AB" 1860 "MMP" 1861 "Vector Cantech" 1862 "Yamaha Marine" 1863 "Faria Instruments" ;
VAL_ 2566855934 industryCode 0 "Global" 1 "Highway" 2 "Agriculture" 3 "Construction" 4 "Marine Industry" 5 "Industrial" ;
VAL_ 2566855934 manufacturerCode 69 "ARKS Enterprises, Inc." 78 "FW Murphy/Enovation Controls" 80 "Twin Disc" 85 "Kohler Power Systems" 88 "Hemisphere GPS Inc" 116 "BEP Marine" 135 "Airmar" 137 "Maretron" 140 "Lowrance" 144 "Mercury Marine" 147 "Nautibus Electronic GmbH" 148 "Blue Water Data" 154 "Westerbeke" 157 "ISSPRO Inc" 161 "Offshore Systems (UK) Ltd." 163 "Evinrude/BRP" 165 "CPAC Systems AB" 168 "Xantrex Technology Inc." 169 "Marlin Technologies, Inc." 172 "Yanmar Marine" 174 "Volvo Penta" 175 "Honda Marine" 176 "Carling Technologies Inc. (Moritz Aerospace)" 185 "Beede Instruments" 192 "Floscan Instrument Co. Inc." 193 "Nobletec" 198 "Mystic Valley Communications" 199 "Actia" 200 "Honda Marine 2" 201 "Disenos Y Technologia" 211 "Digital Switching Systems" 215 "Xintex/Atena" 224 "EMMI NETWORK S.L." 225 "Honda Marine 3" 228 "ZF" 229 "Garmin" 233 "Yacht Monitoring Solutions" 235 "Sailormade Marine Telemetry/Tetra Technology LTD" 243 "Eride" 250 "Honda Marine 4" 257 "Honda Motor Company LTD" 272 "Groco" 273 "Actisense" 274 "Amphenol LTW Technology" 275 "Navico" 283 "Hamilton Jet" 285 "Sea Recovery" 286 "Coelmo SRL Italy" 295 "BEP Marine 2" 304 "Empir Bus" 305 "NovAtel" 306 "Sleipner Motor AS" 307 "MBW Technologies" 311 "Fischer Panda" 315 "ICOM" 328 "Qwerty" 329 "Dief" 341 "Boening Automationstechnologie GmbH & Co. KG" 345 "Korean Maritime University" 351 "Thrane and Thrane" 355 "Mastervolt" 356 "Fischer Panda Generators" 358 "Victron Energy" 370 "Rolls Royce Marine" 373 "Electronic Design" 374 "Northern Lights" 378 "Glendinning" 381 "B & G" 384 "Rose Point Navigation Systems" 385 "Johnson Outdoors Marine Electronics Inc Geonav" 394 "Capi 2" 396 "Beyond Measure" 400 "Livorsi Marine" 404 "ComNav" 409 "Chetco" 419 "Fusion Electronics" 421 "Standard Horizon" 422 "True Heading AB" 426 "Egersund Marine Electronics AS" 427 "em-trak Marine Electronics" 431 "Tohatsu Co, JP" 437 "Digital Yacht" 438 "Comar Systems Limited" 440 "Cummins" 443 "VDO (aka Continental-Corporation)" 451 "Parker Hannifin aka Village Marine Tech" 459 "Alltek Marine Electronics Corp" 460 "SAN GIORGIO S.E.I.N" 466 "Veethree Electronics & Marine" 467 "Humminbird Marine Electronics" 470 "SI-TEX Marine Electronics" 471 "Sea Cross Marine AB" 475 "GME aka Standard Communications Pty LTD" 476 "Humminbird Marine Electronics 2" 478 "Ocean Sat BV" 481 "Chetco Digitial Instruments" 493 "Watcheye" 499 "Lcj Capteurs" 502 "Attwood Marine" 503 "Naviop S.R.L." 504 "Vesper Marine Ltd" 510 "Marinesoft Co. LTD" 513 "Simarine" 517 "NoLand Engineering" 518 "Transas USA" 529 "National Instruments Korea" 530 "National Marine Electronics Association" 532 "Onwa Marine" 540 "Webasto" 571 "Marinecraft (South Korea)" 573 "McMurdo Group aka Orolia LTD" 578 "Advansea" 579 "KVH" 580 "San Jose Technology" 583 "Yacht Control" 586 "Suzuki Motor Corporation" 591 "US Coast Guard" 595 "Ship Module aka Customware" 600 "Aquatic AV" 605 "Aventics GmbH" 606 "Intellian" 612 "SamwonIT" 614 "Arlt Tecnologies" 637 "Bavaria Yacts" 641 "Diverse Yacht Services" 644 "Wema U.S.A dba KUS" 645 "Garmin 2" 658 "Shenzhen Jiuzhou Himunication" 688 "Rockford Corp" 699 "Harman International" 704 "JL Audio" 708 "Lars Thrane" 715 "Autonnic" 717 "Yacht Devices" 734 "REAP Systems" 735 "Au Electronics Group" 739 "LxNav" 741 "Littelfuse, Inc (formerly Carling Technologies)" 743 "DaeMyung" 744 "Woosung" 748 "ISOTTA IFRA srl" 773 "Clarion US" 776 "HMI Systems" 777 "Ocean Signal" 778 "Seekeeper" 781 "Poly Planar" 785 "Fischer Panda DE" 795 "Broyda Industries" 796 "Canadian Automotive" 797 "Tides Marine" 798 "Lumishore" 799 "Still Water Designs and Audio" 802 "BJ Technologies (Beneteau)" 803 "Gill Sensors" 811 "Blue Water Desalination" 815 "FLIR" 824 "Undheim Systems" 826 "Lewmar Inc" 838 "TeamSurv" 844 "Fell Marine" 847 "Oceanvolt" 862 "Prospec" 868 "Data Panel Corp" 890 "L3 Technologies" 894 "Rhodan Marine Systems" 896 "Nexfour Solutions" 905 "ASA Electronics" 909 "Marines Co (South Korea)" 911 "Nautic-on" 917 "Sentinel" 929 "JL Marine ystems" 930 "Ecotronix" 944 "Zontisa Marine" 951 "EXOR International" 962 "Timbolier Industries" 963 "TJC Micro" 968 "Cox Powertrain" 969 "Blue Seas" 981 "Kobelt Manufacturing Co. Ltd" 992 "Blue Ocean IOT" 997 "Xenta Systems" 999 "Signal K" 1004 "Ultraflex SpA" 1008 "Lintest SmartBoat" 1011 "Soundmax" 1020 "Team Italia Marine (Onyx Marine Automation s.r.l)" 1021 "Entratech" 1022 "ITC Inc." 1029 "The Marine Guardian LLC" 1047 "Sonic Corporation" 1051 "ProNav" 1053 "Vetus Maxwell INC." 1056 "Lithium Pros" 1059 "Boatrax" 1062 "Marol Co ltd" 1065 "CALYPSO Instruments" 1066 "Spot Zero Water" 1069 "Lithionics Battery LLC" 1070 "Quick-teck Electronics Ltd" 1075 "Uniden America" 1083 "Nauticoncept" 1084 "Shadow-Caster LED lighting LLC" 1085 "Wet Sounds, LLC" 1088 "E-T-A Circuit Breakers" 1092 "Scheiber" 1100 "Smart Yachts International Limited" 1109 "Dockmate" 1114 "Bobs Machine" 1118 "L3Harris ASV" 1119 "Balmar LLC" 1120 "Elettromedia spa" 1127 "Electromaax" 1140 "Across Oceans Systems Ltd." 1145 "Kiwi Yachting" 1150 "BSB Artificial Intelligence GmbH" 1151 "Orca Technologoes AS" 1154 "TBS Electronics BV" 1158 "Technoton Electroics" 1160 "MG Energy Systems B.V." 1169 "Sea Macine Robotics Inc." 1171 "Vista Manufacturing" 1183 "Zipwake" 1186 "Sailmon BV" 1192 "Airmoniq Pro Kft" 1194 "Sierra Marine" 1200 "Xinuo Information Technology (Xiamen)" 1218 "Septentrio" 1233 "NKE Marine Elecronics" 1238 "SuperTrack Aps" 1239 "Honda Electronics Co., LTD" 1245 "Raritan Engineering Company, Inc" 1249 "Integrated Power Solutions AG" 1260 "Interactive Technologies, Inc." 1283 "LTG-Tech" 1299 "Energy Solutions (UK) LTD." 1300 "WATT Fuel Cell Corp" 1302 "Pro Mainer" 1305 "Dragonfly Energy" 1306 "Koden Electronics Co., Ltd" 1311 "Humphree AB" 1316 "Hinkley Yachts" 1317 "Global Marine Management GmbH (GMM)" 1320 "Triskel Marine Ltd" 1330 "Warwick Control Technologies" 1331 "Dolphin Charger" 1337 "Barnacle Systems Inc" 1348 "Radian IoT, Inc." 1353 "Ocean LED Marine Ltd" 1359 "BluNav" 1361 "OVA (Nantong Saiyang Electronics Co., Ltd)" 1368 "RAD Propulsion" 1369 "Electric Yacht" 1372 "Elco Motor Yachts" 1384 "Tecnoseal Foundry S.r.l" 1385 "Pro Charging Systems, LLC" 1389 "EVEX Co., LTD" 1398 "Gobius Sensor Technology AB" 1403 "Arco Marine" 1408 "Lenco Marine Inc." 1413 "Naocontrol S.L." 1417 "Revatek" 1438 "Aeolionics" 1439 "PredictWind Ltd" 1440 "Egis Mobile Electric" 1445 "Starboard Yacht Group" 1446 "Roswell Marine" 1451 "ePropulsion (Guangdong ePropulsion Technology Ltd.)" 1452 "Micro-Air LLC" 1453 "Vital Battery" 1458 "Ride Controller LLC" 1460 "Tocaro Blue" 1461 "Vanquish Yachts" 1471 "FT Technologies" 1478 "Alps Alpine Co., Ltd." 1481 "E-Force Marine" 1482 "CMC Marine" 1483 "Nanjing Sandemarine Information Technology Co., Ltd." 1850 "Teleflex Marine (SeaStar Solutions)" 1851 "Raymarine" 1852 "Navionics" 1853 "Japan Radio Co" 1854 "Northstar Technologies" 1855 "Furuno" 1856 "Trimble" 1857 "Simrad" 1858 "Litton" 1859 "Kvasar AB" 1860 "MMP" 1861 "Vector Cantech" 1862 "Yamaha Marine" 1863 "Faria Instruments" ;
VAL_ 2566856190 industryCode 0 "Global" 1 "Highway" 2 "Agriculture" 3 "Construction" 4 "Marine Industry" 5 "Industrial" ;
VAL_ 2566856190 manufacturerCode 69 "ARKS Enterprises, Inc." 78 "FW Murphy/Enovation Controls" 80 "Twin Disc" 85 "Kohler Power Systems" 88 "Hemisphere GPS Inc" 116 "BEP Marine" 135 "Airmar" 137 "Maretron" 140 "Lowrance" 144 "Mercury Marine" 147 "Nautibus Electronic GmbH" 148 "Blue Water Data" 154 "Westerbeke" 157 "ISSPRO Inc" 161 "Offshore Systems (UK) Ltd." 163 "Evinrude/BRP" 165 "CPAC Systems AB" 168 "Xantrex Technology Inc." 169 "Marlin Technologies, Inc." 172 "Yanmar Marine" 174 "Volvo Penta" 175 "Honda Marine" 176 "Carling Technologies Inc. (Moritz Aerospace)" 185 "Beede Instruments" 192 "Floscan Instrument Co. Inc." 193 "Nobletec" 198 "Mystic Valley Communications" 199 "Actia" 200 "Honda Marine 2" 201 "Disenos Y Technologia" 211 "Digital Switching Systems" 215 "Xintex/Atena" 224 "EMMI NETWORK S.L." 225 "Honda Marine 3" 228 "ZF" 229 "Garmin" 233 "Yacht Monitoring Solutions" 235 "Sailormade Marine Telemetry/Tetra Technology LTD" 243 "Eride" 250 "Honda Marine 4" 257 "Honda Motor Company LTD" 272 "Groco" 273 "Actisense" 274 "Amphenol LTW Technology" 275 "Navico" 283 "Hamilton Jet" 285 "Sea Recovery" 286 "Coelmo SRL Italy" 295 "BEP Marine 2" 304 "Empir Bus" 305 "NovAtel" 306 "Sleipner Motor AS" 307 "MBW Technologies" 311 "Fischer Panda" 315 "ICOM" 328 "Qwerty" 329 "Dief" 341 "Boening Automationstechnologie GmbH & Co. KG" 345 "Korean Maritime University" 351 "Thrane and Thrane" 355 "Mastervolt" 356 "Fischer Panda Generators" 358 "Victron Energy" 370 "Rolls Royce Marine" 373 "Electronic Design" 374 "Northern Lights" 378 "Glendinning" 381 "B & G" 384 "Rose Point Navigation Systems" 385 "Johnson Outdoors Marine Electronics Inc Geonav" 394 "Capi 2" 396 "Beyond Measure" 400 "Livorsi Marine" 404 "ComNav" 409 "Chetco" 419 "Fusion Electronics" 421 "Standard Horizon" 422 "True Heading AB" 426 "Egersund Marine Electronics AS" 427 "em-trak Marine Electronics" 431 "Tohatsu Co, JP" 437 "Digital Yacht" 438 "Comar Systems Limited" 440 "Cummins" 443 "VDO (aka Continental-Corporation)" 451 "Parker Hannifin aka Village Marine Tech" 459 "Alltek Marine Electronics Corp" 460 "SAN GIORGIO S.E.I.N" 466 "Veethree Electronics & Marine" 467 "Humminbird Marine Electronics" 470 "SI-TEX Marine Electronics" 471 "Sea Cross Marine AB" 475 "GME aka Standard Communications Pty LTD" 476 "Humminbird Marine Electronics 2" 478 "Ocean Sat BV" 481 "Chetco Digitial Instruments" 493 "Watcheye" 499 "Lcj Capteurs" 502 "Attwood Marine" 503 "Naviop S.R.L." 504 "Vesper Marine Ltd" 510 "Marinesoft Co. LTD" 513 "Simarine" 517 "NoLand Engineering" 518 "Transas USA" 529 "National Instruments Korea" 530 "National Marine Electronics Association" 532 "Onwa Marine" 540 "Webasto" 571 "Marinecraft (South Korea)" 573 "McMurdo Group aka Orolia LTD" 578 "Advansea" 579 "KVH" 580 "San Jose Technology" 583 "Yacht Control" 586 "Suzuki Motor Corporation" 591 "US Coast Guard" 595 "Ship Module aka Customware" 600 "Aquatic AV" 605 "Aventics GmbH" 606 "Intellian" 612 "SamwonIT" 614 "Arlt Tecnologies" 637 "Bavaria Yacts" 641 "Diverse Yacht Services" 644 "Wema U.S.A dba KUS" 645 "Garmin 2" 658 "Shenzhen Jiuzhou Himunication" 688 "Rockford Corp" 699 "Harman International" 704 "JL Audio" 708 "Lars Thrane" 715 "Autonnic" 717 "Yacht Devices" 734 "REAP Systems" 735 "Au Electronics Group" 739 "LxNav" 741 "Littelfuse, Inc (formerly Carling Technologies)" 743 "DaeMyung" 744 "Woosung" 748 "ISOTTA IFRA srl" 773 "Clarion US" 776 "HMI Systems" 777 "Ocean Signal" 778 "Seekeeper" 781 "Poly Planar" 785 "Fischer Panda DE" 795 "Broyda Industries" 796 "Canadian Automotive" 797 "Tides Marine" 798 "Lumishore" 799 "Still Water Designs and Audio" 802 "BJ Technologies (Beneteau)" 803 "Gill Sensors" 811 "Blue Water Desalination" 815 "FLIR" 824 "Undheim Systems" 826 "Lewmar Inc" 838 "TeamSurv" 844 "Fell Marine" 847 "Oceanvolt" 862 "Prospec" 868 "Data Panel Corp" 890 "L3 Technologies" 894 "Rhodan Marine Systems" 896 "Nexfour Solutions" 905 "ASA Electronics" 909 "Marines Co (South Korea)" 911 "Nautic-on" 917 "Sentinel" 929 "JL Marine ystems" 930 "Ecotronix" 944 "Zontisa Marine" 951 "EXOR International" 962 "Timbolier Industries" 963 "TJC Micro" 968 "Cox Powertrain" 969 "Blue Seas" 981 "Kobelt Manufacturing Co. Ltd" 992 "Blue Ocean IOT" 997 "Xenta Systems" 999 "Signal K" 1004 "Ultraflex SpA" 1008 "Lintest SmartBoat" 1011 "Soundmax" 1020 "Team Italia Marine (Onyx Marine Automation s.r.l)" 1021 "Entratech" 1022 "ITC Inc." 1029 "The Marine Guardian LLC" 1047 "Sonic Corporation" 1051 "ProNav" 1053 "Vetus Maxwell INC." 1056 "Lithium Pros" 1059 "Boatrax" 1062 "Marol Co ltd" 1065 "CALYPSO Instruments" 1066 "Spot Zero Water" 1069 "Lithionics Battery LLC" 1070 "Quick-teck Electronics Ltd" 1075 "Uniden America" 1083 "Nauticoncept" 1084 "Shadow-Caster LED lighting LLC" 1085 "Wet Sounds, LLC" 1088 "E-T-A Circuit Breakers" 1092 "Scheiber" 1100 "Smart Yachts International Limited" 1109 "Dockmate" 1114 "Bobs Machine" 1118 "L3Harris ASV" 1119 "Balmar LLC" 1120 "Elettromedia spa" 1127 "Electromaax" 1140 "Across Oceans Systems Ltd." 1145 "Kiwi Yachting" 1150 "BSB Artificial Intelligence GmbH" 1151 "Orca Technologoes AS" 1154 "TBS Electronics BV" 1158 "Technoton Electroics" 1160 "MG Energy Systems B.V." 1169 "Sea Macine Robotics Inc." 1171 "Vista Manufacturing" 1183 "Zipwake" 1186 "Sailmon BV" 1192 "Airmoniq Pro Kft" 1194 "Sierra Marine" 1200 "Xinuo Information Technology (Xiamen)" 1218 "Septentrio" 1233 "NKE Marine Elecronics" 1238 "SuperTrack Aps" 1239 "Honda Electronics Co., LTD" 1245 "Raritan Engineering Company, Inc" 1249 "Integrated Power Solutions AG" 1260 "Interactive Technologies, Inc." 1283 "LTG-Tech" 1299 "Energy Solutions (UK) LTD." 1300 "WATT Fuel Cell Corp" 1302 "Pro Mainer" 1305 "Dragonfly Energy" 1306 "Koden Electronics Co., Ltd" 1311 "Humphree AB" 1316 "Hinkley Yachts" 1317 "Global Marine Management GmbH (GMM)" 1320 "Triskel Marine Ltd" 1330 "Warwick Control Technologies" 1331 "Dolphin Charger" 1337 "Barnacle Systems Inc" 1348 "Radian IoT, Inc." 1353 "Ocean LED Marine Ltd" 1359 "BluNav" 1361 "OVA (Nantong Saiyang Electronics Co., Ltd)" 1368 "RAD Propulsion" 1369 "Electric Yacht" 1372 "Elco Motor Yachts" 1384 "Tecnoseal Foundry S.r.l" 1385 "Pro Charging Systems, LLC" 1389 "EVEX Co., LTD" 1398 "Gobius Sensor Technology AB" 1403 "Arco Marine" 1408 "Lenco Marine Inc." 1413 "Naocontrol S.L." 1417 "Revatek" 1438 "Aeolionics" 1439 "PredictWind Ltd" 1440 "Egis Mobile Electric" 1445 "Starboard Yacht Group" 1446 "Roswell Marine" 1451 "ePropulsion (Guangdong ePropulsion Technology Ltd.)" 1452 "Micro-Air LLC" 1453 "Vital Battery" 1458 "Ride Controller LLC" 1460 "Tocaro Blue" 1461 "Vanquish Yachts" 1471 "FT Technologies" 1478 "Alps Alpine Co., Ltd." 1481 "E-Force Marine" 1482 "CMC Marine" 1483 "Nanjing Sandemarine Information Technology Co., Ltd." 1850 "Teleflex Marine (SeaStar Solutions)" 1851 "Raymarine" 1852 "Navionics" 1853 "Japan Radio Co" 1854 "Northstar Technologies" 1855 "Furuno" 1856 "Trimble" 1857 "Simrad" 1858 "Litton" 1859 "Kvasar AB" 1860 "MMP" 1861 "Vector Cantech" 1862 "Yamaha Marine" 1863 "Faria Instruments" ;
VAL_ 2566856446 industryCode 0 "Global" 1 "Highway" 2 "Agriculture" 3 "Construction" 4 "Marine Industry" 5 "Industrial" ;
VAL_ 2566856446 manufacturerCode 69 "ARKS Enterprises, Inc." 78 "FW Murphy/Enovation Controls" 80 "Twin Disc" 85 "Kohler Power Systems" 88 "Hemisphere GPS Inc" 116 "BEP Marine" 135 "Airmar" 137 "Maretron" 140 "Lowrance" 144 "Mercury Marine" 147 "Nautibus Electronic GmbH" 148 "Blue Water Data" 154 "Westerbeke" 157 "ISSPRO Inc" 161 "Offshore Systems (UK) Ltd." 163 "Evinrude/BRP" 165 "CPAC Systems AB" 168 "Xantrex Technology Inc." 169 "Marlin Technologies, Inc." 172 "Yanmar Marine" 174 "Volvo Penta" 175 "Honda Marine" 176 "Carling Technologies Inc. (Moritz Aerospace)" 185 "Beede Instruments" 192 "Floscan Instrument Co. Inc." 193 "Nobletec" 198 "Mystic Valley Communications" 199 "Actia" 200 "Honda Marine 2" 201 "Disenos Y Technologia" 211 "Digital Switching Systems" 215 "Xintex/Atena" 224 "EMMI NETWORK S.L." 225 "Honda Marine 3" 228 "ZF" 229 "Garmin" 233 "Yacht Monitoring Solutions" 235 "Sailormade Marine Telemetry/Tetra Technology LTD" 243 "Eride" 250 "Honda Marine 4" 257 "Honda Motor Company LTD" 272 "Groco" 273 "Actisense" 274 "Amphenol LTW Technology" 275 "Navico" 283 "Hamilton Jet" 285 "Sea Recovery" 286 "Coelmo SRL Italy" 295 "BEP Marine 2" 304 "Empir Bus" 305 "NovAtel" 306 "Sleipner Motor AS" 307 "MBW Technologies" 311 "Fischer Panda" 315 "ICOM" 328 "Qwerty" 329 "Dief" 341 "Boening Automationstechnologie GmbH & Co. KG" 345 "Korean Maritime University" 351 "Thrane and Thrane" 355 "Mastervolt" 356 "Fischer Panda Generators" 358 "Victron Energy" 370 "Rolls Royce Marine" 373 "Electronic Design" 374 "Northern Lights" 378 "Glendinning" 381 "B & G" 384 "Rose Point Navigation Systems" 385 "Johnson Outdoors Marine Electronics Inc Geonav" 394 "Capi 2" 396 "Beyond Measure" 400 "Livorsi Marine" 404 "ComNav" 409 "Chetco" 419 "Fusion Electronics" 421 "Standard Horizon" 422 "True Heading AB" 426 "Egersund Marine Electronics AS" 427 "em-trak Marine Electronics" 431 "Tohatsu Co, JP" 437 "Digital Yacht" 438 "Comar Systems Limited" 440 "Cummins" 443 "VDO (aka Continental-Corporation)" 451 "Parker Hannifin aka Village Marine Tech" 459 "Alltek Marine Electronics Corp" 460 "SAN GIORGIO S.E.I.N" 466 "Veethree Electronics & Marine" 467 "Humminbird Marine Electronics" 470 "SI-TEX Marine Electronics" 471 "Sea Cross Marine AB" 475 "GME aka Standard Communications Pty LTD" 476 "Humminbird Marine Electronics 2" 478 "Ocean Sat BV" 481 "Chetco Digitial Instruments" 493 "Watcheye" 499 "Lcj Capteurs" 502 "Attwood Marine" 503 "Naviop S.R.L." 504 "Vesper Marine Ltd" 510 "Marinesoft Co. LTD" 513 "Simarine" 517 "NoLand Engineering" 518 "Transas USA" 529 "National Instruments Korea" 530 "National Marine Electronics Association" 532 "Onwa Marine" 540 "Webasto" 571 "Marinecraft (South Korea)" 573 "McMurdo Group aka Orolia LTD" 578 "Advansea" 579 "KVH" 580 "San Jose Technology" 583 "Yacht Control" 586 "Suzuki Motor Corporation" 591 "US Coast Guard" 595 "Ship Module aka Customware" 600 "Aquatic AV" 605 "Aventics GmbH" 606 "Intellian" 612 "SamwonIT" 614 "Arlt Tecnologies" 637 "Bavaria Yacts" 641 "Diverse Yacht Services" 644 "Wema U.S.A dba KUS" 645 "Garmin 2" 658 "Shenzhen Jiuzhou Himunication" 688 "Rockford Corp" 699 "Harman International" 704 "JL Audio" 708 "Lars Thrane" 715 "Autonnic" 717 "Yacht Devices" 734 "REAP Systems" 735 "Au Electronics Group" 739 "LxNav" 741 "Littelfuse, Inc (formerly Carling Technologies)" 743 "DaeMyung" 744 "Woosung" 748 "ISOTTA IFRA srl" 773 "Clarion US" 776 "HMI Systems" 777 "Ocean Signal" 778 "Seekeeper" 781 "Poly Planar" 785 "Fischer Panda DE" 795 "Broyda Industries" 796 "Canadian Automotive" 797 "Tides Marine" 798 "Lumishore" 799 "Still Water Designs and Audio" 802 "BJ Technologies (Beneteau)" 803 "Gill Sensors" 811 "Blue Water Desalination" 815 "FLIR" 824 "Undheim Systems" 826 "Lewmar Inc" 838 "TeamSurv" 844 "Fell Marine" 847 "Oceanvolt" 862 "Prospec" 868 "Data Panel Corp" 890 "L3 Technologies" 894 "Rhodan Marine Systems" 896 "Nexfour Solutions" 905 "ASA Electronics" 909 "Marines Co (South Korea)" 911 "Nautic-on" 917 "Sentinel" 929 "JL Marine ystems" 930 "Ecotronix" 944 "Zontisa Marine" 951 "EXOR International" 962 "Timbolier Industries" 963 "TJC Micro" 968 "Cox Powertrain" 969 "Blue Seas" 981 "Kobelt Manufacturing Co. Ltd" 992 "Blue Ocean IOT" 997 "Xenta Systems" 999 "Signal K" 1004 "Ultraflex SpA" 1008 "Lintest SmartBoat" 1011 "Soundmax" 1020 "Team Italia Marine (Onyx Marine Automation s.r.l)" 1021 "Entratech" 1022 "ITC Inc." 1029 "The Marine Guardian LLC" 1047 "Sonic Corporation" 1051 "ProNav" 1053 "Vetus Maxwell INC." 1056 "Lithium Pros" 1059 "Boatrax" 1062 "Marol Co ltd" 1065 "CALYPSO Instruments" 1066 "Spot Zero Water" 1069 "Lithionics Battery LLC" 1070 "Quick-teck Electronics Ltd" 1075 "Uniden America" 1083 "Nauticoncept" 1084 "Shadow-Caster LED lighting LLC" 1085 "Wet Sounds, LLC" 1088 "E-T-A Circuit Breakers" 1092 "Scheiber" 1100 "Smart Yachts International Limited" 1109 "Dockmate" 1114 "Bobs Machine" 1118 "L3Harris ASV" 1119 "Balmar LLC" 1120 "Elettromedia spa" 1127 "Electromaax" 1140 "Across Oceans Systems Ltd." 1145 "Kiwi Yachting" 1150 "BSB Artificial Intelligence GmbH" 1151 "Orca Technologoes AS" 1154 "TBS Electronics BV" 1158 "Technoton Electroics" 1160 "MG Energy Systems B.V." 1169 "Sea Macine Robotics Inc." 1171 "Vista Manufacturing" 1183 "Zipwake" 1186 "Sailmon BV" 1192 "Airmoniq Pro Kft" 1194 "Sierra Marine" 1200 "Xinuo Information Technology (Xiamen)" 1218 "Septentrio" 1233 "NKE Marine Elecronics" 1238 "SuperTrack Aps" 1239 "Honda Electronics Co., LTD" 1245 "Raritan Engineering Company, Inc" 1249 "Integrated Power Solutions AG" 1260 "Interactive Technologies, Inc." 1283 "LTG-Tech" 1299 "Energy Solutions (UK) LTD." 1300 "WATT Fuel Cell Corp" 1302 "Pro Mainer" 1305 "Dragonfly Energy" 1306 "Koden Electronics Co., Ltd" 1311 "Humphree AB" 1316 "Hinkley Yachts" 1317 "Global Marine Management GmbH (GMM)" 1320 "Triskel Marine Ltd" 1330 "Warwick Control Technologies" 1331 "Dolphin Charger" 1337 "Barnacle Systems Inc" 1348 "Radian IoT, Inc." 1353 "Ocean LED Marine Ltd" 1359 "BluNav" 1361 "OVA (Nantong Saiyang Electronics Co., Ltd)" 1368 "RAD Propulsion" 1369 "Electric Yacht" 1372 "Elco Motor Yachts" 1384 "Tecnoseal Foundry S.r.l" 1385 "Pro Charging Systems, LLC" 1389 "EVEX Co., LTD" 1398 "Gobius Sensor Technology AB" 1403 "Arco Marine" 1408 "Lenco Marine Inc." 1413 "Naocontrol S.L." 1417 "Revatek" 1438 "Aeolionics" 1439 "PredictWind Ltd" 1440 "Egis Mobile Electric" 1445 "Starboard Yacht Group" 1446 "Roswell Marine" 1451 "ePropulsion (Guangdong ePropulsion Technology Ltd.)" 1452 "Micro-Air LLC" 1453 "Vital Battery" 1458 "Ride Controller LLC" 1460 "Tocaro Blue" 1461 "Vanquish Yachts" 1471 "FT Technologies" 1478 "Alps Alpine Co., Ltd." 1481 "E-Force Marine" 1482 "CMC Marine" 1483 "Nanjing Sandemarine Information Technology Co., Ltd." 1850 "Teleflex Marine (SeaStar Solutions)" 1851 "Raymarine" 1852 "Navionics" 1853 "Japan Radio Co" 1854 "Northstar Technologies" 1855 "Furuno" 1856 "Trimble" 1857 "Simrad" 1858 "Litton" 1859 "Kvasar AB" 1860 "MMP" 1861 "Vector Cantech" 1862 "Yamaha Marine" 1863 "Faria Instruments" ;
VAL_ 2566856702 industryCode 0 "Global" 1 "Highway" 2 "Agriculture" 3 "Construction" 4 "Marine Industry" 5 "Industrial" ;
VAL_ 2566856702 manufacturerCode 69 "ARKS Enterprises, Inc." 78 "FW Murphy/Enovation Controls" 80 "Twin Disc" 85 "Kohler Power Systems" 88 "Hemisphere GPS Inc" 116 "BEP Marine" 135 "Airmar" 137 "Maretron" 140 "Lowrance" 144 "Mercury Marine" 147 "Nautibus Electronic GmbH" 148 "Blue Water Data" 154 "Westerbeke" 157 "ISSPRO Inc" 161 "Offshore Systems (UK) Ltd." 163 "Evinrude/BRP" 165 "CPAC Systems AB" 168 "Xantrex Technology Inc." 169 "Marlin Technologies, Inc." 172 "Yanmar Marine" 174 "Volvo Penta" 175 "Honda Marine" 176 "Carling Technologies Inc. (Moritz Aerospace)" 185 "Beede Instruments" 192 "Floscan Instrument Co. Inc." 193 "Nobletec" 198 "Mystic Valley Communications" 199 "Actia" 200 "Honda Marine 2" 201 "Disenos Y Technologia" 211 "Digital Switching Systems" 215 "Xintex/Atena" 224 "EMMI NETWORK S.L." 225 "Honda Marine 3" 228 "ZF" 229 "Garmin" 233 "Yacht Monitoring Solutions" 235 "Sailormade Marine Telemetry/Tetra Technology LTD" 243 "Eride" 250 "Honda Marine 4" 257 "Honda Motor Company LTD" 272 "Groco" 273 "Actisense" 274 "Amphenol LTW Technology" 275 "Navico" 283 "Hamilton Jet" 285 "Sea Recovery" 286 "Coelmo SRL Italy" 295 "BEP Marine 2" 304 "Empir Bus" 305 "NovAtel" 306 "Sleipner Motor AS" 307 "MBW Technologies" 311 "Fischer Panda" 315 "ICOM" 328 "Qwerty" 329 "Dief" 341 "Boening Automationstechnologie GmbH & Co. KG" 345 "Korean Maritime University" 351 "Thrane and Thrane" 355 "Mastervolt" 356 "Fischer Panda Generators" 358 "Victron Energy" 370 "Rolls Royce Marine" 373 "Electronic Design" 374 "Northern Lights" 378 "Glendinning" 381 "B & G" 384 "Rose Point Navigation Systems" 385 "Johnson Outdoors Marine Electronics Inc Geonav" 394 "Capi 2" 396 "Beyond Measure" 400 "Livorsi Marine" 404 "ComNav" 409 "Chetco" 419 "Fusion Electronics" 421 "Standard Horizon" 422 "True Heading AB" 426 "Egersund Marine Electronics AS" 427 "em-trak Marine Electronics" 431 "Tohatsu Co, JP" 437 "Digital Yacht" 438 "Comar Systems Limited" 440 "Cummins" 443 "VDO (aka Continental-Corporation)" 451 "Parker Hannifin aka Village Marine Tech" 459 "Alltek Marine Electronics Corp" 460 "SAN GIORGIO S.E.I.N" 466 "Veethree Electronics & Marine" 467 "Humminbird Marine Electronics" 470 "SI-TEX Marine Electronics" 471 "Sea Cross Marine AB" 475 "GME aka Standard Communications Pty LTD" 476 "Humminbird Marine Electronics 2" 478 "Ocean Sat BV" 481 "Chetco Digitial Instruments" 493 "Watcheye" 499 "Lcj Capteurs" 502 "Attwood Marine" 503 "Naviop S.R.L." 504 "Vesper Marine Ltd" 510 "Marinesoft Co. LTD" 513 "Simarine" 517 "NoLand Engineering" 518 "Transas USA" 529 "National Instruments Korea" 530 "National Marine Electronics Association" 532 "Onwa Marine" 540 "Webasto" 571 "Marinecraft (South Korea)" 573 "McMurdo Group aka Orolia LTD" 578 "Advansea" 579 "KVH" 580 "San Jose Technology" 583 "Yacht Control" 586 "Suzuki Motor Corporation" 591 "US Coast Guard" 595 "Ship Module aka Customware" 600 "Aquatic AV" 605 "Aventics GmbH" 606 "Intellian" 612 "SamwonIT" 614 "Arlt Tecnologies" 637 "Bavaria Yacts" 641 "Diverse Yacht Services" 644 "Wema U.S.A dba KUS" 645 "Garmin 2" 658 "Shenzhen Jiuzhou Himunication" 688 "Rockford Corp" 699 "Harman International" 704 "JL Audio" 708 "Lars Thrane" 715 "Autonnic" 717 "Yacht Devices" 734 "REAP Systems" 735 "Au Electronics Group" 739 "LxNav" 741 "Littelfuse, Inc (formerly Carling Technologies)" 743 "DaeMyung" 744 "Woosung" 748 "ISOTTA IFRA srl" 773 "Clarion US" 776 "HMI Systems" 777 "Ocean Signal" 778 "Seekeeper" 781 "Poly Planar" 785 "Fischer Panda DE" 795 "Broyda Industries" 796 "Canadian Automotive" 797 "Tides Marine" 798 "Lumishore" 799 "Still Water Designs and Audio" 802 "BJ Technologies (Beneteau)" 803 "Gill Sensors" 811 "Blue Water Desalination" 815 "FLIR" 824 "Undheim Systems" 826 "Lewmar Inc" 838 "TeamSurv" 844 "Fell Marine" 847 "Oceanvolt" 862 "Prospec" 868 "Data Panel Corp" 890 "L3 Technologies" 894 "Rhodan Marine Systems" 896 "Nexfour Solutions" 905 "ASA Electronics" 909 "Marines Co (South Korea)" 911 "Nautic-on" 917 "Sentinel" 929 "JL Marine ystems" 930 "Ecotronix" 944 "Zontisa Marine" 951 "EXOR International" 962 "Timbolier Industries" 963 "TJC Micro" 968 "Cox Powertrain" 969 "Blue Seas" 981 "Kobelt Manufacturing Co. Ltd" 992 "Blue Ocean IOT" 997 "Xenta Systems" 999 "Signal K" 1004 "Ultraflex SpA" 1008 "Lintest SmartBoat" 1011 "Soundmax" 1020 "Team Italia Marine (Onyx Marine Automation s.r.l)" 1021 "Entratech" 1022 "ITC Inc." 1029 "The Marine Guardian LLC" 1047 "Sonic Corporation" 1051 "ProNav" 1053 "Vetus Maxwell INC." 1056 "Lithium Pros" 1059 "Boatrax" 1062 "Marol Co ltd" 1065 "CALYPSO Instruments" 1066 "Spot Zero Water" 1069 "Lithionics Battery LLC" 1070 "Quick-teck Electronics Ltd" 1075 "Uniden America" 1083 "Nauticoncept" 1084 "Shadow-Caster LED lighting LLC" 1085 "Wet Sounds, LLC" 1088 "E-T-A Circuit Breakers" 1092 "Scheiber" 1100 "Smart Yachts International Limited" 1109 "Dockmate" 1114 "Bobs Machine" 1118 "L3Harris ASV" 1119 "Balmar LLC" 1120 "Elettromedia spa" 1127 "Electromaax" 1140 "Across Oceans Systems Ltd." 1145 "Kiwi Yachting" 1150 "BSB Artificial Intelligence GmbH" 1151 "Orca Technologoes AS" 1154 "TBS Electronics BV" 1158 "Technoton Electroics" 1160 "MG Energy Systems B.V." 1169 "Sea Macine Robotics Inc." 1171 "Vista Manufacturing" 1183 "Zipwake" 1186 "Sailmon BV" 1192 "Airmoniq Pro Kft" 1194 "Sierra Marine" 1200 "Xinuo Information Technology (Xiamen)" 1218 "Septentrio" 1233 "NKE Marine Elecronics" 1238 "SuperTrack Aps" 1239 "Honda Electronics Co., LTD" 1245 "Raritan Engineering Company, Inc" 1249 "Integrated Power Solutions AG" 1260 "Interactive Technologies, Inc." 1283 "LTG-Tech" 1299 "Energy Solutions (UK) LTD." 1300 "WATT Fuel Cell Corp" 1302 "Pro Mainer" 1305 "Dragonfly Energy" 1306 "Koden Electronics Co., Ltd" 1311 "Humphree AB" 1316 "Hinkley Yachts" 1317 "Global Marine Management GmbH (GMM)" 1320 "Triskel Marine Ltd" 1330 "Warwick Control Technologies" 1331 "Dolphin Charger" 1337 "Barnacle Systems Inc" 1348 "Radian IoT, Inc." 1353 "Ocean LED Marine Ltd" 1359 "BluNav" 1361 "OVA (Nantong Saiyang Electronics Co., Ltd)" 1368 "RAD Propulsion" 1369 "Electric Yacht" 1372 "Elco Motor Yachts" 1384 "Tecnoseal Foundry S.r.l" 1385 "Pro Charging Systems, LLC" 1389 "EVEX Co., LTD" 1398 "Gobius Sensor Technology AB" 1403 "Arco Marine" 1408 "Lenco Marine Inc." 1413 "Naocontrol S.L." 1417 "Revatek" 1438 "Aeolionics" 1439 "PredictWind Ltd" 1440 "Egis Mobile Electric" 1445 "Starboard Yacht Group" 1446 "Roswell Marine" 1451 "ePropulsion (Guangdong ePropulsion Technology Ltd.)" 1452 "Micro-Air LLC" 1453 "Vital Battery" 1458 "Ride Controller LLC" 1460 "Tocaro Blue" 1461 "Vanquish Yachts" 1471 "FT Technologies" 1478 "Alps Alpine Co., Ltd." 1481 "E-Force Marine" 1482 "CMC Marine" 1483 "Nanjing Sandemarine Information Technology Co., Ltd." 1850 "Teleflex Marine (SeaStar Solutions)" 1851 "Raymarine" 1852 "Navionics" 1853 "Japan Radio Co" 1854 "Northstar Technologies" 1855 "Furuno" 1856 "Trimble" 1857 "Simrad" 1858 "Litton" 1859 "Kvasar AB" 1860 "MMP" 1861 "Vector Cantech" 1862 "Yamaha Marine" 1863 "Faria Instruments" ;
VAL_ 2566856958 industryCode 0 "Global" 1 "Highway" 2 "Agriculture" 3 "Construction" 4 "Marine Industry" 5 "Industrial" ;
VAL_ 2566856958 manufacturerCode 69 "ARKS Enterprises, Inc." 78 "FW Murphy/Enovation Controls" 80 "Twin Disc" 85 "Kohler Power Systems" 88 "Hemisphere GPS Inc" 116 "BEP Marine" 135 "Airmar" 137 "Maretron" 140 "Lowrance" 144 "Mercury Marine" 147 "Nautibus Electronic GmbH" 148 "Blue Water Data" 154 "Westerbeke" 157 "ISSPRO Inc" 161 "Offshore Systems (UK) Ltd." 163 "Evinrude/BRP" 165 "CPAC Systems AB" 168 "Xantrex Technology Inc." 169 "Marlin Technologies, Inc." 172 "Yanmar Marine" 174 "Volvo Penta" 175 "Honda Marine" 176 "Carling Technologies Inc. (Moritz Aerospace)" 185 "Beede Instruments" 192 "Floscan Instrument Co. Inc." 193 "Nobletec" 198 "Mystic Valley Communications" 199 "Actia" 200 "Honda Marine 2" 201 "Disenos Y Technologia" 211 "Digital Switching Systems" 215 "Xintex/Atena" 224 "EMMI NETWORK S.L." 225 "Honda Marine 3" 228 "ZF" 229 "Garmin" 233 "Yacht Monitoring Solutions" 235 "Sailormade Marine Telemetry/Tetra Technology LTD" 243 "Eride" 250 "Honda Marine 4" 257 "Honda Motor Company LTD" 272 "Groco" 273 "Actisense" 274 "Amphenol LTW Technology" 275 "Navico" 283 "Hamilton Jet" 285 "Sea Recovery" 286 "Coelmo SRL Italy" 295 "BEP Marine 2" 304 "Empir Bus" 305 "NovAtel" 306 "Sleipner Motor AS" 307 "MBW Technologies" 311 "Fischer Panda" 315 "ICOM" 328 "Qwerty" 329 "Dief" 341 "Boening Automationstechnologie GmbH & Co. KG" 345 "Korean Maritime University" 351 "Thrane and Thrane" 355 "Mastervolt" 356 "Fischer Panda Generators" 358 "Victron Energy" 370 "Rolls Royce Marine" 373 "Electronic Design" 374 "Northern Lights" 378 "Glendinning" 381 "B & G" 384 "Rose Point Navigation Systems" 385 "Johnson Outdoors Marine Electronics Inc Geonav" 394 "Capi 2" 396 "Beyond Measure" 400 "Livorsi Marine" 404 "ComNav" 409 "Chetco" 419 "Fusion Electronics" 421 "Standard Horizon" 422 "True Heading AB" 426 "Egersund Marine Electronics AS" 427 "em-trak Marine Electronics" 431 "Tohatsu Co, JP" 437 "Digital Yacht" 438 "Comar Systems Limited" 440 "Cummins" 443 "VDO (aka Continental-Corporation)" 451 "Parker Hannifin aka Village Marine Tech" 459 "Alltek Marine Electronics Corp" 460 "SAN GIORGIO S.E.I.N" 466 "Veethree Electronics & Marine" 467 "Humminbird Marine Electronics" 470 "SI-TEX Marine Electronics" 471 "Sea Cross Marine AB" 475 "GME aka Standard Communications Pty LTD" 476 "Humminbird Marine Electronics 2" 478 "Ocean Sat BV" 481 "Chetco Digitial Instruments" 493 "Watcheye" 499 "Lcj Capteurs" 502 "Attwood Marine" 503 "Naviop S.R.L." 504 "Vesper Marine Ltd" 510 "Marinesoft Co. LTD" 513 "Simarine" 517 "NoLand Engineering" 518 "Transas USA" 529 "National Instruments Korea" 530 "National Marine Electronics Association" 532 "Onwa Marine" 540 "Webasto" 571 "Marinecraft (South Korea)" 573 "McMurdo Group aka Orolia LTD" 578 "Advansea" 579 "KVH" 580 "San Jose Technology" 583 "Yacht Control" 586 "Suzuki Motor Corporation" 591 "US Coast Guard" 595 "Ship Module aka Customware" 600 "Aquatic AV" 605 "Aventics GmbH" 606 "Intellian" 612 "SamwonIT" 614 "Arlt Tecnologies" 637 "Bavaria Yacts" 641 "Diverse Yacht Services" 644 "Wema U.S.A dba KUS" 645 "Garmin 2" 658 "Shenzhen Jiuzhou Himunication" 688 "Rockford Corp" 699 "Harman International" 704 "JL Audio" 708 "Lars Thrane" 715 "Autonnic" 717 "Yacht Devices" 734 "REAP Systems" 735 "Au Electronics Group" 739 "LxNav" 741 "Littelfuse, Inc (formerly Carling Technologies)" 743 "DaeMyung" 744 "Woosung" 748 "ISOTTA IFRA srl" 773 "Clarion US" 776 "HMI Systems" 777 "Ocean Signal" 778 "Seekeeper" 781 "Poly Planar" 785 "Fischer Panda DE" 795 "Broyda Industries" 796 "Canadian Automotive" 797 "Tides Marine" 798 "Lumishore" 799 "Still Water Designs and Audio" 802 "BJ Technologies (Beneteau)" 803 "Gill Sensors" 811 "Blue Water Desalination" 815 "FLIR" 824 "Undheim Systems" 826 "Lewmar Inc" 838 "TeamSurv" 844 "Fell Marine" 847 "Oceanvolt" 862 "Prospec" 868 "Data Panel Corp" 890 "L3 Technologies" 894 "Rhodan Marine Systems" 896 "Nexfour Solutions" 905 "ASA Electronics" 909 "Marines Co (South Korea)" 911 "Nautic-on" 917 "Sentinel" 929 "JL Marine ystems" 930 "Ecotronix" 944 "Zontisa Marine" 951 "EXOR International" 962 "Timbolier Industries" 963 "TJC Micro" 968 "Cox Powertrain" 969 "Blue Seas" 981 "Kobelt Manufacturing Co. Ltd" 992 "Blue Ocean IOT" 997 "Xenta Systems" 999 "Signal K" 1004 "Ultraflex SpA" 1008 "Lintest SmartBoat" 1011 "Soundmax" 1020 "Team Italia Marine (Onyx Marine Automation s.r.l)" 1021 "Entratech" 1022 "ITC Inc." 1029 "The Marine Guardian LLC" 1047 "Sonic Corporation" 1051 "ProNav" 1053 "Vetus Maxwell INC." 1056 "Lithium Pros" 1059 "Boatrax" 1062 "Marol Co ltd" 1065 "CALYPSO Instruments" 1066 "Spot Zero Water" 1069 "Lithionics Battery LLC" 1070 "Quick-teck Electronics Ltd" 1075 "Uniden America" 1083 "Nauticoncept" 1084 "Shadow-Caster LED lighting LLC" 1085 "Wet Sounds, LLC" 1088 "E-T-A Circuit Breakers" 1092 "Scheiber" 1100 "Smart Yachts International Limited" 1109 "Dockmate" 1114 "Bobs Machine" 1118 "L3Harris ASV" 1119 "Balmar LLC" 1120 "Elettromedia spa" 1127 "Electromaax" 1140 "Across Oceans Systems Ltd." 1145 "Kiwi Yachting" 1150 "BSB Artificial Intelligence GmbH" 1151 "Orca Technologoes AS" 1154 "TBS Electronics BV" 1158 "Technoton Electroics" 1160 "MG Energy Systems B.V." 1169 "Sea Macine Robotics Inc." 1171 "Vista Manufacturing" 1183 "Zipwake" 1186 "Sailmon BV" 1192 "Airmoniq Pro Kft" 1194 "Sierra Marine" 1200 "Xinuo Information Technology (Xiamen)" 1218 "Septentrio" 1233 "NKE Marine Elecronics" 1238 "SuperTrack Aps" 1239 "Honda Electronics Co., LTD" 1245 "Raritan Engineering Company, Inc" 1249 "Integrated Power Solutions AG" 1260 "Interactive Technologies, Inc." 1283 "LTG-Tech" 1299 "Energy Solutions (UK) LTD." 1300 "WATT Fuel Cell Corp" 1302 "Pro Mainer" 1305 "Dragonfly Energy" 1306 "Koden Electronics Co., Ltd" 1311 "Humphree AB" 1316 "Hinkley Yachts" 1317 "Global Marine Management GmbH (GMM)" 1320 "Triskel Marine Ltd" 1330 "Warwick Control Technologies" 1331 "Dolphin Charger" 1337 "Barnacle Systems Inc" 1348 "Radian IoT, Inc." 1353 "Ocean LED Marine Ltd" 1359 "BluNav" 1361 "OVA (Nantong Saiyang Electronics Co., Ltd)" 1368 "RAD Propulsion" 1369 "Electric Yacht" 1372 "Elco Motor Yachts" 1384 "Tecnoseal Foundry S.r.l" 1385 "Pro Charging Systems, LLC" 1389 "EVEX Co., LTD" 1398 "Gobius Sensor Technology AB" 1403 "Arco Marine" 1408 "Lenco Marine Inc." 1413 "Naocontrol S.L." 1417 "Revatek" 1438 "Aeolionics" 1439 "PredictWind Ltd" 1440 "Egis Mobile Electric" 1445 "Starboard Yacht Group" 1446 "Roswell Marine" 1451 "ePropulsion (Guangdong ePropulsion Technology Ltd.)" 1452 "Micro-Air LLC" 1453 "Vital Battery" 1458 "Ride Controller LLC" 1460 "Tocaro Blue" 1461 "Vanquish Yachts" 1471 "FT Technologies" 1478 "Alps Alpine Co., Ltd." 1481 "E-Force Marine" 1482 "CMC Marine" 1483 "Nanjing Sandemarine Information Technology Co., Ltd." 1850 "Teleflex Marine (SeaStar Solutions)" 1851 "Raymarine" 1852 "Navionics" 1853 "Japan Radio Co" 1854 "Northstar Technologies" 1855 "Furuno" 1856 "Trimble" 1857 "Simrad" 1858 "Litton" 1859 "Kvasar AB" 1860 "MMP" 1861 "Vector Cantech" 1862 "Yamaha Marine" 1863 "Faria Instruments" ;
VAL_ 2566857214 industryCode 0 "Global" 1 "Highway" 2 "Agriculture" 3 "Construction" 4 "Marine Industry" 5 "Industrial" ;
VAL_ 2566857214 manufacturerCode 69 "ARKS Enterprises, Inc." 78 "FW Murphy/Enovation Controls" 80 "Twin Disc" 85 "Kohler Power Systems" 88 "Hemisphere GPS Inc" 116 "BEP Marine" 135 "Airmar" 137 "Maretron" 140 "Lowrance" 144 "Mercury Marine" 147 "Nautibus Electronic GmbH" 148 "Blue Water Data" 154 "Westerbeke" 157 "ISSPRO Inc" 161 "Offshore Systems (UK) Ltd." 163 "Evinrude/BRP" 165 "CPAC Systems AB" 168 "Xantrex Technology Inc." 169 "Marlin Technologies, Inc." 172 "Yanmar Marine" 174 "Volvo Penta" 175 "Honda Marine" 176 "Carling Technologies Inc. (Moritz Aerospace)" 185 "Beede Instruments" 192 "Floscan Instrument Co. Inc." 193 "Nobletec" 198 "Mystic Valley Communications" 199 "Actia" 200 "Honda Marine 2" 201 "Disenos Y Technologia" 211 "Digital Switching Systems" 215 "Xintex/Atena" 224 "EMMI NETWORK S.L." 225 "Honda Marine 3" 228 "ZF" 229 "Garmin" 233 "Yacht Monitoring Solutions" 235 "Sailormade Marine Telemetry/Tetra Technology LTD" 243 "Eride" 250 "Honda Marine 4" 257 "Honda Motor Company LTD" 272 "Groco" 273 "Actisense" 274 "Amphenol LTW Technology" 275 "Navico" 283 "Hamilton Jet" 285 "Sea Recovery" 286 "Coelmo SRL Italy" 295 "BEP Marine 2" 304 "Empir Bus" 305 "NovAtel" 306 "Sleipner Motor AS" 307 "MBW Technologies" 311 "Fischer Panda" 315 "ICOM" 328 "Qwerty" 329 "Dief" 341 "Boening Automationstechnologie GmbH & Co. KG" 345 "Korean Maritime University" 351 "Thrane and Thrane" 355 "Mastervolt" 356 "Fischer Panda Generators" 358 "Victron Energy" 370 "Rolls Royce Marine" 373 "Electronic Design" 374 "Northern Lights" 378 "Glendinning" 381 "B & G" 384 "Rose Point Navigation Systems" 385 "Johnson Outdoors Marine Electronics Inc Geonav" 394 "Capi 2" 396 "Beyond Measure" 400 "Livorsi Marine" 404 "ComNav" 409 "Chetco" 419 "Fusion Electronics" 421 "Standard Horizon" 422 "True Heading AB" 426 "Egersund Marine Electronics AS" 427 "em-trak Marine Electronics" 431 "Tohatsu Co, JP" 437 "Digital Yacht" 438 "Comar Systems Limited" 440 "Cummins" 443 "VDO (aka Continental-Corporation)" 451 "Parker Hannifin aka Village Marine Tech" 459 "Alltek Marine Electronics Corp" 460 "SAN GIORGIO S.E.I.N" 466 "Veethree Electronics & Marine" 467 "Humminbird Marine Electronics" 470 "SI-TEX Marine Electronics" 471 "Sea Cross Marine AB" 475 "GME aka Standard Communications Pty LTD" 476 "Humminbird Marine Electronics 2" 478 "Ocean Sat BV" 481 "Chetco Digitial Instruments" 493 "Watcheye" 499 "Lcj Capteurs" 502 "Attwood Marine" 503 "Naviop S.R.L." 504 "Vesper Marine Ltd" 510 "Marinesoft Co. LTD" 513 "Simarine" 517 "NoLand Engineering" 518 "Transas USA" 529 "National Instruments Korea" 530 "National Marine Electronics Association" 532 "Onwa Marine" 540 "Webasto" 571 "Marinecraft (South Korea)" 573 "McMurdo Group aka Orolia LTD" 578 "Advansea" 579 "KVH" 580 "San Jose Technology" 583 "Yacht Control" 586 "Suzuki Motor Corporation" 591 "US Coast Guard" 595 "Ship Module aka Customware" 600 "Aquatic AV" 605 "Aventics GmbH" 606 "Intellian" 612 "SamwonIT" 614 "Arlt Tecnologies" 637 "Bavaria Yacts" 641 "Diverse Yacht Services" 644 "Wema U.S.A dba KUS" 645 "Garmin 2" 658 "Shenzhen Jiuzhou Himunication" 688 "Rockford Corp" 699 "Harman International" 704 "JL Audio" 708 "Lars Thrane" 715 "Autonnic" 717 "Yacht Devices" 734 "REAP Systems" 735 "Au Electronics Group" 739 "LxNav" 741 "Littelfuse, Inc (formerly Carling Technologies)" 743 "DaeMyung" 744 "Woosung" 748 "ISOTTA IFRA srl" 773 "Clarion US" 776 "HMI Systems" 777 "Ocean Signal" 778 "Seekeeper" 781 "Poly Planar" 785 "Fischer Panda DE" 795 "Broyda Industries" 796 "Canadian Automotive" 797 "Tides Marine" 798 "Lumishore" 799 "Still Water Designs and Audio" 802 "BJ Technologies (Beneteau)" 803 "Gill Sensors" 811 "Blue Water Desalination" 815 "FLIR" 824 "Undheim Systems" 826 "Lewmar Inc" 838 "TeamSurv" 844 "Fell Marine" 847 "Oceanvolt" 862 "Prospec" 868 "Data Panel Corp" 890 "L3 Technologies" 894 "Rhodan Marine Systems" 896 "Nexfour Solutions" 905 "ASA Electronics" 909 "Marines Co (South Korea)" 911 "Nautic-on" 917 "Sentinel" 929 "JL Marine ystems" 930 "Ecotronix" 944 "Zontisa Marine" 951 "EXOR International" 962 "Timbolier Industries" 963 "TJC Micro" 968 "Cox Powertrain" 969 "Blue Seas" 981 "Kobelt Manufacturing Co. Ltd" 992 "Blue Ocean IOT" 997 "Xenta Systems" 999 "Signal K" 1004 "Ultraflex SpA" 1008 "Lintest SmartBoat" 1011 "Soundmax" 1020 "Team Italia Marine (Onyx Marine Automation s.r.l)" 1021 "Entratech" 1022 "ITC Inc." 1029 "The Marine Guardian LLC" 1047 "Sonic Corporation" 1051 "ProNav" 1053 "Vetus Maxwell INC." 1056 "Lithium Pros" 1059 "Boatrax" 1062 "Marol Co ltd" 1065 "CALYPSO Instruments" 1066 "Spot Zero Water" 1069 "Lithionics Battery LLC" 1070 "Quick-teck Electronics Ltd" 1075 "Uniden America" 1083 "Nauticoncept" 1084 "Shadow-Caster LED lighting LLC" 1085 "Wet Sounds, LLC" 1088 "E-T-A Circuit Breakers" 1092 "Scheiber" 1100 "Smart Yachts International Limited" 1109 "Dockmate" 1114 "Bobs Machine" 1118 "L3Harris ASV" 1119 "Balmar LLC" 1120 "Elettromedia spa" 1127 "Electromaax" 1140 "Across Oceans Systems Ltd." 1145 "Kiwi Yachting" 1150 "BSB Artificial Intelligence GmbH" 1151 "Orca Technologoes AS" 1154 "TBS Electronics BV" 1158 "Technoton Electroics" 1160 "MG Energy Systems B.V." 1169 "Sea Macine Robotics Inc." 1171 "Vista Manufacturing" 1183 "Zipwake" 1186 "Sailmon BV" 1192 "Airmoniq Pro Kft" 1194 "Sierra Marine" 1200 "Xinuo Information Technology (Xiamen)" 1218 "Septentrio" 1233 "NKE Marine Elecronics" 1238 "SuperTrack Aps" 1239 "Honda Electronics Co., LTD" 1245 "Raritan Engineering Company, Inc" 1249 "Integrated Power Solutions AG" 1260 "Interactive Technologies, Inc." 1283 "LTG-Tech" 1299 "Energy Solutions (UK) LTD." 1300 "WATT Fuel Cell Corp" 1302 "Pro Mainer" 1305 "Dragonfly Energy" 1306 "Koden Electronics Co., Ltd" 1311 "Humphree AB" 1316 "Hinkley Yachts" 1317 "Global Marine Management GmbH (GMM)" 1320 "Triskel Marine Ltd" 1330 "Warwick Control Technologies" 1331 "Dolphin Charger" 1337 "Barnacle Systems Inc" 1348 "Radian IoT, Inc." 1353 "Ocean LED Marine Ltd" 1359 "BluNav" 1361 "OVA (Nantong Saiyang Electronics Co., Ltd)" 1368 "RAD Propulsion" 1369 "Electric Yacht" 1372 "Elco Motor Yachts" 1384 "Tecnoseal Foundry S.r.l" 1385 "Pro Charging Systems, LLC" 1389 "EVEX Co., LTD" 1398 "Gobius Sensor Technology AB" 1403 "Arco Marine" 1408 "Lenco Marine Inc." 1413 "Naocontrol S.L." 1417 "Revatek" 1438 "Aeolionics" 1439 "PredictWind Ltd" 1440 "Egis Mobile Electric" 1445 "Starboard Yacht Group" 1446 "Roswell Marine" 1451 "ePropulsion (Guangdong ePropulsion Technology Ltd.)" 1452 "Micro-Air LLC" 1453 "Vital Battery" 1458 "Ride Controller LLC" 1460 "Tocaro Blue" 1461 "Vanquish Yachts" 1471 "FT Technologies" 1478 "Alps Alpine Co., Ltd." 1481 "E-Force Marine" 1482 "CMC Marine" 1483 "Nanjing Sandemarine Information Technology Co., Ltd." 1850 "Teleflex Marine (SeaStar Solutions)" 1851 "Raymarine" 1852 "Navionics" 1853 "Japan Radio Co" 1854 "Northstar Technologies" 1855 "Furuno" 1856 "Trimble" 1857 "Simrad" 1858 "Litton" 1859 "Kvasar AB" 1860 "MMP" 1861 "Vector Cantech" 1862 "Yamaha Marine" 1863 "Faria Instruments" ;
VAL_ 2566857726 industryCode 0 "Global" 1 "Highway" 2 "Agriculture" 3 "Construction" 4 "Marine Industry" 5 "Industrial" ;
VAL_ 2566857726 manufacturerCode 69 "ARKS Enterprises, Inc." 78 "FW Murphy/Enovation Controls" 80 "Twin Disc" 85 "Kohler Power Systems" 88 "Hemisphere GPS Inc" 116 "BEP Marine" 135 "Airmar" 137 "Maretron" 140 "Lowrance" 144 "Mercury Marine" 147 "Nautibus Electronic GmbH" 148 "Blue Water Data" 154 "Westerbeke" 157 "ISSPRO Inc" 161 "Offshore Systems (UK) Ltd." 163 "Evinrude/BRP" 165 "CPAC Systems AB" 168 "Xantrex Technology Inc." 169 "Marlin Technologies, Inc." 172 "Yanmar Marine" 174 "Volvo Penta" 175 "Honda Marine" 176 "Carling Technologies Inc. (Moritz Aerospace)" 185 "Beede Instruments" 192 "Floscan Instrument Co. Inc." 193 "Nobletec" 198 "Mystic Valley Communications" 199 "Actia" 200 "Honda Marine 2" 201 "Disenos Y Technologia" 211 "Digital Switching Systems" 215 "Xintex/Atena" 224 "EMMI NETWORK S.L." 225 "Honda Marine 3" 228 "ZF" 229 "Garmin" 233 "Yacht Monitoring Solutions" 235 "Sailormade Marine Telemetry/Tetra Technology LTD" 243 "Eride" 250 "Honda Marine 4" 257 "Honda Motor Company LTD" 272 "Groco" 273 "Actisense" 274 "Amphenol LTW Technology" 275 "Navico" 283 "Hamilton Jet" 285 "Sea Recovery" 286 "Coelmo SRL Italy" 295 "BEP Marine 2" 304 "Empir Bus" 305 "NovAtel" 306 "Sleipner Motor AS" 307 "MBW Technologies" 311 "Fischer Panda" 315 "ICOM" 328 "Qwerty" 329 "Dief" 341 "Boening Automationstechnologie GmbH & Co. KG" 345 "Korean Maritime University" 351 "Thrane and Thrane" 355 "Mastervolt" 356 "Fischer Panda Generators" 358 "Victron Energy" 370 "Rolls Royce Marine" 373 "Electronic Design" 374 "Northern Lights" 378 "Glendinning" 381 "B & G" 384 "Rose Point Navigation Systems" 385 "Johnson Outdoors Marine Electronics Inc Geonav" 394 "Capi 2" 396 "Beyond Measure" 400 "Livorsi Marine" 404 "ComNav" 409 "Chetco" 419 "Fusion Electronics" 421 "Standard Horizon" 422 "True Heading AB" 426 "Egersund Marine Electronics AS" 427 "em-trak Marine Electronics" 431 "Tohatsu Co, JP" 437 "Digital Yacht" 438 "Comar Systems Limited" 440 "Cummins" 443 "VDO (aka Continental-Corporation)" 451 "Parker Hannifin aka Village Marine Tech" 459 "Alltek Marine Electronics Corp" 460 "SAN GIORGIO S.E.I.N" 466 "Veethree Electronics & Marine" 467 "Humminbird Marine Electronics" 470 "SI-TEX Marine Electronics" 471 "Sea Cross Marine AB" 475 "GME aka Standard Communications Pty LTD" 476 "Humminbird Marine Electronics 2" 478 "Ocean Sat BV" 481 "Chetco Digitial Instruments" 493 "Watcheye" 499 "Lcj Capteurs" 502 "Attwood Marine" 503 "Naviop S.R.L." 504 "Vesper Marine Ltd" 510 "Marinesoft Co. LTD" 513 "Simarine" 517 "NoLand Engineering" 518 "Transas USA" 529 "National Instruments Korea" 530 "National Marine Electronics Association" 532 "Onwa Marine" 540 "Webasto" 571 "Marinecraft (South Korea)" 573 "McMurdo Group aka Orolia LTD" 578 "Advansea" 579 "KVH" 580 "San Jose Technology" 583 "Yacht Control" 586 "Suzuki Motor Corporation" 591 "US Coast Guard" 595 "Ship Module aka Customware" 600 "Aquatic AV" 605 "Aventics GmbH" 606 "Intellian" 612 "SamwonIT" 614 "Arlt Tecnologies" 637 "Bavaria Yacts" 641 "Diverse Yacht Services" 644 "Wema U.S.A dba KUS" 645 "Garmin 2" 658 "Shenzhen Jiuzhou Himunication" 688 "Rockford Corp" 699 "Harman International" 704 "JL Audio" 708 "Lars Thrane" 715 "Autonnic" 717 "Yacht Devices" 734 "REAP Systems" 735 "Au Electronics Group" 739 "LxNav" 741 "Littelfuse, Inc (formerly Carling Technologies)" 743 "DaeMyung" 744 "Woosung" 748 "ISOTTA IFRA srl" 773 "Clarion US" 776 "HMI Systems" 777 "Ocean Signal" 778 "Seekeeper" 781 "Poly Planar" 785 "Fischer Panda DE" 795 "Broyda Industries" 796 "Canadian Automotive" 797 "Tides Marine" 798 "Lumishore" 799 "Still Water Designs and Audio" 802 "BJ Technologies (Beneteau)" 803 "Gill Sensors" 811 "Blue Water Desalination" 815 "FLIR" 824 "Undheim Systems" 826 "Lewmar Inc" 838 "TeamSurv" 844 "Fell Marine" 847 "Oceanvolt" 862 "Prospec" 868 "Data Panel Corp" 890 "L3 Technologies" 894 "Rhodan Marine Systems" 896 "Nexfour Solutions" 905 "ASA Electronics" 909 "Marines Co (South Korea)" 911 "Nautic-on" 917 "Sentinel" 929 "JL Marine ystems" 930 "Ecotronix" 944 "Zontisa Marine" 951 "EXOR International" 962 "Timbolier Industries" 963 "TJC Micro" 968 "Cox Powertrain" 969 "Blue Seas" 981 "Kobelt Manufacturing Co. Ltd" 992 "Blue Ocean IOT" 997 "Xenta Systems" 999 "Signal K" 1004 "Ultraflex SpA" 1008 "Lintest SmartBoat" 1011 "Soundmax" 1020 "Team Italia Marine (Onyx Marine Automation s.r.l)" 1021 "Entratech" 1022 "ITC Inc." 1029 "The Marine Guardian LLC" 1047 "Sonic Corporation" 1051 "ProNav" 1053 "Vetus Maxwell INC." 1056 "Lithium Pros" 1059 "Boatrax" 1062 "Marol Co ltd" 1065 "CALYPSO Instruments" 1066 "Spot Zero Water" 1069 "Lithionics Battery LLC" 1070 "Quick-teck Electronics Ltd" 1075 "Uniden America" 1083 "Nauticoncept" 1084 "Shadow-Caster LED lighting LLC" 1085 "Wet Sounds, LLC" 1088 "E-T-A Circuit Breakers" 1092 "Scheiber" 1100 "Smart Yachts International Limited" 1109 "Dockmate" 1114 "Bobs Machine" 1118 "L3Harris ASV" 1119 "Balmar LLC" 1120 "Elettromedia spa" 1127 "Electromaax" 1140 "Across Oceans Systems Ltd." 1145 "Kiwi Yachting" 1150 "BSB Artificial Intelligence GmbH" 1151 "Orca Technologoes AS" 1154 "TBS Electronics BV" 1158 "Technoton Electroics" 1160 "MG Energy Systems B.V." 1169 "Sea Macine Robotics Inc." 1171 "Vista Manufacturing" 1183 "Zipwake" 1186 "Sailmon BV" 1192 "Airmoniq Pro Kft" 1194 "Sierra Marine" 1200 "Xinuo Information Technology (Xiamen)" 1218 "Septentrio" 1233 "NKE Marine Elecronics" 1238 "SuperTrack Aps" 1239 "Honda Electronics Co., LTD" 1245 "Raritan Engineering Company, Inc" 1249 "Integrated Power Solutions AG" 1260 "Interactive Technologies, Inc." 1283 "LTG-Tech" 1299 "Energy Solutions (UK) LTD." 1300 "WATT Fuel Cell Corp" 1302 "Pro Mainer" 1305 "Dragonfly Energy" 1306 "Koden Electronics Co., Ltd" 1311 "Humphree AB" 1316 "Hinkley Yachts" 1317 "Global Marine Management GmbH (GMM)" 1320 "Triskel Marine Ltd" 1330 "Warwick Control Technologies" 1331 "Dolphin Charger" 1337 "Barnacle Systems Inc" 1348 "Radian IoT, Inc." 1353 "Ocean LED Marine Ltd" 1359 "BluNav" 1361 "OVA (Nantong Saiyang Electronics Co., Ltd)" 1368 "RAD Propulsion" 1369 "Electric Yacht" 1372 "Elco Motor Yachts" 1384 "Tecnoseal Foundry S.r.l" 1385 "Pro Charging Systems, LLC" 1389 "EVEX Co., LTD" 1398 "Gobius Sensor Technology AB" 1403 "Arco Marine" 1408 "Lenco Marine Inc." 1413 "Naocontrol S.L." 1417 "Revatek" 1438 "Aeolionics" 1439 "PredictWind Ltd" 1440 "Egis Mobile Electric" 1445 "Starboard Yacht Group" 1446 "Roswell Marine" 1451 "ePropulsion (Guangdong ePropulsion Technology Ltd.)" 1452 "Micro-Air LLC" 1453 "Vital Battery" 1458 "Ride Controller LLC" 1460 "Tocaro Blue" 1461 "Vanquish Yachts" 1471 "FT Technologies" 1478 "Alps Alpine Co., Ltd." 1481 "E-Force Marine" 1482 "CMC Marine" 1483 "Nanjing Sandemarine Information Technology Co., Ltd." 1850 "Teleflex Marine (SeaStar Solutions)" 1851 "Raymarine" 1852 "Navionics" 1853 "Japan Radio Co" 1854 "Northstar Technologies" 1855 "Furuno" 1856 "Trimble" 1857 "Simrad" 1858 "Litton" 1859 "Kvasar AB" 1860 "MMP" 1861 "Vector Cantech" 1862 "Yamaha Marine" 1863 "Faria Instruments" ;
